VERSION "created by canmatrix"

NS_ :

BS_:

BU_: RadarFrontCenter DASy MPC3
VAL_TABLE_ Status_AvoidCollision 3 "reserve" 2 "RightAvoid" 1 "LeftAvoid" 0 "None" ;
VAL_TABLE_ LAS_OverspeedWarningOffset 31 "Invalid" 21 "Reserved" 0 "Reserved" ;
VAL_TABLE_ VtiSig_VFC_RRLaneDistance 61 "reserved" 0 "0-12" ;
VAL_TABLE_ ACC_AEBActive 1 "Active" 0 "not Active" ;
VAL_TABLE_ VFC_ELKActiveSide 3 "RESERVED" 2 "SIDE_RI" 1 "SIDE_LE" 0 "SIDE_UNDEF" ;
VAL_TABLE_ RDR_Stat_Avail 15 "All function not available" 14 "TIPL&Traj&ongoing not available" 13 "TIPL&Traj&oncom not available" 12 "TIPL&Traj not available" 11 "TIPL&oncoming&ongo not available" 10 "Tipl&ongoing not available" 9 "Tipl&oncoming not available" 8 "TiPl not available" 7 "Traj&oncom&ongoing not available" 6 "Traj&Ongoing not available" 5 "Traj&Oncoming not available" 4 "TrajPoint not available" 3 "OnCom&Ongo obj not available" 2 "Ongoing obj not available" 1 "OnComing obj not available" 0 "Available" ;
VAL_TABLE_ VFC_SensorState_SWVersion 3 "reserved" 2 "unknown" 1 "above 150" 0 "FV150" ;

BO_ 3221225472 VECTOR__INDEPENDENT_SIG_MSG: 0 Vector__XXX
 SG_ CrDrLeInnrACRC : 0|8@1+ (1,0) [0|255] "" Vector__XXX
 SG_ CrDrLeInnrAMsgCtr : 0|4@1+ (1,0) [0|15] "" Vector__XXX
 SG_ CrDrLeInnrAblockCtr : 0|4@1+ (1,0) [0|15] "" Vector__XXX
 SG_ CrDrLeInnrCurvature : 0|12@1+ (1,-2047) [-2047|2048] "per_meter" Vector__XXX
 SG_ CrDrLeInnrCurvChange : 0|12@1+ (1,-2047) [-2047|2048] "per_square_meter" Vector__XXX
 SG_ CrDrLeInnrdxEnd : 0|9@1+ (0.25,0) [0|127.75] "Unit_Meter" Vector__XXX
 SG_ CrDrLeInnrBCRC : 0|8@1+ (1,0) [0|255] "" Vector__XXX
 SG_ CrDrLeInnrBMsgCtr : 0|4@1+ (1,0) [0|15] "" Vector__XXX
 SG_ CrDrLeInnrBblockCtr : 0|4@1+ (1,0) [0|15] "" Vector__XXX
 SG_ CrDrLeInnrdy : 0|12@1+ (0.00390625,-8) [-8|7.99609375] "Unit_Meter" Vector__XXX
 SG_ CrDrLeInnrYawAngleDiff : 0|12@1+ (0.000488281,-1) [-1|0.99951171875] "Radia" Vector__XXX
 SG_ CrDrLeInnr_existence_prob : 0|6@1+ (0.015625,0) [0|0.984375] "" Vector__XXX
 SG_ CrDrLeOutrACRC : 0|8@1+ (1,0) [0|255] "" Vector__XXX
 SG_ CrDrLeOutrAMsgCtr : 0|4@1+ (1,0) [0|15] "" Vector__XXX
 SG_ CrDrLeOutrAblockCtr : 0|4@1+ (1,0) [0|15] "" Vector__XXX
 SG_ CrDrLeOutrCurvature : 0|12@1+ (1,-2047) [-2047|2048] "per_meter" Vector__XXX
 SG_ CrDrLeOutrCurvChange : 0|12@1+ (1,-2047) [-2047|2048] "per_square_meter" Vector__XXX
 SG_ CrDrLeOutrdxEnd : 0|9@1+ (0.25,0) [0|127.75] "Unit_Meter" Vector__XXX
 SG_ CrDrLeOutrBCRC : 0|8@1+ (1,0) [0|255] "" Vector__XXX
 SG_ CrDrLeOutrBMsgCtr : 0|4@1+ (1,0) [0|15] "" Vector__XXX
 SG_ CrDrLeOutrBblockCtr : 0|4@1+ (1,0) [0|15] "" Vector__XXX
 SG_ CrDrLeOutrdy : 0|12@1+ (0.00390625,-8) [-8|7.99609375] "Unit_Meter" Vector__XXX
 SG_ CrDrLeOutrYawAngleDiff : 0|12@1+ (0.000488281,-1) [-1|0.99951171875] "Radia" Vector__XXX
 SG_ CrDrLeOutr_existence_prob : 0|6@1+ (0.015625,0) [0|0.984375] "" Vector__XXX
 SG_ CrDrRiInnrACRC : 0|8@1+ (1,0) [0|255] "" Vector__XXX
 SG_ CrDrRiInnrAMsgCtr : 0|4@1+ (1,0) [0|15] "" Vector__XXX
 SG_ CrDrRiInnrAblockCtr : 0|4@1+ (1,0) [0|15] "" Vector__XXX
 SG_ CrDrRiInnrCurvature : 0|12@1+ (1,-2047) [-2047|2048] "per_meter" Vector__XXX
 SG_ CrDrRiInnrCurvChange : 0|12@1+ (1,-2047) [-2047|2048] "per_square_meter" Vector__XXX
 SG_ CrDrRiInnrdxEnd : 0|9@1+ (0.25,0) [0|127.75] "Unit_Meter" Vector__XXX
 SG_ CrDrRiInnrBCRC : 0|8@1+ (1,0) [0|255] "" Vector__XXX
 SG_ CrDrRiInnrBMsgCtr : 0|4@1+ (1,0) [0|15] "" Vector__XXX
 SG_ CrDrRiInnrBblockCtr : 0|4@1+ (1,0) [0|15] "" Vector__XXX
 SG_ CrDrRiInnrdy : 0|12@1+ (0.00390625,-8) [-8|7.99609375] "Unit_Meter" Vector__XXX
 SG_ CrDrRiInnrYawAngleDiff : 0|12@1+ (0.000488281,-1) [-1|0.99951171875] "Radia" Vector__XXX
 SG_ CrDrRiInnr_existence_prob : 0|6@1+ (0.015625,0) [0|0.984375] "" Vector__XXX
 SG_ CrDrRiOutrACRC : 0|8@1+ (1,0) [0|255] "" Vector__XXX
 SG_ CrDrRiOutrAMsgCtr : 0|4@1+ (1,0) [0|15] "" Vector__XXX
 SG_ CrDrRiOutrAblockCtr : 0|4@1+ (1,0) [0|15] "" Vector__XXX
 SG_ CrDrRiOutrCurvature : 0|12@1+ (1,-2047) [-2047|2048] "per_meter" Vector__XXX
 SG_ CrDrRiOutrCurvChange : 0|12@1+ (1,-2047) [-2047|2048] "per_square_meter" Vector__XXX
 SG_ CrDrRiOutrdxEnd : 0|9@1+ (0.25,0) [0|127.75] "Unit_Meter" Vector__XXX
 SG_ CrDrRiOutrBCRC : 0|8@1+ (1,0) [0|255] "" Vector__XXX
 SG_ CrDrRiOutrBMsgCtr : 0|4@1+ (1,0) [0|15] "" Vector__XXX
 SG_ CrDrRiOutrBblockCtr : 0|4@1+ (1,0) [0|15] "" Vector__XXX
 SG_ CrDrRiOutrdy : 0|12@1+ (0.00390625,-8) [-8|7.99609375] "Unit_Meter" Vector__XXX
 SG_ CrDrRiOutrYawAngleDiff : 0|12@1+ (0.000488281,-1) [-1|0.99951171875] "Radia" Vector__XXX
 SG_ CrDrRiOutr_existence_prob : 0|6@1+ (0.015625,0) [0|0.984375] "" Vector__XXX
 SG_ TargetTrajBCRC : 0|8@1+ (1,0) [0|255] "" Vector__XXX
 SG_ TargetTrajBMsgCtr : 0|4@1+ (1,0) [0|15] "" Vector__XXX
 SG_ TargetTrajBblockCtr : 0|4@1+ (1,0) [0|15] "" Vector__XXX
 SG_ TargetTrajExistnceProb : 0|6@1+ (0.015625,0) [0|0.984375] "" Vector__XXX
 SG_ TargetTrajYawAngleDiff : 0|12@1+ (0.000488281,-1) [-1|0.99951171875] "Radia" Vector__XXX
 SG_ TargetTrajDy : 0|12@1+ (0.00390625,-8) [-8|7.99609375] "Unit_Meter" Vector__XXX
 SG_ RDR_Oncoming_Obj_ChkSum : 0|8@1+ (1,0) [0|255] "" Vector__XXX
 SG_ RDR_OncomingObj_MsgCnt : 0|4@1+ (1,0) [0|15] "" Vector__XXX
 SG_ RDR_OncomingObj_BlockCnt : 0|4@1+ (1,0) [0|15] "" Vector__XXX
 SG_ RDR_Obj_02_dWidth : 0|5@1+ (0.1,0) [0|3.1] "" Vector__XXX
 SG_ RDR_Obj_03_dWidth : 0|5@1+ (0.1,0) [0|3.1] "" Vector__XXX
 SG_ RDR_Obj_04_dWidth : 0|5@1+ (0.1,0) [0|3.1] "" Vector__XXX
 SG_ RDR_Obj_05_dWidth : 0|5@1+ (0.1,0) [0|3.1] "" Vector__XXX
 SG_ VFC_MapInfo_CRC : 0|16@1+ (1,0) [0|65535] "" Vector__XXX
 SG_ VFC_MapInfo_RoadCurv : 0|12@1+ (2E-005,-0.04094) [-0.04094|0.04096] "1/m" Vector__XXX
 SG_ VFC_MapInfo_CountryCode : 0|10@1+ (1,0) [0|1023] "" Vector__XXX
 SG_ VFC_MapInfo_AliveCtr : 0|8@1+ (1,0) [0|255] "" Vector__XXX
 SG_ VFC_MapInfo_RoadClass_Offset0 : 0|3@1+ (1,0) [0|7] "" Vector__XXX
 SG_ VFC_MapInfo_RoadClass_Offset200 : 0|3@1+ (1,0) [0|7] "" Vector__XXX
 SG_ VFC_MapInfo_DiRoad_Offset0 : 0|2@1+ (1,0) [0|3] "" Vector__XXX
 SG_ VFC_MapInfo_LaneNum_Offset0 : 0|3@1+ (1,0) [0|7] "" Vector__XXX
 SG_ VFC_MapInfo_LaneNum_Offset200 : 0|3@1+ (1,0) [0|7] "" Vector__XXX
 SG_ VFC_MapInfo_DiRoad_Offset200 : 0|2@1+ (1,0) [0|3] "" Vector__XXX
 SG_ VFC_MapInfo_TollGate_Dx : 0|10@1+ (1,0) [0|1023] "m" Vector__XXX
 SG_ VFC_MapInfo_TollGate : 0|2@1+ (1,0) [0|3] "" Vector__XXX
 SG_ VFC_MapInfo_CurrentLane : 0|3@1+ (1,0) [0|7] "" Vector__XXX
 SG_ VFC_MapInfo_Tunnel_Dx : 0|10@1+ (1,0) [0|1023] "m" Vector__XXX
 SG_ VFC_MapInfo_Tunnel : 0|2@1+ (1,0) [0|3] "" Vector__XXX
 SG_ VFC_MapInfo_Bridge_Dx : 0|10@1+ (1,0) [0|1023] "m" Vector__XXX
 SG_ VFC_MapInfo_Bridge : 0|2@1+ (1,0) [0|3] "" Vector__XXX
 SG_ VFC_MapInfo_BuildUp_Dx : 0|10@1+ (1,0) [0|1023] "m" Vector__XXX
 SG_ VFC_MapInfo_BuildUp : 0|2@1+ (1,0) [0|3] "" Vector__XXX

BO_ 0 New_Message_104: 8 Vector__XXX
 SG_ New_Signal_2281 : 55|8@1+ (1,0) [0|0] "" Vector__XXX

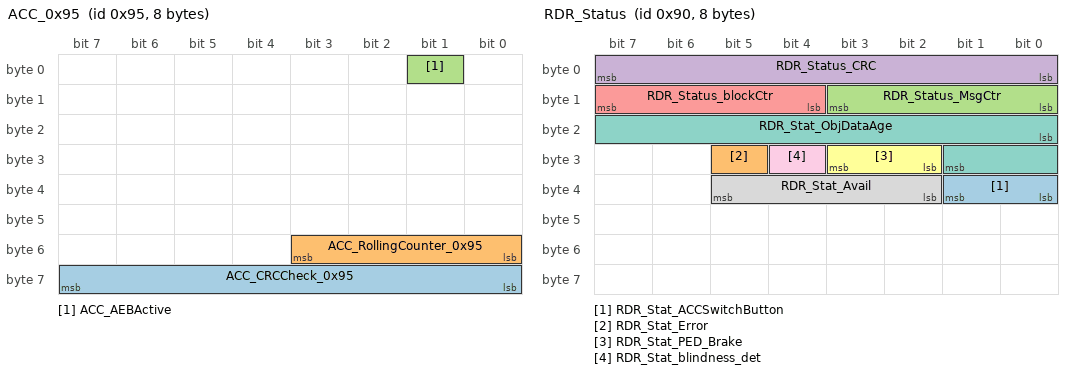
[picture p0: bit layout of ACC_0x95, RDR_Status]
BO_ 149 ACC_0x95: 8 RadarFrontCenter
 SG_ ACC_CRCCheck_0x95 : 63|8@0+ (1,0) [0|255] ""  MPC3
 SG_ ACC_RollingCounter_0x95 : 51|4@0+ (1,0) [0|15] ""  MPC3
 SG_ ACC_AEBActive : 1|1@0+ (1,0) [0|1] ""  MPC3

BO_ 144 RDR_Status: 8 RadarFrontCenter
 SG_ RDR_Stat_ACCSwitchButton : 32|2@1+ (1,0) [0|3] ""  MPC3
 SG_ RDR_Stat_Error : 29|1@1+ (1,0) [0|1] ""  MPC3
 SG_ RDR_Status_MsgCtr : 8|4@1+ (1,0) [0|15] ""  MPC3
 SG_ RDR_Status_CRC : 0|8@1+ (1,0) [0|255] ""  MPC3
 SG_ RDR_Status_blockCtr : 12|4@1+ (1,0) [0|15] ""  MPC3
 SG_ RDR_Stat_PED_Brake : 26|2@1+ (1,0) [0|3] ""  MPC3
 SG_ RDR_Stat_ObjDataAge : 16|10@1+ (0.0009765625,0) [0|0.9990234375] ""  MPC3
 SG_ RDR_Stat_Avail : 34|4@1+ (1,0) [0|15] ""  MPC3
 SG_ RDR_Stat_blindness_det : 28|1@1+ (1,0) [0|1] ""  MPC3

BO_ 80 VFC_SensorState: 12 MPC3
 SG_ VFC_SensorState_SWVersion : 70|2@1+ (1,0) [0|3] ""  RadarFrontCenter
 SG_ VFC_SensorState_CRC : 0|16@1+ (1,0) [0|65535] ""  RadarFrontCenter,DASy
 SG_ VFC_SensorState_AliveCtr : 16|8@1+ (1,0) [0|255] ""  RadarFrontCenter,DASy
 SG_ VFC_SensorState_BlindnessProb : 24|6@1+ (2,0) [0|100] "%"  RadarFrontCenter,DASy
 SG_ VFC_SensorState_VisionFault : 32|3@1+ (1,0) [0|7] ""  RadarFrontCenter,DASy
 SG_ VFC_SensorState_VisionDTCs : 35|3@1+ (1,0) [0|7] ""  RadarFrontCenter,DASy
 SG_ VFC_SensorState_Status : 40|3@1+ (1,0) [0|7] ""  RadarFrontCenter,DASy
 SG_ VFC_SensorState_ProtocolVersion : 48|16@1+ (1,0) [0|65535] ""  RadarFrontCenter,DASy
 SG_ VFC_SensorState_Report : 64|6@1+ (1,0) [0|63] ""  RadarFrontCenter,DASy

BO_ 128 VFC_LineHeader: 16 MPC3
 SG_ VFC_LineHdr_CRC : 0|16@1+ (1,0) [0|65535] ""  RadarFrontCenter,DASy
 SG_ VFC_LineHdr_AliveCtr : 16|8@1+ (1,0) [0|255] ""  RadarFrontCenter,DASy
 SG_ VFC_LineHdr_BlockCounter : 24|4@1+ (1,0) [0|15] ""  RadarFrontCenter,DASy
 SG_ VFC_LineHdr_FrameNo : 28|4@1+ (1,0) [0|15] ""  RadarFrontCenter,DASy
 SG_ VFC_LineHdr_Report : 32|8@1+ (1,0) [0|255] ""  RadarFrontCenter,DASy
 SG_ VFC_LineHdr_LineCount : 40|8@1+ (1,0) [0|255] ""  RadarFrontCenter,DASy
 SG_ VFC_LineHdr_PEPSIRuntime : 48|8@1+ (0.05,0) [0|10] "ms"  RadarFrontCenter,DASy
 SG_ VFC_LineHdr_TimeStamp : 56|26@1+ (1,0) [0|67108863] "ms"  RadarFrontCenter,DASy
 SG_ VFC_LineHdr_Blindness : 82|6@1+ (2,0) [0|100] "%"  RadarFrontCenter,DASy
 SG_ VFC_LineHdr_State : 88|3@1+ (1,0) [0|7] ""  RadarFrontCenter,DASy
 SG_ VFC_LineHdr_AUTOSARTStamp : 96|26@1+ (1,0) [0|67108863] "ms"  RadarFrontCenter,DASy

BO_ 129 VFC_Line01: 32 MPC3
 SG_ VFC_Line01_CRC : 0|16@1+ (1,0) [0|65535] ""  RadarFrontCenter,DASy
 SG_ VFC_Line01_Dy : 104|12@1+ (0.015625,-32) [-32|31.984375] "m"  RadarFrontCenter,DASy
 SG_ VFC_Line01_CurvChange : 116|12@1+ (3.8147E-006,-0.0078125) [-0.0078125|0.0078086965] "1/(m*m)"  RadarFrontCenter,DASy
 SG_ VFC_Line01_Curv : 128|13@1+ (3.8147E-006,-0.015625) [-0.015625|0.0156212077] "1/m"  RadarFrontCenter,DASy
 SG_ VFC_Line01_MeasureType : 141|3@1+ (1,0) [0|3] ""  RadarFrontCenter,DASy
 SG_ VFC_Line01_LineWidth : 144|8@1+ (0.01,0) [0|2.55] "m"  RadarFrontCenter,DASy
 SG_ VFC_Line01_CourseDeviation : 152|10@1+ (0.05,0) [0|50] ""  RadarFrontCenter,DASy
 SG_ VFC_Line01_Type : 162|5@1+ (1,0) [0|31] ""  RadarFrontCenter,DASy
 SG_ VFC_Line01_DyStdDevDxEnd : 167|9@1+ (0.0078125,0) [0|3.9921875] "m"  RadarFrontCenter,DASy
 SG_ VFC_Line01_AliveCtr : 16|8@1+ (1,0) [0|255] ""  RadarFrontCenter,DASy
 SG_ VFC_Line01_HypoConfidence : 176|8@1+ (1,0) [0|255] ""  RadarFrontCenter,DASy
 SG_ VFC_Line01_prevID : 184|8@1+ (1,0) [0|255] ""  RadarFrontCenter,DASy
 SG_ VFC_Line01_nextID : 192|8@1+ (1,0) [0|255] ""  RadarFrontCenter,DASy
 SG_ VFC_Line01_DyStdDevDxStart : 200|9@1+ (0.0078125,0) [0|3.9921875] "m"  RadarFrontCenter,DASy
 SG_ VFC_Line01_TypeProb : 209|6@1+ (2,0) [0|100] "%"  RadarFrontCenter,DASy
 SG_ VFC_Line01_DyStdDevDxMid : 215|9@1+ (0.0078125,0) [0|3.9921875] "m"  RadarFrontCenter,DASy
 SG_ VFC_Line01_BlockCounter : 24|4@1+ (1,0) [0|15] ""  RadarFrontCenter,DASy
 SG_ VFC_Line01_ProtOrderIndex : 32|6@1+ (1,0) [0|63] ""  RadarFrontCenter,DASy
 SG_ VFC_Line01_LineID : 40|8@1+ (1,0) [0|255] ""  RadarFrontCenter,DASy
 SG_ VFC_Line01_LaneRelation : 48|8@1+ (1,0) [0|255] ""  RadarFrontCenter,DASy
 SG_ VFC_Line01_ExistProb : 56|6@1+ (2,0) [0|100] "%"  RadarFrontCenter,DASy
 SG_ VFC_Line01_DxStart : 64|13@1+ (0.025,0) [0|204.775] "m"  RadarFrontCenter,DASy
 SG_ VFC_Line01_ColorClass : 77|3@1+ (1,0) [0|7] ""  RadarFrontCenter,DASy
 SG_ VFC_Line01_DxEnd : 80|10@1+ (0.25,0) [0|255.75] "m"  RadarFrontCenter,DASy
 SG_ VFC_Line01_HeadingAngle : 91|13@1+ (0.000488281,-1.6) [-1.6|1.6] "rad"  RadarFrontCenter,DASy

BO_ 130 VFC_Line02: 32 MPC3
 SG_ VFC_Line02_CRC : 0|16@1+ (1,0) [0|65535] ""  RadarFrontCenter,DASy
 SG_ VFC_Line02_Dy : 104|12@1+ (0.015625,-32) [-32|31.984375] "m"  RadarFrontCenter,DASy
 SG_ VFC_Line02_CurvChange : 116|12@1+ (3.8147E-006,-0.0078125) [-0.0078125|0.0078086965] "1/(m*m)"  RadarFrontCenter,DASy
 SG_ VFC_Line02_Curv : 128|13@1+ (3.8147E-006,-0.015625) [-0.015625|0.0156212077] "1/m"  RadarFrontCenter,DASy
 SG_ VFC_Line02_MeasureType : 141|3@1+ (1,0) [0|3] ""  RadarFrontCenter,DASy
 SG_ VFC_Line02_LineWidth : 144|8@1+ (0.01,0) [0|2.55] "m"  RadarFrontCenter,DASy
 SG_ VFC_Line02_CourseDeviation : 152|10@1+ (0.05,0) [0|50] ""  RadarFrontCenter,DASy
 SG_ VFC_Line02_Type : 162|5@1+ (1,0) [0|31] ""  RadarFrontCenter,DASy
 SG_ VFC_Line02_DyStdDevDxEnd : 167|9@1+ (0.0078125,0) [0|3.9921875] "m"  RadarFrontCenter,DASy
 SG_ VFC_Line02_AliveCtr : 16|8@1+ (1,0) [0|255] ""  RadarFrontCenter,DASy
 SG_ VFC_Line02_HypoConfidence : 176|8@1+ (1,0) [0|255] ""  RadarFrontCenter,DASy
 SG_ VFC_Line02_prevID : 184|8@1+ (1,0) [0|255] ""  RadarFrontCenter,DASy
 SG_ VFC_Line02_nextID : 192|8@1+ (1,0) [0|255] ""  RadarFrontCenter,DASy
 SG_ VFC_Line02_DyStdDevDxStart : 200|9@1+ (0.0078125,0) [0|3.9921875] "m"  RadarFrontCenter,DASy
 SG_ VFC_Line02_TypeProb : 209|6@1+ (2,0) [0|100] "%"  RadarFrontCenter,DASy
 SG_ VFC_Line02_DyStdDevDxMid : 215|9@1+ (0.0078125,0) [0|3.9921875] "m"  RadarFrontCenter,DASy
 SG_ VFC_Line02_BlockCounter : 24|4@1+ (1,0) [0|15] ""  RadarFrontCenter,DASy
 SG_ VFC_Line02_ProtOrderIndex : 32|6@1+ (1,0) [0|63] ""  RadarFrontCenter,DASy
 SG_ VFC_Line02_LineID : 40|8@1+ (1,0) [0|255] ""  RadarFrontCenter,DASy
 SG_ VFC_Line02_LaneRelation : 48|8@1+ (1,0) [0|255] ""  RadarFrontCenter,DASy
 SG_ VFC_Line02_ExistProb : 56|6@1+ (2,0) [0|100] "%"  RadarFrontCenter,DASy
 SG_ VFC_Line02_DxStart : 64|13@1+ (0.025,0) [0|204.775] "m"  RadarFrontCenter,DASy
 SG_ VFC_Line02_ColorClass : 77|3@1+ (1,0) [0|7] ""  RadarFrontCenter,DASy
 SG_ VFC_Line02_DxEnd : 80|10@1+ (0.25,0) [0|255.75] "m"  RadarFrontCenter,DASy
 SG_ VFC_Line02_HeadingAngle : 91|13@1+ (0.000488281,-1.6) [-1.6|1.6] "rad"  RadarFrontCenter,DASy

BO_ 131 VFC_Line03: 32 MPC3
 SG_ VFC_Line03_CRC : 0|16@1+ (1,0) [0|65535] ""  RadarFrontCenter,DASy
 SG_ VFC_Line03_Dy : 104|12@1+ (0.015625,-32) [-32|31.984375] "m"  RadarFrontCenter,DASy
 SG_ VFC_Line03_CurvChange : 116|12@1+ (3.8147E-006,-0.0078125) [-0.0078125|0.0078086965] "1/(m*m)"  RadarFrontCenter,DASy
 SG_ VFC_Line03_Curv : 128|13@1+ (3.8147E-006,-0.015625) [-0.015625|0.0156212077] "1/m"  RadarFrontCenter,DASy
 SG_ VFC_Line03_MeasureType : 141|3@1+ (1,0) [0|3] ""  RadarFrontCenter,DASy
 SG_ VFC_Line03_LineWidth : 144|8@1+ (0.01,0) [0|2.55] "m"  RadarFrontCenter,DASy
 SG_ VFC_Line03_CourseDeviation : 152|10@1+ (0.05,0) [0|50] ""  RadarFrontCenter,DASy
 SG_ VFC_Line03_Type : 162|5@1+ (1,0) [0|31] ""  RadarFrontCenter,DASy
 SG_ VFC_Line03_DyStdDevDxEnd : 167|9@1+ (0.0078125,0) [0|3.9921875] "m"  RadarFrontCenter,DASy
 SG_ VFC_Line03_AliveCtr : 16|8@1+ (1,0) [0|255] ""  RadarFrontCenter,DASy
 SG_ VFC_Line03_HypoConfidence : 176|8@1+ (1,0) [0|255] ""  RadarFrontCenter,DASy
 SG_ VFC_Line03_prevID : 184|8@1+ (1,0) [0|255] ""  RadarFrontCenter,DASy
 SG_ VFC_Line03_nextID : 192|8@1+ (1,0) [0|255] ""  RadarFrontCenter,DASy
 SG_ VFC_Line03_DyStdDevDxStart : 200|9@1+ (0.0078125,0) [0|3.9921875] "m"  RadarFrontCenter,DASy
 SG_ VFC_Line03_TypeProb : 209|6@1+ (2,0) [0|100] "%"  RadarFrontCenter,DASy
 SG_ VFC_Line03_DyStdDevDxMid : 215|9@1+ (0.0078125,0) [0|3.9921875] "m"  RadarFrontCenter,DASy
 SG_ VFC_Line03_BlockCounter : 24|4@1+ (1,0) [0|15] ""  RadarFrontCenter,DASy
 SG_ VFC_Line03_ProtOrderIndex : 32|6@1+ (1,0) [0|63] ""  RadarFrontCenter,DASy
 SG_ VFC_Line03_LineID : 40|8@1+ (1,0) [0|255] ""  RadarFrontCenter,DASy
 SG_ VFC_Line03_LaneRelation : 48|8@1+ (1,0) [0|255] ""  RadarFrontCenter,DASy
 SG_ VFC_Line03_ExistProb : 56|6@1+ (2,0) [0|100] "%"  RadarFrontCenter,DASy
 SG_ VFC_Line03_DxStart : 64|13@1+ (0.025,0) [0|204.775] "m"  RadarFrontCenter,DASy
 SG_ VFC_Line03_ColorClass : 77|3@1+ (1,0) [0|7] ""  RadarFrontCenter,DASy
 SG_ VFC_Line03_DxEnd : 80|10@1+ (0.25,0) [0|255.75] "m"  RadarFrontCenter,DASy
 SG_ VFC_Line03_HeadingAngle : 91|13@1+ (0.000488281,-1.6) [-1.6|1.6] "rad"  RadarFrontCenter,DASy

BO_ 132 VFC_Line04: 32 MPC3
 SG_ VFC_Line04_CRC : 0|16@1+ (1,0) [0|65535] ""  RadarFrontCenter,DASy
 SG_ VFC_Line04_Dy : 104|12@1+ (0.015625,-32) [-32|31.984375] "m"  RadarFrontCenter,DASy
 SG_ VFC_Line04_CurvChange : 116|12@1+ (3.8147E-006,-0.0078125) [-0.0078125|0.0078086965] "1/(m*m)"  RadarFrontCenter,DASy
 SG_ VFC_Line04_Curv : 128|13@1+ (3.8147E-006,-0.015625) [-0.015625|0.0156212077] "1/m"  RadarFrontCenter,DASy
 SG_ VFC_Line04_MeasureType : 141|3@1+ (1,0) [0|3] ""  RadarFrontCenter,DASy
 SG_ VFC_Line04_LineWidth : 144|8@1+ (0.01,0) [0|2.55] "m"  RadarFrontCenter,DASy
 SG_ VFC_Line04_CourseDeviation : 152|10@1+ (0.05,0) [0|50] ""  RadarFrontCenter,DASy
 SG_ VFC_Line04_Type : 162|5@1+ (1,0) [0|31] ""  RadarFrontCenter,DASy
 SG_ VFC_Line04_DyStdDevDxEnd : 167|9@1+ (0.0078125,0) [0|3.9921875] "m"  RadarFrontCenter,DASy
 SG_ VFC_Line04_AliveCtr : 16|8@1+ (1,0) [0|255] ""  RadarFrontCenter,DASy
 SG_ VFC_Line04_HypoConfidence : 176|8@1+ (1,0) [0|255] ""  RadarFrontCenter,DASy
 SG_ VFC_Line04_prevID : 184|8@1+ (1,0) [0|255] ""  RadarFrontCenter,DASy
 SG_ VFC_Line04_nextID : 192|8@1+ (1,0) [0|255] ""  RadarFrontCenter,DASy
 SG_ VFC_Line04_DyStdDevDxStart : 200|9@1+ (0.0078125,0) [0|3.9921875] "m"  RadarFrontCenter,DASy
 SG_ VFC_Line04_TypeProb : 209|6@1+ (2,0) [0|100] "%"  RadarFrontCenter,DASy
 SG_ VFC_Line04_DyStdDevDxMid : 215|9@1+ (0.0078125,0) [0|3.9921875] "m"  RadarFrontCenter,DASy
 SG_ VFC_Line04_BlockCounter : 24|4@1+ (1,0) [0|15] ""  RadarFrontCenter,DASy
 SG_ VFC_Line04_ProtOrderIndex : 32|6@1+ (1,0) [0|63] ""  RadarFrontCenter,DASy
 SG_ VFC_Line04_LineID : 40|8@1+ (1,0) [0|255] ""  RadarFrontCenter,DASy
 SG_ VFC_Line04_LaneRelation : 48|8@1+ (1,0) [0|255] ""  RadarFrontCenter,DASy
 SG_ VFC_Line04_ExistProb : 56|6@1+ (2,0) [0|100] "%"  RadarFrontCenter,DASy
 SG_ VFC_Line04_DxStart : 64|13@1+ (0.025,0) [0|204.775] "m"  RadarFrontCenter,DASy
 SG_ VFC_Line04_ColorClass : 77|3@1+ (1,0) [0|7] ""  RadarFrontCenter,DASy
 SG_ VFC_Line04_DxEnd : 80|10@1+ (0.25,0) [0|255.75] "m"  RadarFrontCenter,DASy
 SG_ VFC_Line04_HeadingAngle : 91|13@1+ (0.000488281,-1.6) [-1.6|1.6] "rad"  RadarFrontCenter,DASy

BO_ 133 VFC_Line05: 32 MPC3
 SG_ VFC_Line05_CRC : 0|16@1+ (1,0) [0|65535] ""  RadarFrontCenter,DASy
 SG_ VFC_Line05_Dy : 104|12@1+ (0.015625,-32) [-32|31.984375] "m"  RadarFrontCenter,DASy
 SG_ VFC_Line05_CurvChange : 116|12@1+ (3.8147E-006,-0.0078125) [-0.0078125|0.0078086965] "1/(m*m)"  RadarFrontCenter,DASy
 SG_ VFC_Line05_Curv : 128|13@1+ (3.8147E-006,-0.015625) [-0.015625|0.0156212077] "1/m"  RadarFrontCenter,DASy
 SG_ VFC_Line05_MeasureType : 141|3@1+ (1,0) [0|3] ""  RadarFrontCenter,DASy
 SG_ VFC_Line05_LineWidth : 144|8@1+ (0.01,0) [0|2.55] "m"  RadarFrontCenter,DASy
 SG_ VFC_Line05_CourseDeviation : 152|10@1+ (0.05,0) [0|50] ""  RadarFrontCenter,DASy
 SG_ VFC_Line05_Type : 162|5@1+ (1,0) [0|31] ""  RadarFrontCenter,DASy
 SG_ VFC_Line05_DyStdDevDxEnd : 167|9@1+ (0.0078125,0) [0|3.9921875] "m"  RadarFrontCenter,DASy
 SG_ VFC_Line05_AliveCtr : 16|8@1+ (1,0) [0|255] ""  RadarFrontCenter,DASy
 SG_ VFC_Line05_HypoConfidence : 176|8@1+ (1,0) [0|255] ""  RadarFrontCenter,DASy
 SG_ VFC_Line05_prevID : 184|8@1+ (1,0) [0|255] ""  RadarFrontCenter,DASy
 SG_ VFC_Line05_nextID : 192|8@1+ (1,0) [0|255] ""  RadarFrontCenter,DASy
 SG_ VFC_Line05_DyStdDevDxStart : 200|9@1+ (0.0078125,0) [0|3.9921875] "m"  RadarFrontCenter,DASy
 SG_ VFC_Line05_TypeProb : 209|6@1+ (2,0) [0|100] "%"  RadarFrontCenter,DASy
 SG_ VFC_Line05_DyStdDevDxMid : 215|9@1+ (0.0078125,0) [0|3.9921875] "m"  RadarFrontCenter,DASy
 SG_ VFC_Line05_BlockCounter : 24|4@1+ (1,0) [0|15] ""  RadarFrontCenter,DASy
 SG_ VFC_Line05_ProtOrderIndex : 32|6@1+ (1,0) [0|63] ""  RadarFrontCenter,DASy
 SG_ VFC_Line05_LineID : 40|8@1+ (1,0) [0|255] ""  RadarFrontCenter,DASy
 SG_ VFC_Line05_LaneRelation : 48|8@1+ (1,0) [0|255] ""  RadarFrontCenter,DASy
 SG_ VFC_Line05_ExistProb : 56|6@1+ (2,0) [0|100] "%"  RadarFrontCenter,DASy
 SG_ VFC_Line05_DxStart : 64|13@1+ (0.025,0) [0|204.775] "m"  RadarFrontCenter,DASy
 SG_ VFC_Line05_ColorClass : 77|3@1+ (1,0) [0|7] ""  RadarFrontCenter,DASy
 SG_ VFC_Line05_DxEnd : 80|10@1+ (0.25,0) [0|255.75] "m"  RadarFrontCenter,DASy
 SG_ VFC_Line05_HeadingAngle : 91|13@1+ (0.000488281,-1.6) [-1.6|1.6] "rad"  RadarFrontCenter,DASy

BO_ 134 VFC_Line06: 32 MPC3
 SG_ VFC_Line06_CRC : 0|16@1+ (1,0) [0|65535] ""  RadarFrontCenter,DASy
 SG_ VFC_Line06_Dy : 104|12@1+ (0.015625,-32) [-32|31.984375] "m"  RadarFrontCenter,DASy
 SG_ VFC_Line06_CurvChange : 116|12@1+ (3.8147E-006,-0.0078125) [-0.0078125|0.0078086965] "1/(m*m)"  RadarFrontCenter,DASy
 SG_ VFC_Line06_Curv : 128|13@1+ (3.8147E-006,-0.015625) [-0.015625|0.0156212077] "1/m"  RadarFrontCenter,DASy
 SG_ VFC_Line06_MeasureType : 141|3@1+ (1,0) [0|3] ""  RadarFrontCenter,DASy
 SG_ VFC_Line06_LineWidth : 144|8@1+ (0.01,0) [0|2.55] "m"  RadarFrontCenter,DASy
 SG_ VFC_Line06_CourseDeviation : 152|10@1+ (0.05,0) [0|50] ""  RadarFrontCenter,DASy
 SG_ VFC_Line06_Type : 162|5@1+ (1,0) [0|31] ""  RadarFrontCenter,DASy
 SG_ VFC_Line06_DyStdDevDxEnd : 167|9@1+ (0.0078125,0) [0|3.9921875] "m"  RadarFrontCenter,DASy
 SG_ VFC_Line06_AliveCtr : 16|8@1+ (1,0) [0|255] ""  RadarFrontCenter,DASy
 SG_ VFC_Line06_HypoConfidence : 176|8@1+ (1,0) [0|255] ""  RadarFrontCenter,DASy
 SG_ VFC_Line06_prevID : 184|8@1+ (1,0) [0|255] ""  RadarFrontCenter,DASy
 SG_ VFC_Line06_nextID : 192|8@1+ (1,0) [0|255] ""  RadarFrontCenter,DASy
 SG_ VFC_Line06_DyStdDevDxStart : 200|9@1+ (0.0078125,0) [0|3.9921875] "m"  RadarFrontCenter,DASy
 SG_ VFC_Line06_TypeProb : 209|6@1+ (2,0) [0|100] "%"  RadarFrontCenter,DASy
 SG_ VFC_Line06_DyStdDevDxMid : 215|9@1+ (0.0078125,0) [0|3.9921875] "m"  RadarFrontCenter,DASy
 SG_ VFC_Line06_BlockCounter : 24|4@1+ (1,0) [0|15] ""  RadarFrontCenter,DASy
 SG_ VFC_Line06_ProtOrderIndex : 32|6@1+ (1,0) [0|63] ""  RadarFrontCenter,DASy
 SG_ VFC_Line06_LineID : 40|8@1+ (1,0) [0|255] ""  RadarFrontCenter,DASy
 SG_ VFC_Line06_LaneRelation : 48|8@1+ (1,0) [0|255] ""  RadarFrontCenter,DASy
 SG_ VFC_Line06_ExistProb : 56|6@1+ (2,0) [0|100] "%"  RadarFrontCenter,DASy
 SG_ VFC_Line06_DxStart : 64|13@1+ (0.025,0) [0|204.775] "m"  RadarFrontCenter,DASy
 SG_ VFC_Line06_ColorClass : 77|3@1+ (1,0) [0|7] ""  RadarFrontCenter,DASy
 SG_ VFC_Line06_DxEnd : 80|10@1+ (0.25,0) [0|255.75] "m"  RadarFrontCenter,DASy
 SG_ VFC_Line06_HeadingAngle : 91|13@1+ (0.000488281,-1.6) [-1.6|1.6] "rad"  RadarFrontCenter,DASy

BO_ 135 VFC_Line07: 32 MPC3
 SG_ VFC_Line07_CRC : 0|16@1+ (1,0) [0|65535] ""  RadarFrontCenter,DASy
 SG_ VFC_Line07_Dy : 104|12@1+ (0.015625,-32) [-32|31.984375] "m"  RadarFrontCenter,DASy
 SG_ VFC_Line07_CurvChange : 116|12@1+ (3.8147E-006,-0.0078125) [-0.0078125|0.0078086965] "1/(m*m)"  RadarFrontCenter,DASy
 SG_ VFC_Line07_Curv : 128|13@1+ (3.8147E-006,-0.015625) [-0.015625|0.0156212077] "1/m"  RadarFrontCenter,DASy
 SG_ VFC_Line07_MeasureType : 141|3@1+ (1,0) [0|3] ""  RadarFrontCenter,DASy
 SG_ VFC_Line07_LineWidth : 144|8@1+ (0.01,0) [0|2.55] "m"  RadarFrontCenter,DASy
 SG_ VFC_Line07_CourseDeviation : 152|10@1+ (0.05,0) [0|50] ""  RadarFrontCenter,DASy
 SG_ VFC_Line07_Type : 162|5@1+ (1,0) [0|31] ""  RadarFrontCenter,DASy
 SG_ VFC_Line07_DyStdDevDxEnd : 167|9@1+ (0.0078125,0) [0|3.9921875] "m"  RadarFrontCenter,DASy
 SG_ VFC_Line07_AliveCtr : 16|8@1+ (1,0) [0|255] ""  RadarFrontCenter,DASy
 SG_ VFC_Line07_HypoConfidence : 176|8@1+ (1,0) [0|255] ""  RadarFrontCenter,DASy
 SG_ VFC_Line07_prevID : 184|8@1+ (1,0) [0|255] ""  RadarFrontCenter,DASy
 SG_ VFC_Line07_nextID : 192|8@1+ (1,0) [0|255] ""  RadarFrontCenter,DASy
 SG_ VFC_Line07_DyStdDevDxStart : 200|9@1+ (0.0078125,0) [0|3.9921875] "m"  RadarFrontCenter,DASy
 SG_ VFC_Line07_TypeProb : 209|6@1+ (2,0) [0|100] "%"  RadarFrontCenter,DASy
 SG_ VFC_Line07_DyStdDevDxMid : 215|9@1+ (0.0078125,0) [0|3.9921875] "m"  RadarFrontCenter,DASy
 SG_ VFC_Line07_BlockCounter : 24|4@1+ (1,0) [0|15] ""  RadarFrontCenter,DASy
 SG_ VFC_Line07_ProtOrderIndex : 32|6@1+ (1,0) [0|63] ""  RadarFrontCenter,DASy
 SG_ VFC_Line07_LineID : 40|8@1+ (1,0) [0|255] ""  RadarFrontCenter,DASy
 SG_ VFC_Line07_LaneRelation : 48|8@1+ (1,0) [0|255] ""  RadarFrontCenter,DASy
 SG_ VFC_Line07_ExistProb : 56|6@1+ (2,0) [0|100] "%"  RadarFrontCenter,DASy
 SG_ VFC_Line07_DxStart : 64|13@1+ (0.025,0) [0|204.775] "m"  RadarFrontCenter,DASy
 SG_ VFC_Line07_ColorClass : 77|3@1+ (1,0) [0|7] ""  RadarFrontCenter,DASy
 SG_ VFC_Line07_DxEnd : 80|10@1+ (0.25,0) [0|255.75] "m"  RadarFrontCenter,DASy
 SG_ VFC_Line07_HeadingAngle : 91|13@1+ (0.000488281,-1.6) [-1.6|1.6] "rad"  RadarFrontCenter,DASy

BO_ 136 VFC_Line08: 32 MPC3
 SG_ VFC_Line08_CRC : 0|16@1+ (1,0) [0|65535] ""  RadarFrontCenter,DASy
 SG_ VFC_Line08_Dy : 104|12@1+ (0.015625,-32) [-32|31.984375] "m"  RadarFrontCenter,DASy
 SG_ VFC_Line08_CurvChange : 116|12@1+ (3.8147E-006,-0.0078125) [-0.0078125|0.0078086965] "1/(m*m)"  RadarFrontCenter,DASy
 SG_ VFC_Line08_Curv : 128|13@1+ (3.8147E-006,-0.015625) [-0.015625|0.0156212077] "1/m"  RadarFrontCenter,DASy
 SG_ VFC_Line08_MeasureType : 141|3@1+ (1,0) [0|3] ""  RadarFrontCenter,DASy
 SG_ VFC_Line08_LineWidth : 144|8@1+ (0.01,0) [0|2.55] "m"  RadarFrontCenter,DASy
 SG_ VFC_Line08_CourseDeviation : 152|10@1+ (0.05,0) [0|50] ""  RadarFrontCenter,DASy
 SG_ VFC_Line08_Type : 162|5@1+ (1,0) [0|31] ""  RadarFrontCenter,DASy
 SG_ VFC_Line08_DyStdDevDxEnd : 167|9@1+ (0.0078125,0) [0|3.9921875] "m"  RadarFrontCenter,DASy
 SG_ VFC_Line08_AliveCtr : 16|8@1+ (1,0) [0|255] ""  RadarFrontCenter,DASy
 SG_ VFC_Line08_HypoConfidence : 176|8@1+ (1,0) [0|255] ""  RadarFrontCenter,DASy
 SG_ VFC_Line08_prevID : 184|8@1+ (1,0) [0|255] ""  RadarFrontCenter,DASy
 SG_ VFC_Line08_nextID : 192|8@1+ (1,0) [0|255] ""  RadarFrontCenter,DASy
 SG_ VFC_Line08_DyStdDevDxStart : 200|9@1+ (0.0078125,0) [0|3.9921875] "m"  RadarFrontCenter,DASy
 SG_ VFC_Line08_TypeProb : 209|6@1+ (2,0) [0|100] "%"  RadarFrontCenter,DASy
 SG_ VFC_Line08_DyStdDevDxMid : 215|9@1+ (0.0078125,0) [0|3.9921875] "m"  RadarFrontCenter,DASy
 SG_ VFC_Line08_BlockCounter : 24|4@1+ (1,0) [0|15] ""  RadarFrontCenter,DASy
 SG_ VFC_Line08_ProtOrderIndex : 32|6@1+ (1,0) [0|63] ""  RadarFrontCenter,DASy
 SG_ VFC_Line08_LineID : 40|8@1+ (1,0) [0|255] ""  RadarFrontCenter,DASy
 SG_ VFC_Line08_LaneRelation : 48|8@1+ (1,0) [0|255] ""  RadarFrontCenter,DASy
 SG_ VFC_Line08_ExistProb : 56|6@1+ (2,0) [0|100] "%"  RadarFrontCenter,DASy
 SG_ VFC_Line08_DxStart : 64|13@1+ (0.025,0) [0|204.775] "m"  RadarFrontCenter,DASy
 SG_ VFC_Line08_ColorClass : 77|3@1+ (1,0) [0|7] ""  RadarFrontCenter,DASy
 SG_ VFC_Line08_DxEnd : 80|10@1+ (0.25,0) [0|255.75] "m"  RadarFrontCenter,DASy
 SG_ VFC_Line08_HeadingAngle : 91|13@1+ (0.000488281,-1.6) [-1.6|1.6] "rad"  RadarFrontCenter,DASy

BO_ 160 VFC_ObjectHdr: 32 MPC3
 SG_ VFC_ObjHdr_Scenario : 109|3@1+ (1,0) [0|7] "" Vector__XXX
 SG_ VFC_ObjHdr_CRC : 0|16@1+ (1,0) [0|65535] ""  RadarFrontCenter,DASy
 SG_ VFC_ObjHdr_CalibRollStdDev : 112|9@1+ (0.0005,0) [0|0.25] "rad"  RadarFrontCenter,DASy
 SG_ VFC_ObjHdr_CalibYawAngle : 128|10@1+ (0.0005,-0.2) [-0.2|0.2] "rad"  RadarFrontCenter,DASy
 SG_ VFC_ObjHdr_CalibYawStdDev : 144|9@1+ (0.0005,0) [0|0.25] "rad"  RadarFrontCenter,DASy
 SG_ VFC_ObjHdr_MountPosX : 160|13@1+ (0.001,-4) [-4|4] "m"  RadarFrontCenter,DASy
 SG_ VFC_ObjHdr_AliveCtr : 16|8@1+ (1,0) [0|255] ""  RadarFrontCenter,DASy
 SG_ VFC_ObjHdr_CalibState : 173|3@1+ (1,0) [0|7] ""  RadarFrontCenter,DASy
 SG_ VFC_ObjHdr_MountPosY : 176|12@1+ (0.001,-2) [-2|2] "m"  RadarFrontCenter,DASy
 SG_ VFC_ObjHdr_MountPosZ : 192|11@1+ (0.001,0) [0|2] "m"  RadarFrontCenter,DASy
 SG_ VFC_ObjHdr_CycleTime : 208|10@1+ (0.001,0) [0|1] "s"  RadarFrontCenter,DASy
 SG_ VFC_ObjHdr_AUTOSARTStamp : 222|26@1+ (1,0) [0|67108863] "ms"  RadarFrontCenter,DASy
 SG_ VFC_ObjHdr_TimeStampStatus : 248|8@1+ (1,0) [0|255] ""  RadarFrontCenter,DASy
 SG_ VFC_ObjHdr_BlockCtr : 24|4@1+ (1,0) [0|15] ""  RadarFrontCenter,DASy
 SG_ VFC_ObjHdr_FrameNo : 28|4@1+ (1,0) [0|15] ""  RadarFrontCenter,DASy
 SG_ VFC_ObjHdr_TimeStamp : 32|26@1+ (1,0) [0|67108863] "ms"  RadarFrontCenter,DASy
 SG_ VFC_ObjHdr_Blindness : 58|6@1+ (2,0) [0|100] "%"  RadarFrontCenter,DASy
 SG_ VFC_ObjHdr_CalibPitchAngle : 64|10@1+ (0.0005,-0.2) [-0.2|0.2] "rad"  RadarFrontCenter,DASy
 SG_ VFC_ObjHdr_FreeViewProb : 74|6@1+ (2,0) [0|100] "%"  RadarFrontCenter,DASy
 SG_ VFC_ObjHdr_CalibPitchStdDev : 80|9@1+ (0.0005,0) [0|0.25] "rad"  RadarFrontCenter,DASy
 SG_ VFC_ObjHdr_ObjCount : 89|7@1+ (1,0) [0|127] ""  RadarFrontCenter,DASy
 SG_ VFC_ObjHdr_CalibRollAngle : 96|10@1+ (0.0005,-0.2) [-0.2|0.2] "rad"  RadarFrontCenter,DASy

BO_ 176 VFC_Object00A: 64 MPC3
 SG_ VFC_Obj00A_CRC : 0|16@1+ (1,0) [0|65535] ""  RadarFrontCenter,DASy
 SG_ VFC_Obj00A_DyStdDev : 104|10@1+ (0.02,0) [0|20] "m"  RadarFrontCenter,DASy
 SG_ VFC_Obj00A_DxStdDev : 118|10@1+ (0.05,0) [0|50] "m"  RadarFrontCenter,DASy
 SG_ VFC_Obj00A_VxStdDev : 128|10@1+ (0.1,0) [0|100] "m/s"  RadarFrontCenter,DASy
 SG_ VFC_Obj00A_ExistProb : 138|6@1+ (2,0) [0|100] "%"  RadarFrontCenter,DASy
 SG_ VFC_Obj00A_VyStdDev : 144|9@1+ (0.1,0) [0|50] "m/s"  RadarFrontCenter,DASy
 SG_ VFC_Obj00A_TypeProb : 154|6@1+ (2,0) [0|100] "%"  RadarFrontCenter,DASy
 SG_ VFC_Obj00A_AxStdDev : 160|8@1+ (0.1,0) [0|25] "m/s^2"  RadarFrontCenter,DASy
 SG_ VFC_Obj00A_AyStdDev : 168|8@1+ (0.1,0) [0|25] "m/s^2"  RadarFrontCenter,DASy
 SG_ VFC_Obj00A_AliveCtr : 16|8@1+ (1,0) [0|255] ""  RadarFrontCenter,DASy
 SG_ VFC_Obj00A_PhiLeft : 176|13@1+ (0.00025,-1) [-1|1] ""  RadarFrontCenter,DASy
 SG_ VFC_Obj00A_ClassifiedView : 189|3@1+ (1,0) [0|7] ""  RadarFrontCenter,DASy
 SG_ VFC_Obj00A_Length : 192|9@1+ (0.05,0) [0|25.5] "m"  RadarFrontCenter,DASy
 SG_ VFC_Obj00A_WidthStdDev : 201|7@1+ (0.01,0) [0|1] "m"  RadarFrontCenter,DASy
 SG_ VFC_Obj00A_Height : 208|9@1+ (0.01,0) [0|5.11] "m"  RadarFrontCenter,DASy
 SG_ VFC_Obj00A_HeightStdDev : 217|7@1+ (0.01,0) [0|1] "m"  RadarFrontCenter,DASy
 SG_ VFC_Obj00A_PhiLeftStdDev : 224|8@1+ (0.0002,0) [0|0.05] ""  RadarFrontCenter,DASy
 SG_ VFC_Obj00A_HeadingStdDev : 232|6@1+ (0.01,0) [0|0.5] "rad"  RadarFrontCenter,DASy
 SG_ VFC_Obj00A_Measured : 238|2@1+ (1,0) [0|3] ""  RadarFrontCenter,DASy
 SG_ VFC_Obj00A_Heading : 240|9@1+ (0.01,-1.57) [-1.57|1.57] "rad"  RadarFrontCenter,DASy
 SG_ VFC_Obj00A_LengthStdDev : 249|7@1+ (0.05,0) [0|5] "m"  RadarFrontCenter,DASy
 SG_ VFC_Obj00A_BlockCtr : 24|4@1+ (1,0) [0|15] ""  RadarFrontCenter,DASy
 SG_ VFC_Obj00A_PhiMid : 256|13@1+ (0.00025,-1) [-1|1] ""  RadarFrontCenter,DASy
 SG_ VFC_Obj00A_Width : 269|11@1+ (0.01,0) [0|12] "m"  RadarFrontCenter,DASy
 SG_ VFC_Obj00A_PhiMidStdDev : 280|8@1+ (0.0002,0) [0|0.05] ""  RadarFrontCenter,DASy
 SG_ VFC_Obj00A_PhiRight : 288|13@1+ (0.00025,-1) [-1|1] ""  RadarFrontCenter,DASy
 SG_ VFC_Obj00A_VisibleView : 301|3@1+ (1,0) [0|4] ""  RadarFrontCenter,DASy
 SG_ VFC_Obj00A_PhiRightStdDev : 304|8@1+ (0.0002,0) [0|0.05] ""  RadarFrontCenter,DASy
 SG_ VFC_Obj00A_PhiLeftVel : 312|13@1+ (0.001,-4) [-4|4] "1/s"  RadarFrontCenter,DASy
 SG_ VFC_Obj00A_PhiRightVel : 328|13@1+ (0.001,-4) [-4|4] "1/s"  RadarFrontCenter,DASy
 SG_ VFC_Obj00A_ProtOrderIndex : 32|6@1+ (1,0) [0|63] ""  RadarFrontCenter,DASy
 SG_ VFC_Obj00A_PhiRightVelStdDev : 344|8@1+ (0.001,0) [0|0.25] "1/s"  RadarFrontCenter,DASy
 SG_ VFC_Obj00A_PhiLeftVelStdDev : 352|8@1+ (0.001,0) [0|0.25] "1/s"  RadarFrontCenter,DASy
 SG_ VFC_Obj00A_PhiTop : 360|12@1+ (0.00025,-0.4) [-0.4|0.4] ""  RadarFrontCenter,DASy
 SG_ VFC_Obj00A_PhiBottom : 372|12@1+ (0.00025,-0.4) [-0.4|0.4] ""  RadarFrontCenter,DASy
 SG_ VFC_Obj00A_PhiTopStdDev : 384|8@1+ (0.0002,0) [0|0.05] ""  RadarFrontCenter,DASy
 SG_ VFC_Obj00A_HeadOrientation : 392|4@1+ (1,0) [0|15] ""  RadarFrontCenter,DASy
 SG_ VFC_Obj00A_Type : 396|4@1+ (1,0) [0|15] ""  RadarFrontCenter,DASy
 SG_ VFC_Obj00A_Ax : 39|9@1+ (0.1,-16) [-16|16] "m/s^2"  RadarFrontCenter,DASy
 SG_ VFC_Obj00A_PhiBottomStdDev : 400|8@1+ (0.0002,0) [0|0.05] ""  RadarFrontCenter,DASy
 SG_ VFC_Obj00A_NormVx : 408|16@1+ (0.001,-40) [-40|25] "1/s"  RadarFrontCenter,DASy
 SG_ VFC_Obj00A_NormAx : 424|13@1+ (0.002,-10) [-10|6] "1/s^2"  RadarFrontCenter,DASy
 SG_ VFC_Obj00A_NormAxStdDev : 440|10@1+ (0.0025,0) [0|2.5] "1/s^2"  RadarFrontCenter,DASy
 SG_ VFC_Obj00A_ProbMovingLat : 450|6@1+ (2,0) [0|100] "%"  RadarFrontCenter,DASy
 SG_ VFC_Obj00A_ID : 456|8@1+ (1,0) [0|254] ""  RadarFrontCenter,DASy
 SG_ VFC_Obj00A_NormVxStdDev : 464|10@1+ (0.001,0) [0|1] "1/s"  RadarFrontCenter,DASy
 SG_ VFC_Obj00A_ProbMovingLong : 474|6@1+ (2,0) [0|100] "%"  RadarFrontCenter,DASy
 SG_ VFC_Obj00A_Vx : 48|12@1+ (0.1,-154) [-154|50] "m/s"  RadarFrontCenter,DASy
 SG_ VFC_Obj00A_Dx : 60|12@1+ (0.05,0) [0|204.7] "m"  RadarFrontCenter,DASy
 SG_ VFC_Obj00A_Dy : 72|14@1+ (0.01,-80) [-80|80] "m"  RadarFrontCenter,DASy
 SG_ VFC_Obj00A_Vy : 86|10@1+ (0.1,-50) [-50|50] "m/s"  RadarFrontCenter,DASy
 SG_ VFC_Obj00A_Ay : 96|8@1+ (0.1,-12) [-12|12] "m/s^2"  RadarFrontCenter,DASy

BO_ 177 VFC_Object00B: 16 MPC3
 SG_ VFC_Obj00B_CRC : 0|16@1+ (1,0) [0|65535] ""  RadarFrontCenter,DASy
 SG_ VFC_Obj00B_TTIPC : 104|11@1+ (0.008,-8) [-8|8] ""  RadarFrontCenter,DASy
 SG_ VFC_Obj00B_TTIPC_StdDev : 120|7@1+ (0.0625,0) [0|7.875] ""  RadarFrontCenter,DASy
 SG_ VFC_Obj00B_AliveCtr : 16|8@1+ (1,0) [0|255] ""  RadarFrontCenter,DASy
 SG_ VFC_Obj00B_BlockCtr : 24|4@1+ (1,0) [0|15] ""  RadarFrontCenter,DASy
 SG_ VFC_Obj00B_ScaleChange : 32|14@1+ (0.0001,0.5) [0.5|2.1] ""  RadarFrontCenter,DASy
 SG_ VFC_Obj00B_ScaleChngStdDev : 48|10@1+ (0.0001,0) [0|0.1] ""  RadarFrontCenter,DASy
 SG_ VFC_Obj00B_LineEdgeRightEgo : 58|1@1+ (1,0) [0|1] ""  RadarFrontCenter,DASy
 SG_ VFC_Obj00B_LineEdgeLeftEgo : 59|1@1+ (1,0) [0|1] ""  RadarFrontCenter,DASy
 SG_ VFC_Obj00B_CompletelyInImg : 60|1@1+ (1,0) [0|1] ""  RadarFrontCenter,DASy
 SG_ VFC_Obj00B_DirIndicator : 61|3@1+ (1,0) [0|7] ""  RadarFrontCenter,DASy
 SG_ VFC_Obj00B_LineEdgeAngle : 64|13@1+ (0.00025,-1) [-1|1] "rad"  RadarFrontCenter,DASy
 SG_ VFC_Obj00B_BrakeLight : 77|3@1+ (1,0) [0|7] ""  RadarFrontCenter,DASy
 SG_ VFC_Obj00B_MeasSource : 80|5@1+ (1,0) [0|31] ""  RadarFrontCenter,DASy
 SG_ VFC_Obj00B_AngLongitude : 88|10@1+ (0.005,-2.5) [-2.5|2.5] "rad/s"  RadarFrontCenter,DASy
 SG_ VFC_Obj00B_Reliab : 98|6@1+ (1,0) [0|63] ""  RadarFrontCenter,DASy

BO_ 178 VFC_Object01A: 64 MPC3
 SG_ VFC_Obj01A_CRC : 0|16@1+ (1,0) [0|65535] ""  RadarFrontCenter,DASy
 SG_ VFC_Obj01A_DyStdDev : 104|10@1+ (0.02,0) [0|20] "m"  RadarFrontCenter,DASy
 SG_ VFC_Obj01A_DxStdDev : 118|10@1+ (0.05,0) [0|50] "m"  RadarFrontCenter,DASy
 SG_ VFC_Obj01A_VxStdDev : 128|10@1+ (0.1,0) [0|100] "m/s"  RadarFrontCenter,DASy
 SG_ VFC_Obj01A_ExistProb : 138|6@1+ (2,0) [0|100] "%"  RadarFrontCenter,DASy
 SG_ VFC_Obj01A_VyStdDev : 144|9@1+ (0.1,0) [0|50] "m/s"  RadarFrontCenter,DASy
 SG_ VFC_Obj01A_TypeProb : 154|6@1+ (2,0) [0|100] "%"  RadarFrontCenter,DASy
 SG_ VFC_Obj01A_AxStdDev : 160|8@1+ (0.1,0) [0|25] "m/s^2"  RadarFrontCenter,DASy
 SG_ VFC_Obj01A_AyStdDev : 168|8@1+ (0.1,0) [0|25] "m/s^2"  RadarFrontCenter,DASy
 SG_ VFC_Obj01A_AliveCtr : 16|8@1+ (1,0) [0|255] ""  RadarFrontCenter,DASy
 SG_ VFC_Obj01A_PhiLeft : 176|13@1+ (0.00025,-1) [-1|1] ""  RadarFrontCenter,DASy
 SG_ VFC_Obj01A_ClassifiedView : 189|3@1+ (1,0) [0|7] ""  RadarFrontCenter,DASy
 SG_ VFC_Obj01A_Length : 192|9@1+ (0.05,0) [0|25.5] "m"  RadarFrontCenter,DASy
 SG_ VFC_Obj01A_WidthStdDev : 201|7@1+ (0.01,0) [0|1] "m"  RadarFrontCenter,DASy
 SG_ VFC_Obj01A_Height : 208|9@1+ (0.01,0) [0|5.11] "m"  RadarFrontCenter,DASy
 SG_ VFC_Obj01A_HeightStdDev : 217|7@1+ (0.01,0) [0|1] "m"  RadarFrontCenter,DASy
 SG_ VFC_Obj01A_PhiLeftStdDev : 224|8@1+ (0.0002,0) [0|0.05] ""  RadarFrontCenter,DASy
 SG_ VFC_Obj01A_HeadingStdDev : 232|6@1+ (0.01,0) [0|0.5] "rad"  RadarFrontCenter,DASy
 SG_ VFC_Obj01A_Measured : 238|2@1+ (1,0) [0|3] ""  RadarFrontCenter,DASy
 SG_ VFC_Obj01A_Heading : 240|9@1+ (0.01,-1.57) [-1.57|1.57] "rad"  RadarFrontCenter,DASy
 SG_ VFC_Obj01A_LengthStdDev : 249|7@1+ (0.05,0) [0|5] "m"  RadarFrontCenter,DASy
 SG_ VFC_Obj01A_BlockCtr : 24|4@1+ (1,0) [0|15] ""  RadarFrontCenter,DASy
 SG_ VFC_Obj01A_PhiMid : 256|13@1+ (0.00025,-1) [-1|1] ""  RadarFrontCenter,DASy
 SG_ VFC_Obj01A_Width : 269|11@1+ (0.01,0) [0|12] "m"  RadarFrontCenter,DASy
 SG_ VFC_Obj01A_PhiMidStdDev : 280|8@1+ (0.0002,0) [0|0.05] ""  RadarFrontCenter,DASy
 SG_ VFC_Obj01A_PhiRight : 288|13@1+ (0.00025,-1) [-1|1] ""  RadarFrontCenter,DASy
 SG_ VFC_Obj01A_VisibleView : 301|3@1+ (1,0) [0|4] ""  RadarFrontCenter,DASy
 SG_ VFC_Obj01A_PhiRightStdDev : 304|8@1+ (0.0002,0) [0|0.05] ""  RadarFrontCenter,DASy
 SG_ VFC_Obj01A_PhiLeftVel : 312|13@1+ (0.001,-4) [-4|4] "1/s"  RadarFrontCenter,DASy
 SG_ VFC_Obj01A_PhiRightVel : 328|13@1+ (0.001,-4) [-4|4] "1/s"  RadarFrontCenter,DASy
 SG_ VFC_Obj01A_ProtOrderIndex : 32|6@1+ (1,0) [0|63] ""  RadarFrontCenter,DASy
 SG_ VFC_Obj01A_PhiRightVelStdDev : 344|8@1+ (0.001,0) [0|0.25] "1/s"  RadarFrontCenter,DASy
 SG_ VFC_Obj01A_PhiLeftVelStdDev : 352|8@1+ (0.001,0) [0|0.25] "1/s"  RadarFrontCenter,DASy
 SG_ VFC_Obj01A_PhiTop : 360|12@1+ (0.00025,-0.4) [-0.4|0.4] ""  RadarFrontCenter,DASy
 SG_ VFC_Obj01A_PhiBottom : 372|12@1+ (0.00025,-0.4) [-0.4|0.4] ""  RadarFrontCenter,DASy
 SG_ VFC_Obj01A_PhiTopStdDev : 384|8@1+ (0.0002,0) [0|0.05] ""  RadarFrontCenter,DASy
 SG_ VFC_Obj01A_HeadOrientation : 392|4@1+ (1,0) [0|10] ""  RadarFrontCenter,DASy
 SG_ VFC_Obj01A_Type : 396|4@1+ (1,0) [0|15] ""  RadarFrontCenter,DASy
 SG_ VFC_Obj01A_Ax : 39|9@1+ (0.1,-16) [-16|16] "m/s^2"  RadarFrontCenter,DASy
 SG_ VFC_Obj01A_PhiBottomStdDev : 400|8@1+ (0.0002,0) [0|0.05] ""  RadarFrontCenter,DASy
 SG_ VFC_Obj01A_NormVx : 408|16@1+ (0.001,-40) [-40|25] "1/s"  RadarFrontCenter,DASy
 SG_ VFC_Obj01A_NormAx : 424|13@1+ (0.002,-10) [-10|6] "1/s^2"  RadarFrontCenter,DASy
 SG_ VFC_Obj01A_NormAxStdDev : 440|10@1+ (0.0025,0) [0|2.5] "1/s^2"  RadarFrontCenter,DASy
 SG_ VFC_Obj01A_ProbMovingLat : 450|6@1+ (2,0) [0|100] "%"  RadarFrontCenter,DASy
 SG_ VFC_Obj01A_ID : 456|8@1+ (1,0) [0|254] ""  RadarFrontCenter,DASy
 SG_ VFC_Obj01A_NormVxStdDev : 464|10@1+ (0.001,0) [0|1] "1/s"  RadarFrontCenter,DASy
 SG_ VFC_Obj01A_ProbMovingLong : 474|6@1+ (2,0) [0|100] "%"  RadarFrontCenter,DASy
 SG_ VFC_Obj01A_Vx : 48|12@1+ (0.1,-154) [-154|50] "m/s"  RadarFrontCenter,DASy
 SG_ VFC_Obj01A_Dx : 60|12@1+ (0.05,0) [0|204.7] "m"  RadarFrontCenter,DASy
 SG_ VFC_Obj01A_Dy : 72|14@1+ (0.01,-80) [-80|80] "m"  RadarFrontCenter,DASy
 SG_ VFC_Obj01A_Vy : 86|10@1+ (0.1,-50) [-50|50] "m/s"  RadarFrontCenter,DASy
 SG_ VFC_Obj01A_Ay : 96|8@1+ (0.1,-12) [-12|12] "m/s^2"  RadarFrontCenter,DASy

BO_ 179 VFC_Object01B: 16 MPC3
 SG_ VFC_Obj01B_CRC : 0|16@1+ (1,0) [0|65535] ""  RadarFrontCenter,DASy
 SG_ VFC_Obj01B_TTIPC : 104|11@1+ (0.008,-8) [-8|8] ""  RadarFrontCenter,DASy
 SG_ VFC_Obj01B_TTIPC_StdDev : 120|7@1+ (0.0625,0) [0|7.875] ""  RadarFrontCenter,DASy
 SG_ VFC_Obj01B_AliveCtr : 16|8@1+ (1,0) [0|255] ""  RadarFrontCenter,DASy
 SG_ VFC_Obj01B_BlockCtr : 24|4@1+ (1,0) [0|15] ""  RadarFrontCenter,DASy
 SG_ VFC_Obj01B_ScaleChange : 32|14@1+ (0.0001,0.5) [0.5|2.1] ""  RadarFrontCenter,DASy
 SG_ VFC_Obj01B_ScaleChngStdDev : 48|10@1+ (0.0001,0) [0|0.1] ""  RadarFrontCenter,DASy
 SG_ VFC_Obj01B_LineEdgeRightEgo : 58|1@1+ (1,0) [0|1] ""  RadarFrontCenter,DASy
 SG_ VFC_Obj01B_LineEdgeLeftEgo : 59|1@1+ (1,0) [0|1] ""  RadarFrontCenter,DASy
 SG_ VFC_Obj01B_CompletelyInImg : 60|1@1+ (1,0) [0|1] ""  RadarFrontCenter,DASy
 SG_ VFC_Obj01B_DirIndicator : 61|3@1+ (1,0) [0|7] ""  RadarFrontCenter,DASy
 SG_ VFC_Obj01B_LineEdgeAngle : 64|13@1+ (0.00025,-1) [-1|1] "rad"  RadarFrontCenter,DASy
 SG_ VFC_Obj01B_BrakeLight : 77|3@1+ (1,0) [0|7] ""  RadarFrontCenter,DASy
 SG_ VFC_Obj01B_MeasSource : 80|5@1+ (1,0) [0|31] ""  RadarFrontCenter,DASy
 SG_ VFC_Obj01B_AngLongitude : 88|10@1+ (0.005,-2.5) [-2.5|2.5] "rad/s"  RadarFrontCenter,DASy
 SG_ VFC_Obj01B_Reliab : 98|6@1+ (1,0) [0|63] ""  RadarFrontCenter,DASy

BO_ 180 VFC_Object02A: 64 MPC3
 SG_ VFC_Obj02A_CRC : 0|16@1+ (1,0) [0|65535] ""  RadarFrontCenter,DASy
 SG_ VFC_Obj02A_DyStdDev : 104|10@1+ (0.02,0) [0|20] "m"  RadarFrontCenter,DASy
 SG_ VFC_Obj02A_DxStdDev : 118|10@1+ (0.05,0) [0|50] "m"  RadarFrontCenter,DASy
 SG_ VFC_Obj02A_VxStdDev : 128|10@1+ (0.1,0) [0|100] "m/s"  RadarFrontCenter,DASy
 SG_ VFC_Obj02A_ExistProb : 138|6@1+ (2,0) [0|100] "%"  RadarFrontCenter,DASy
 SG_ VFC_Obj02A_VyStdDev : 144|9@1+ (0.1,0) [0|50] "m/s"  RadarFrontCenter,DASy
 SG_ VFC_Obj02A_TypeProb : 154|6@1+ (2,0) [0|100] "%"  RadarFrontCenter,DASy
 SG_ VFC_Obj02A_AxStdDev : 160|8@1+ (0.1,0) [0|25] "m/s^2"  RadarFrontCenter,DASy
 SG_ VFC_Obj02A_AyStdDev : 168|8@1+ (0.1,0) [0|25] "m/s^2"  RadarFrontCenter,DASy
 SG_ VFC_Obj02A_AliveCtr : 16|8@1+ (1,0) [0|255] ""  RadarFrontCenter,DASy
 SG_ VFC_Obj02A_PhiLeft : 176|13@1+ (0.00025,-1) [-1|1] ""  RadarFrontCenter,DASy
 SG_ VFC_Obj02A_ClassifiedView : 189|3@1+ (1,0) [0|7] ""  RadarFrontCenter,DASy
 SG_ VFC_Obj02A_Length : 192|9@1+ (0.05,0) [0|25.5] "m"  RadarFrontCenter,DASy
 SG_ VFC_Obj02A_WidthStdDev : 201|7@1+ (0.01,0) [0|1] "m"  RadarFrontCenter,DASy
 SG_ VFC_Obj02A_Height : 208|9@1+ (0.01,0) [0|5.11] "m"  RadarFrontCenter,DASy
 SG_ VFC_Obj02A_HeightStdDev : 217|7@1+ (0.01,0) [0|1] "m"  RadarFrontCenter,DASy
 SG_ VFC_Obj02A_PhiLeftStdDev : 224|8@1+ (0.0002,0) [0|0.05] ""  RadarFrontCenter,DASy
 SG_ VFC_Obj02A_HeadingStdDev : 232|6@1+ (0.01,0) [0|0.5] "rad"  RadarFrontCenter,DASy
 SG_ VFC_Obj02A_Measured : 238|2@1+ (1,0) [0|3] ""  RadarFrontCenter,DASy
 SG_ VFC_Obj02A_Heading : 240|9@1+ (0.01,-1.57) [-1.57|1.57] "rad"  RadarFrontCenter,DASy
 SG_ VFC_Obj02A_LengthStdDev : 249|7@1+ (0.05,0) [0|5] "m"  RadarFrontCenter,DASy
 SG_ VFC_Obj02A_BlockCtr : 24|4@1+ (1,0) [0|15] ""  RadarFrontCenter,DASy
 SG_ VFC_Obj02A_PhiMid : 256|13@1+ (0.00025,-1) [-1|1] ""  RadarFrontCenter,DASy
 SG_ VFC_Obj02A_Width : 269|11@1+ (0.01,0) [0|12] "m"  RadarFrontCenter,DASy
 SG_ VFC_Obj02A_PhiMidStdDev : 280|8@1+ (0.0002,0) [0|0.05] ""  RadarFrontCenter,DASy
 SG_ VFC_Obj02A_PhiRight : 288|13@1+ (0.00025,-1) [-1|1] ""  RadarFrontCenter,DASy
 SG_ VFC_Obj02A_VisibleView : 301|3@1+ (1,0) [0|4] ""  RadarFrontCenter,DASy
 SG_ VFC_Obj02A_PhiRightStdDev : 304|8@1+ (0.0002,0) [0|0.05] ""  RadarFrontCenter,DASy
 SG_ VFC_Obj02A_PhiLeftVel : 312|13@1+ (0.001,-4) [-4|4] "1/s"  RadarFrontCenter,DASy
 SG_ VFC_Obj02A_PhiRightVel : 328|13@1+ (0.001,-4) [-4|4] "1/s"  RadarFrontCenter,DASy
 SG_ VFC_Obj02A_ProtOrderIndex : 32|6@1+ (1,0) [0|63] ""  RadarFrontCenter,DASy
 SG_ VFC_Obj02A_PhiRightVelStdDev : 344|8@1+ (0.001,0) [0|0.25] "1/s"  RadarFrontCenter,DASy
 SG_ VFC_Obj02A_PhiLeftVelStdDev : 352|8@1+ (0.001,0) [0|0.25] "1/s"  RadarFrontCenter,DASy
 SG_ VFC_Obj02A_PhiTop : 360|12@1+ (0.00025,-0.4) [-0.4|0.4] ""  RadarFrontCenter,DASy
 SG_ VFC_Obj02A_PhiBottom : 372|12@1+ (0.00025,-0.4) [-0.4|0.4] ""  RadarFrontCenter,DASy
 SG_ VFC_Obj02A_PhiTopStdDev : 384|8@1+ (0.0002,0) [0|0.05] ""  RadarFrontCenter,DASy
 SG_ VFC_Obj02A_HeadOrientation : 392|4@1+ (1,0) [0|10] ""  RadarFrontCenter,DASy
 SG_ VFC_Obj02A_Type : 396|4@1+ (1,0) [0|15] ""  RadarFrontCenter,DASy
 SG_ VFC_Obj02A_Ax : 39|9@1+ (0.1,-16) [-16|16] "m/s^2"  RadarFrontCenter,DASy
 SG_ VFC_Obj02A_PhiBottomStdDev : 400|8@1+ (0.0002,0) [0|0.05] ""  RadarFrontCenter,DASy
 SG_ VFC_Obj02A_NormVx : 408|16@1+ (0.001,-40) [-40|25] "1/s"  RadarFrontCenter,DASy
 SG_ VFC_Obj02A_NormAx : 424|13@1+ (0.002,-10) [-10|6] "1/s^2"  RadarFrontCenter,DASy
 SG_ VFC_Obj02A_NormAxStdDev : 440|10@1+ (0.0025,0) [0|2.5] "1/s^2"  RadarFrontCenter,DASy
 SG_ VFC_Obj02A_ProbMovingLat : 450|6@1+ (2,0) [0|100] "%"  RadarFrontCenter,DASy
 SG_ VFC_Obj02A_ID : 456|8@1+ (1,0) [0|254] ""  RadarFrontCenter,DASy
 SG_ VFC_Obj02A_NormVxStdDev : 464|10@1+ (0.001,0) [0|1] "1/s"  RadarFrontCenter,DASy
 SG_ VFC_Obj02A_ProbMovingLong : 474|6@1+ (2,0) [0|100] "%"  RadarFrontCenter,DASy
 SG_ VFC_Obj02A_Vx : 48|12@1+ (0.1,-154) [-154|50] "m/s"  RadarFrontCenter,DASy
 SG_ VFC_Obj02A_Dx : 60|12@1+ (0.05,0) [0|204.7] "m"  RadarFrontCenter,DASy
 SG_ VFC_Obj02A_Dy : 72|14@1+ (0.01,-80) [-80|80] "m"  RadarFrontCenter,DASy
 SG_ VFC_Obj02A_Vy : 86|10@1+ (0.1,-50) [-50|50] "m/s"  RadarFrontCenter,DASy
 SG_ VFC_Obj02A_Ay : 96|8@1+ (0.1,-12) [-12|12] "m/s^2"  RadarFrontCenter,DASy

BO_ 181 VFC_Object02B: 16 MPC3
 SG_ VFC_Obj02B_CRC : 0|16@1+ (1,0) [0|65535] ""  RadarFrontCenter,DASy
 SG_ VFC_Obj02B_TTIPC : 104|11@1+ (0.008,-8) [-8|8] ""  RadarFrontCenter,DASy
 SG_ VFC_Obj02B_TTIPC_StdDev : 120|7@1+ (0.0625,0) [0|7.875] ""  RadarFrontCenter,DASy
 SG_ VFC_Obj02B_AliveCtr : 16|8@1+ (1,0) [0|255] ""  RadarFrontCenter,DASy
 SG_ VFC_Obj02B_BlockCtr : 24|4@1+ (1,0) [0|15] ""  RadarFrontCenter,DASy
 SG_ VFC_Obj02B_ScaleChange : 32|14@1+ (0.0001,0.5) [0.5|2.1] ""  RadarFrontCenter,DASy
 SG_ VFC_Obj02B_ScaleChngStdDev : 48|10@1+ (0.0001,0) [0|0.1] ""  RadarFrontCenter,DASy
 SG_ VFC_Obj02B_LineEdgeRightEgo : 58|1@1+ (1,0) [0|1] ""  RadarFrontCenter,DASy
 SG_ VFC_Obj02B_LineEdgeLeftEgo : 59|1@1+ (1,0) [0|1] ""  RadarFrontCenter,DASy
 SG_ VFC_Obj02B_CompletelyInImg : 60|1@1+ (1,0) [0|1] ""  RadarFrontCenter,DASy
 SG_ VFC_Obj02B_DirIndicator : 61|3@1+ (1,0) [0|7] ""  RadarFrontCenter,DASy
 SG_ VFC_Obj02B_LineEdgeAngle : 64|13@1+ (0.00025,-1) [-1|1] "rad"  RadarFrontCenter,DASy
 SG_ VFC_Obj02B_BrakeLight : 77|3@1+ (1,0) [0|7] ""  RadarFrontCenter,DASy
 SG_ VFC_Obj02B_MeasSource : 80|5@1+ (1,0) [0|31] ""  RadarFrontCenter,DASy
 SG_ VFC_Obj02B_AngLongitude : 88|10@1+ (0.005,-2.5) [-2.5|2.5] "rad/s"  RadarFrontCenter,DASy
 SG_ VFC_Obj02B_Reliab : 98|6@1+ (1,0) [0|63] ""  RadarFrontCenter,DASy

BO_ 182 VFC_Object03A: 64 MPC3
 SG_ VFC_Obj03A_CRC : 0|16@1+ (1,0) [0|65535] ""  RadarFrontCenter,DASy
 SG_ VFC_Obj03A_DyStdDev : 104|10@1+ (0.02,0) [0|20] "m"  RadarFrontCenter,DASy
 SG_ VFC_Obj03A_DxStdDev : 118|10@1+ (0.05,0) [0|50] "m"  RadarFrontCenter,DASy
 SG_ VFC_Obj03A_VxStdDev : 128|10@1+ (0.1,0) [0|100] "m/s"  RadarFrontCenter,DASy
 SG_ VFC_Obj03A_ExistProb : 138|6@1+ (2,0) [0|100] "%"  RadarFrontCenter,DASy
 SG_ VFC_Obj03A_VyStdDev : 144|9@1+ (0.1,0) [0|50] "m/s"  RadarFrontCenter,DASy
 SG_ VFC_Obj03A_TypeProb : 154|6@1+ (2,0) [0|100] "%"  RadarFrontCenter,DASy
 SG_ VFC_Obj03A_AxStdDev : 160|8@1+ (0.1,0) [0|25] "m/s^2"  RadarFrontCenter,DASy
 SG_ VFC_Obj03A_AyStdDev : 168|8@1+ (0.1,0) [0|25] "m/s^2"  RadarFrontCenter,DASy
 SG_ VFC_Obj03A_AliveCtr : 16|8@1+ (1,0) [0|255] ""  RadarFrontCenter,DASy
 SG_ VFC_Obj03A_PhiLeft : 176|13@1+ (0.00025,-1) [-1|1] ""  RadarFrontCenter,DASy
 SG_ VFC_Obj03A_ClassifiedView : 189|3@1+ (1,0) [0|7] ""  RadarFrontCenter,DASy
 SG_ VFC_Obj03A_Length : 192|9@1+ (0.05,0) [0|25.5] "m"  RadarFrontCenter,DASy
 SG_ VFC_Obj03A_WidthStdDev : 201|7@1+ (0.01,0) [0|1] "m"  RadarFrontCenter,DASy
 SG_ VFC_Obj03A_Height : 208|9@1+ (0.01,0) [0|5.11] "m"  RadarFrontCenter,DASy
 SG_ VFC_Obj03A_HeightStdDev : 217|7@1+ (0.01,0) [0|1] "m"  RadarFrontCenter,DASy
 SG_ VFC_Obj03A_PhiLeftStdDev : 224|8@1+ (0.0002,0) [0|0.05] ""  RadarFrontCenter,DASy
 SG_ VFC_Obj03A_HeadingStdDev : 232|6@1+ (0.01,0) [0|0.5] "rad"  RadarFrontCenter,DASy
 SG_ VFC_Obj03A_Measured : 238|2@1+ (1,0) [0|3] ""  RadarFrontCenter,DASy
 SG_ VFC_Obj03A_Heading : 240|9@1+ (0.01,-1.57) [-1.57|1.57] "rad"  RadarFrontCenter,DASy
 SG_ VFC_Obj03A_LengthStdDev : 249|7@1+ (0.05,0) [0|5] "m"  RadarFrontCenter,DASy
 SG_ VFC_Obj03A_BlockCtr : 24|4@1+ (1,0) [0|15] ""  RadarFrontCenter,DASy
 SG_ VFC_Obj03A_PhiMid : 256|13@1+ (0.00025,-1) [-1|1] ""  RadarFrontCenter,DASy
 SG_ VFC_Obj03A_Width : 269|11@1+ (0.01,0) [0|12] "m"  RadarFrontCenter,DASy
 SG_ VFC_Obj03A_PhiMidStdDev : 280|8@1+ (0.0002,0) [0|0.05] ""  RadarFrontCenter,DASy
 SG_ VFC_Obj03A_PhiRight : 288|13@1+ (0.00025,-1) [-1|1] ""  RadarFrontCenter,DASy
 SG_ VFC_Obj03A_VisibleView : 301|3@1+ (1,0) [0|4] ""  RadarFrontCenter,DASy
 SG_ VFC_Obj03A_PhiRightStdDev : 304|8@1+ (0.0002,0) [0|0.05] ""  RadarFrontCenter,DASy
 SG_ VFC_Obj03A_PhiLeftVel : 312|13@1+ (0.001,-4) [-4|4] "1/s"  RadarFrontCenter,DASy
 SG_ VFC_Obj03A_PhiRightVel : 328|13@1+ (0.001,-4) [-4|4] "1/s"  RadarFrontCenter,DASy
 SG_ VFC_Obj03A_ProtOrderIndex : 32|6@1+ (1,0) [0|63] ""  RadarFrontCenter,DASy
 SG_ VFC_Obj03A_PhiRightVelStdDev : 344|8@1+ (0.001,0) [0|0.25] "1/s"  RadarFrontCenter,DASy
 SG_ VFC_Obj03A_PhiLeftVelStdDev : 352|8@1+ (0.001,0) [0|0.25] "1/s"  RadarFrontCenter,DASy
 SG_ VFC_Obj03A_PhiTop : 360|12@1+ (0.00025,-0.4) [-0.4|0.4] ""  RadarFrontCenter,DASy
 SG_ VFC_Obj03A_PhiBottom : 372|12@1+ (0.00025,-0.4) [-0.4|0.4] ""  RadarFrontCenter,DASy
 SG_ VFC_Obj03A_PhiTopStdDev : 384|8@1+ (0.0002,0) [0|0.05] ""  RadarFrontCenter,DASy
 SG_ VFC_Obj03A_HeadOrientation : 392|4@1+ (1,0) [0|10] ""  RadarFrontCenter,DASy
 SG_ VFC_Obj03A_Type : 396|4@1+ (1,0) [0|15] ""  RadarFrontCenter,DASy
 SG_ VFC_Obj03A_Ax : 39|9@1+ (0.1,-16) [-16|16] "m/s^2"  RadarFrontCenter,DASy
 SG_ VFC_Obj03A_PhiBottomStdDev : 400|8@1+ (0.0002,0) [0|0.05] ""  RadarFrontCenter,DASy
 SG_ VFC_Obj03A_NormVx : 408|16@1+ (0.001,-40) [-40|25] "1/s"  RadarFrontCenter,DASy
 SG_ VFC_Obj03A_NormAx : 424|13@1+ (0.002,-10) [-10|6] "1/s^2"  RadarFrontCenter,DASy
 SG_ VFC_Obj03A_NormAxStdDev : 440|10@1+ (0.0025,0) [0|2.5] "1/s^2"  RadarFrontCenter,DASy
 SG_ VFC_Obj03A_ProbMovingLat : 450|6@1+ (2,0) [0|100] "%"  RadarFrontCenter,DASy
 SG_ VFC_Obj03A_ID : 456|8@1+ (1,0) [0|254] ""  RadarFrontCenter,DASy
 SG_ VFC_Obj03A_NormVxStdDev : 464|10@1+ (0.001,0) [0|1] "1/s"  RadarFrontCenter,DASy
 SG_ VFC_Obj03A_ProbMovingLong : 474|6@1+ (2,0) [0|100] "%"  RadarFrontCenter,DASy
 SG_ VFC_Obj03A_Vx : 48|12@1+ (0.1,-154) [-154|50] "m/s"  RadarFrontCenter,DASy
 SG_ VFC_Obj03A_Dx : 60|12@1+ (0.05,0) [0|204.7] "m"  RadarFrontCenter,DASy
 SG_ VFC_Obj03A_Dy : 72|14@1+ (0.01,-80) [-80|80] "m"  RadarFrontCenter,DASy
 SG_ VFC_Obj03A_Vy : 86|10@1+ (0.1,-50) [-50|50] "m/s"  RadarFrontCenter,DASy
 SG_ VFC_Obj03A_Ay : 96|8@1+ (0.1,-12) [-12|12] "m/s^2"  RadarFrontCenter,DASy

BO_ 183 VFC_Object03B: 16 MPC3
 SG_ VFC_Obj03B_CRC : 0|16@1+ (1,0) [0|65535] ""  RadarFrontCenter,DASy
 SG_ VFC_Obj03B_TTIPC : 104|11@1+ (0.008,-8) [-8|8] ""  RadarFrontCenter,DASy
 SG_ VFC_Obj03B_TTIPC_StdDev : 120|7@1+ (0.0625,0) [0|7.875] ""  RadarFrontCenter,DASy
 SG_ VFC_Obj03B_AliveCtr : 16|8@1+ (1,0) [0|255] ""  RadarFrontCenter,DASy
 SG_ VFC_Obj03B_BlockCtr : 24|4@1+ (1,0) [0|15] ""  RadarFrontCenter,DASy
 SG_ VFC_Obj03B_ScaleChange : 32|14@1+ (0.0001,0.5) [0.5|2.1] ""  RadarFrontCenter,DASy
 SG_ VFC_Obj03B_ScaleChngStdDev : 48|10@1+ (0.0001,0) [0|0.1] ""  RadarFrontCenter,DASy
 SG_ VFC_Obj03B_LineEdgeRightEgo : 58|1@1+ (1,0) [0|1] ""  RadarFrontCenter,DASy
 SG_ VFC_Obj03B_LineEdgeLeftEgo : 59|1@1+ (1,0) [0|1] ""  RadarFrontCenter,DASy
 SG_ VFC_Obj03B_CompletelyInImg : 60|1@1+ (1,0) [0|1] ""  RadarFrontCenter,DASy
 SG_ VFC_Obj03B_DirIndicator : 61|3@1+ (1,0) [0|7] ""  RadarFrontCenter,DASy
 SG_ VFC_Obj03B_LineEdgeAngle : 64|13@1+ (0.00025,-1) [-1|1] "rad"  RadarFrontCenter,DASy
 SG_ VFC_Obj03B_BrakeLight : 77|3@1+ (1,0) [0|7] ""  RadarFrontCenter,DASy
 SG_ VFC_Obj03B_MeasSource : 80|5@1+ (1,0) [0|31] ""  RadarFrontCenter,DASy
 SG_ VFC_Obj03B_AngLongitude : 88|10@1+ (0.005,-2.5) [-2.5|2.5] "rad/s"  RadarFrontCenter,DASy
 SG_ VFC_Obj03B_Reliab : 98|6@1+ (1,0) [0|63] ""  RadarFrontCenter,DASy

BO_ 184 VFC_Object04A: 64 MPC3
 SG_ VFC_Obj04A_CRC : 0|16@1+ (1,0) [0|65535] ""  RadarFrontCenter,DASy
 SG_ VFC_Obj04A_DyStdDev : 104|10@1+ (0.02,0) [0|20] "m"  RadarFrontCenter,DASy
 SG_ VFC_Obj04A_DxStdDev : 118|10@1+ (0.05,0) [0|50] "m"  RadarFrontCenter,DASy
 SG_ VFC_Obj04A_VxStdDev : 128|10@1+ (0.1,0) [0|100] "m/s"  RadarFrontCenter,DASy
 SG_ VFC_Obj04A_ExistProb : 138|6@1+ (2,0) [0|100] "%"  RadarFrontCenter,DASy
 SG_ VFC_Obj04A_VyStdDev : 144|9@1+ (0.1,0) [0|50] "m/s"  RadarFrontCenter,DASy
 SG_ VFC_Obj04A_TypeProb : 154|6@1+ (2,0) [0|100] "%"  RadarFrontCenter,DASy
 SG_ VFC_Obj04A_AxStdDev : 160|8@1+ (0.1,0) [0|25] "m/s^2"  RadarFrontCenter,DASy
 SG_ VFC_Obj04A_AyStdDev : 168|8@1+ (0.1,0) [0|25] "m/s^2"  RadarFrontCenter,DASy
 SG_ VFC_Obj04A_AliveCtr : 16|8@1+ (1,0) [0|255] ""  RadarFrontCenter,DASy
 SG_ VFC_Obj04A_PhiLeft : 176|13@1+ (0.00025,-1) [-1|1] ""  RadarFrontCenter,DASy
 SG_ VFC_Obj04A_ClassifiedView : 189|3@1+ (1,0) [0|7] ""  RadarFrontCenter,DASy
 SG_ VFC_Obj04A_Length : 192|9@1+ (0.05,0) [0|25.5] "m"  RadarFrontCenter,DASy
 SG_ VFC_Obj04A_WidthStdDev : 201|7@1+ (0.01,0) [0|1] "m"  RadarFrontCenter,DASy
 SG_ VFC_Obj04A_Height : 208|9@1+ (0.01,0) [0|5.11] "m"  RadarFrontCenter,DASy
 SG_ VFC_Obj04A_HeightStdDev : 217|7@1+ (0.01,0) [0|1] "m"  RadarFrontCenter,DASy
 SG_ VFC_Obj04A_PhiLeftStdDev : 224|8@1+ (0.0002,0) [0|0.05] ""  RadarFrontCenter,DASy
 SG_ VFC_Obj04A_HeadingStdDev : 232|6@1+ (0.01,0) [0|0.5] "rad"  RadarFrontCenter,DASy
 SG_ VFC_Obj04A_Measured : 238|2@1+ (1,0) [0|3] ""  RadarFrontCenter,DASy
 SG_ VFC_Obj04A_Heading : 240|9@1+ (0.01,-1.57) [-1.57|1.57] "rad"  RadarFrontCenter,DASy
 SG_ VFC_Obj04A_LengthStdDev : 249|7@1+ (0.05,0) [0|5] "m"  RadarFrontCenter,DASy
 SG_ VFC_Obj04A_BlockCtr : 24|4@1+ (1,0) [0|15] ""  RadarFrontCenter,DASy
 SG_ VFC_Obj04A_PhiMid : 256|13@1+ (0.00025,-1) [-1|1] ""  RadarFrontCenter,DASy
 SG_ VFC_Obj04A_Width : 269|11@1+ (0.01,0) [0|12] "m"  RadarFrontCenter,DASy
 SG_ VFC_Obj04A_PhiMidStdDev : 280|8@1+ (0.0002,0) [0|0.05] ""  RadarFrontCenter,DASy
 SG_ VFC_Obj04A_PhiRight : 288|13@1+ (0.00025,-1) [-1|1] ""  RadarFrontCenter,DASy
 SG_ VFC_Obj04A_VisibleView : 301|3@1+ (1,0) [0|4] ""  RadarFrontCenter,DASy
 SG_ VFC_Obj04A_PhiRightStdDev : 304|8@1+ (0.0002,0) [0|0.05] ""  RadarFrontCenter,DASy
 SG_ VFC_Obj04A_PhiLeftVel : 312|13@1+ (0.001,-4) [-4|4] "1/s"  RadarFrontCenter,DASy
 SG_ VFC_Obj04A_PhiRightVel : 328|13@1+ (0.001,-4) [-4|4] "1/s"  RadarFrontCenter,DASy
 SG_ VFC_Obj04A_ProtOrderIndex : 32|6@1+ (1,0) [0|63] ""  RadarFrontCenter,DASy
 SG_ VFC_Obj04A_PhiRightVelStdDev : 344|8@1+ (0.001,0) [0|0.25] "1/s"  RadarFrontCenter,DASy
 SG_ VFC_Obj04A_PhiLeftVelStdDev : 352|8@1+ (0.001,0) [0|0.25] "1/s"  RadarFrontCenter,DASy
 SG_ VFC_Obj04A_PhiTop : 360|12@1+ (0.00025,-0.4) [-0.4|0.4] ""  RadarFrontCenter,DASy
 SG_ VFC_Obj04A_PhiBottom : 372|12@1+ (0.00025,-0.4) [-0.4|0.4] ""  RadarFrontCenter,DASy
 SG_ VFC_Obj04A_PhiTopStdDev : 384|8@1+ (0.0002,0) [0|0.05] ""  RadarFrontCenter,DASy
 SG_ VFC_Obj04A_HeadOrientation : 392|4@1+ (1,0) [0|10] ""  RadarFrontCenter,DASy
 SG_ VFC_Obj04A_Type : 396|4@1+ (1,0) [0|15] ""  RadarFrontCenter,DASy
 SG_ VFC_Obj04A_Ax : 39|9@1+ (0.1,-16) [-16|16] "m/s^2"  RadarFrontCenter,DASy
 SG_ VFC_Obj04A_PhiBottomStdDev : 400|8@1+ (0.0002,0) [0|0.05] ""  RadarFrontCenter,DASy
 SG_ VFC_Obj04A_NormVx : 408|16@1+ (0.001,-40) [-40|25] "1/s"  RadarFrontCenter,DASy
 SG_ VFC_Obj04A_NormAx : 424|13@1+ (0.002,-10) [-10|6] "1/s^2"  RadarFrontCenter,DASy
 SG_ VFC_Obj04A_NormAxStdDev : 440|10@1+ (0.0025,0) [0|2.5] "1/s^2"  RadarFrontCenter,DASy
 SG_ VFC_Obj04A_ProbMovingLat : 450|6@1+ (2,0) [0|100] "%"  RadarFrontCenter,DASy
 SG_ VFC_Obj04A_ID : 456|8@1+ (1,0) [0|254] ""  RadarFrontCenter,DASy
 SG_ VFC_Obj04A_NormVxStdDev : 464|10@1+ (0.001,0) [0|1] "1/s"  RadarFrontCenter,DASy
 SG_ VFC_Obj04A_ProbMovingLong : 474|6@1+ (2,0) [0|100] "%"  RadarFrontCenter,DASy
 SG_ VFC_Obj04A_Vx : 48|12@1+ (0.1,-154) [-154|50] "m/s"  RadarFrontCenter,DASy
 SG_ VFC_Obj04A_Dx : 60|12@1+ (0.05,0) [0|204.7] "m"  RadarFrontCenter,DASy
 SG_ VFC_Obj04A_Dy : 72|14@1+ (0.01,-80) [-80|80] "m"  RadarFrontCenter,DASy
 SG_ VFC_Obj04A_Vy : 86|10@1+ (0.1,-50) [-50|50] "m/s"  RadarFrontCenter,DASy
 SG_ VFC_Obj04A_Ay : 96|8@1+ (0.1,-12) [-12|12] "m/s^2"  RadarFrontCenter,DASy

BO_ 185 VFC_Object04B: 16 MPC3
 SG_ VFC_Obj04B_CRC : 0|16@1+ (1,0) [0|65535] ""  RadarFrontCenter,DASy
 SG_ VFC_Obj04B_TTIPC : 104|11@1+ (0.008,-8) [-8|8] ""  RadarFrontCenter,DASy
 SG_ VFC_Obj04B_TTIPC_StdDev : 120|7@1+ (0.0625,0) [0|7.875] ""  RadarFrontCenter,DASy
 SG_ VFC_Obj04B_AliveCtr : 16|8@1+ (1,0) [0|255] ""  RadarFrontCenter,DASy
 SG_ VFC_Obj04B_BlockCtr : 24|4@1+ (1,0) [0|15] ""  RadarFrontCenter,DASy
 SG_ VFC_Obj04B_ScaleChange : 32|14@1+ (0.0001,0.5) [0.5|2.1] ""  RadarFrontCenter,DASy
 SG_ VFC_Obj04B_ScaleChngStdDev : 48|10@1+ (0.0001,0) [0|0.1] ""  RadarFrontCenter,DASy
 SG_ VFC_Obj04B_LineEdgeRightEgo : 58|1@1+ (1,0) [0|1] ""  RadarFrontCenter,DASy
 SG_ VFC_Obj04B_LineEdgeLeftEgo : 59|1@1+ (1,0) [0|1] ""  RadarFrontCenter,DASy
 SG_ VFC_Obj04B_CompletelyInImg : 60|1@1+ (1,0) [0|1] ""  RadarFrontCenter,DASy
 SG_ VFC_Obj04B_DirIndicator : 61|3@1+ (1,0) [0|7] ""  RadarFrontCenter,DASy
 SG_ VFC_Obj04B_LineEdgeAngle : 64|13@1+ (0.00025,-1) [-1|1] "rad"  RadarFrontCenter,DASy
 SG_ VFC_Obj04B_BrakeLight : 77|3@1+ (1,0) [0|7] ""  RadarFrontCenter,DASy
 SG_ VFC_Obj04B_MeasSource : 80|5@1+ (1,0) [0|31] ""  RadarFrontCenter,DASy
 SG_ VFC_Obj04B_AngLongitude : 88|10@1+ (0.005,-2.5) [-2.5|2.5] "rad/s"  RadarFrontCenter,DASy
 SG_ VFC_Obj04B_Reliab : 98|6@1+ (1,0) [0|63] ""  RadarFrontCenter,DASy

BO_ 186 VFC_Object05A: 64 MPC3
 SG_ VFC_Obj05A_CRC : 0|16@1+ (1,0) [0|65535] ""  RadarFrontCenter,DASy
 SG_ VFC_Obj05A_DyStdDev : 104|10@1+ (0.02,0) [0|20] "m"  RadarFrontCenter,DASy
 SG_ VFC_Obj05A_DxStdDev : 118|10@1+ (0.05,0) [0|50] "m"  RadarFrontCenter,DASy
 SG_ VFC_Obj05A_VxStdDev : 128|10@1+ (0.1,0) [0|100] "m/s"  RadarFrontCenter,DASy
 SG_ VFC_Obj05A_ExistProb : 138|6@1+ (2,0) [0|100] "%"  RadarFrontCenter,DASy
 SG_ VFC_Obj05A_VyStdDev : 144|9@1+ (0.1,0) [0|50] "m/s"  RadarFrontCenter,DASy
 SG_ VFC_Obj05A_TypeProb : 154|6@1+ (2,0) [0|100] "%"  RadarFrontCenter,DASy
 SG_ VFC_Obj05A_AxStdDev : 160|8@1+ (0.1,0) [0|25] "m/s^2"  RadarFrontCenter,DASy
 SG_ VFC_Obj05A_AyStdDev : 168|8@1+ (0.1,0) [0|25] "m/s^2"  RadarFrontCenter,DASy
 SG_ VFC_Obj05A_AliveCtr : 16|8@1+ (1,0) [0|255] ""  RadarFrontCenter,DASy
 SG_ VFC_Obj05A_PhiLeft : 176|13@1+ (0.00025,-1) [-1|1] ""  RadarFrontCenter,DASy
 SG_ VFC_Obj05A_ClassifiedView : 189|3@1+ (1,0) [0|7] ""  RadarFrontCenter,DASy
 SG_ VFC_Obj05A_Length : 192|9@1+ (0.05,0) [0|25.5] "m"  RadarFrontCenter,DASy
 SG_ VFC_Obj05A_WidthStdDev : 201|7@1+ (0.01,0) [0|1] "m"  RadarFrontCenter,DASy
 SG_ VFC_Obj05A_Height : 208|9@1+ (0.01,0) [0|5.11] "m"  RadarFrontCenter,DASy
 SG_ VFC_Obj05A_HeightStdDev : 217|7@1+ (0.01,0) [0|1] "m"  RadarFrontCenter,DASy
 SG_ VFC_Obj05A_PhiLeftStdDev : 224|8@1+ (0.0002,0) [0|0.05] ""  RadarFrontCenter,DASy
 SG_ VFC_Obj05A_HeadingStdDev : 232|6@1+ (0.01,0) [0|0.5] "rad"  RadarFrontCenter,DASy
 SG_ VFC_Obj05A_Measured : 238|2@1+ (1,0) [0|3] ""  RadarFrontCenter,DASy
 SG_ VFC_Obj05A_Heading : 240|9@1+ (0.01,-1.57) [-1.57|1.57] "rad"  RadarFrontCenter,DASy
 SG_ VFC_Obj05A_LengthStdDev : 249|7@1+ (0.05,0) [0|5] "m"  RadarFrontCenter,DASy
 SG_ VFC_Obj05A_BlockCtr : 24|4@1+ (1,0) [0|15] ""  RadarFrontCenter,DASy
 SG_ VFC_Obj05A_PhiMid : 256|13@1+ (0.00025,-1) [-1|1] ""  RadarFrontCenter,DASy
 SG_ VFC_Obj05A_Width : 269|11@1+ (0.01,0) [0|12] "m"  RadarFrontCenter,DASy
 SG_ VFC_Obj05A_PhiMidStdDev : 280|8@1+ (0.0002,0) [0|0.05] ""  RadarFrontCenter,DASy
 SG_ VFC_Obj05A_PhiRight : 288|13@1+ (0.00025,-1) [-1|1] ""  RadarFrontCenter,DASy
 SG_ VFC_Obj05A_VisibleView : 301|3@1+ (1,0) [0|4] ""  RadarFrontCenter,DASy
 SG_ VFC_Obj05A_PhiRightStdDev : 304|8@1+ (0.0002,0) [0|0.05] ""  RadarFrontCenter,DASy
 SG_ VFC_Obj05A_PhiLeftVel : 312|13@1+ (0.001,-4) [-4|4] "1/s"  RadarFrontCenter,DASy
 SG_ VFC_Obj05A_PhiRightVel : 328|13@1+ (0.001,-4) [-4|4] "1/s"  RadarFrontCenter,DASy
 SG_ VFC_Obj05A_ProtOrderIndex : 32|6@1+ (1,0) [0|63] ""  RadarFrontCenter,DASy
 SG_ VFC_Obj05A_PhiRightVelStdDev : 344|8@1+ (0.001,0) [0|0.25] "1/s"  RadarFrontCenter,DASy
 SG_ VFC_Obj05A_PhiLeftVelStdDev : 352|8@1+ (0.001,0) [0|0.25] "1/s"  RadarFrontCenter,DASy
 SG_ VFC_Obj05A_PhiTop : 360|12@1+ (0.00025,-0.4) [-0.4|0.4] ""  RadarFrontCenter,DASy
 SG_ VFC_Obj05A_PhiBottom : 372|12@1+ (0.00025,-0.4) [-0.4|0.4] ""  RadarFrontCenter,DASy
 SG_ VFC_Obj05A_PhiTopStdDev : 384|8@1+ (0.0002,0) [0|0.05] ""  RadarFrontCenter,DASy
 SG_ VFC_Obj05A_HeadOrientation : 392|4@1+ (1,0) [0|10] ""  RadarFrontCenter,DASy
 SG_ VFC_Obj05A_Type : 396|4@1+ (1,0) [0|15] ""  RadarFrontCenter,DASy
 SG_ VFC_Obj05A_Ax : 39|9@1+ (0.1,-16) [-16|16] "m/s^2"  RadarFrontCenter,DASy
 SG_ VFC_Obj05A_PhiBottomStdDev : 400|8@1+ (0.0002,0) [0|0.05] ""  RadarFrontCenter,DASy
 SG_ VFC_Obj05A_NormVx : 408|16@1+ (0.001,-40) [-40|25] "1/s"  RadarFrontCenter,DASy
 SG_ VFC_Obj05A_NormAx : 424|13@1+ (0.002,-10) [-10|6] "1/s^2"  RadarFrontCenter,DASy
 SG_ VFC_Obj05A_NormAxStdDev : 440|10@1+ (0.0025,0) [0|2.5] "1/s^2"  RadarFrontCenter,DASy
 SG_ VFC_Obj05A_ProbMovingLat : 450|6@1+ (2,0) [0|100] "%"  RadarFrontCenter,DASy
 SG_ VFC_Obj05A_ID : 456|8@1+ (1,0) [0|254] ""  RadarFrontCenter,DASy
 SG_ VFC_Obj05A_NormVxStdDev : 464|10@1+ (0.001,0) [0|1] "1/s"  RadarFrontCenter,DASy
 SG_ VFC_Obj05A_ProbMovingLong : 474|6@1+ (2,0) [0|100] "%"  RadarFrontCenter,DASy
 SG_ VFC_Obj05A_Vx : 48|12@1+ (0.1,-154) [-154|50] "m/s"  RadarFrontCenter,DASy
 SG_ VFC_Obj05A_Dx : 60|12@1+ (0.05,0) [0|204.7] "m"  RadarFrontCenter,DASy
 SG_ VFC_Obj05A_Dy : 72|14@1+ (0.01,-80) [-80|80] "m"  RadarFrontCenter,DASy
 SG_ VFC_Obj05A_Vy : 86|10@1+ (0.1,-50) [-50|50] "m/s"  RadarFrontCenter,DASy
 SG_ VFC_Obj05A_Ay : 96|8@1+ (0.1,-12) [-12|12] "m/s^2"  RadarFrontCenter,DASy

BO_ 187 VFC_Object05B: 16 MPC3
 SG_ VFC_Obj05B_CRC : 0|16@1+ (1,0) [0|65535] ""  RadarFrontCenter,DASy
 SG_ VFC_Obj05B_TTIPC : 104|11@1+ (0.008,-8) [-8|8] ""  RadarFrontCenter,DASy
 SG_ VFC_Obj05B_TTIPC_StdDev : 120|7@1+ (0.0625,0) [0|7.875] ""  RadarFrontCenter,DASy
 SG_ VFC_Obj05B_AliveCtr : 16|8@1+ (1,0) [0|255] ""  RadarFrontCenter,DASy
 SG_ VFC_Obj05B_BlockCtr : 24|4@1+ (1,0) [0|15] ""  RadarFrontCenter,DASy
 SG_ VFC_Obj05B_ScaleChange : 32|14@1+ (0.0001,0.5) [0.5|2.1] ""  RadarFrontCenter,DASy
 SG_ VFC_Obj05B_ScaleChngStdDev : 48|10@1+ (0.0001,0) [0|0.1] ""  RadarFrontCenter,DASy
 SG_ VFC_Obj05B_LineEdgeRightEgo : 58|1@1+ (1,0) [0|1] ""  RadarFrontCenter,DASy
 SG_ VFC_Obj05B_LineEdgeLeftEgo : 59|1@1+ (1,0) [0|1] ""  RadarFrontCenter,DASy
 SG_ VFC_Obj05B_CompletelyInImg : 60|1@1+ (1,0) [0|1] ""  RadarFrontCenter,DASy
 SG_ VFC_Obj05B_DirIndicator : 61|3@1+ (1,0) [0|7] ""  RadarFrontCenter,DASy
 SG_ VFC_Obj05B_LineEdgeAngle : 64|13@1+ (0.00025,-1) [-1|1] "rad"  RadarFrontCenter,DASy
 SG_ VFC_Obj05B_BrakeLight : 77|3@1+ (1,0) [0|7] ""  RadarFrontCenter,DASy
 SG_ VFC_Obj05B_MeasSource : 80|5@1+ (1,0) [0|31] ""  RadarFrontCenter,DASy
 SG_ VFC_Obj05B_AngLongitude : 88|10@1+ (0.005,-2.5) [-2.5|2.5] "rad/s"  RadarFrontCenter,DASy
 SG_ VFC_Obj05B_Reliab : 98|6@1+ (1,0) [0|63] ""  RadarFrontCenter,DASy

CM_ BO_ 3221225472 "This is a message for not used signals, created by Vector CANdb++ DBC OLE DB Provider.";
CM_ SG_ 3221225472 CrDrLeInnrACRC "CRC";
CM_ SG_ 3221225472 CrDrLeInnrAMsgCtr "Alive Counter";
CM_ SG_ 3221225472 CrDrLeInnrAblockCtr "Block counter for synchronisation";
CM_ SG_ 3221225472 CrDrLeInnrCurvature "Inner curvature of the predicted corridor on left side";
CM_ SG_ 3221225472 CrDrLeInnrCurvChange "Inner curvature change of the predicted corridor on left side";
CM_ SG_ 3221225472 CrDrLeInnrdxEnd "Inner curvature lateral position of the predicted corridor on left side";
CM_ SG_ 3221225472 CrDrLeInnrBCRC "CRC";
CM_ SG_ 3221225472 CrDrLeInnrBMsgCtr "Alive Counter";
CM_ SG_ 3221225472 CrDrLeInnrBblockCtr "Block counter for synchronisation";
CM_ SG_ 3221225472 CrDrLeInnrdy "Inner curvature longitudinal position on left side";
CM_ SG_ 3221225472 CrDrLeInnrYawAngleDiff "Yaw angle difference of inner corridor with reference to vehicle position on left side";
CM_ SG_ 3221225472 CrDrLeInnr_existence_prob "Existance probability of the predicted inner corridor on left side";
CM_ SG_ 3221225472 CrDrLeOutrACRC "CRC";
CM_ SG_ 3221225472 CrDrLeOutrAMsgCtr "Alive Counter";
CM_ SG_ 3221225472 CrDrLeOutrAblockCtr "Block counter for synchronisation";
CM_ SG_ 3221225472 CrDrLeOutrCurvature "Outer curvature of the predicted corridor on left side";
CM_ SG_ 3221225472 CrDrLeOutrCurvChange "Outer curvature change of the predicted corridor on left side";
CM_ SG_ 3221225472 CrDrLeOutrdxEnd "Outer curvature lateral position of the predicted corridor on left side";
CM_ SG_ 3221225472 CrDrLeOutrBCRC "CRC";
CM_ SG_ 3221225472 CrDrLeOutrBMsgCtr "Alive Counter";
CM_ SG_ 3221225472 CrDrLeOutrBblockCtr "Block counter for synchronisation";
CM_ SG_ 3221225472 CrDrLeOutrdy "Outer curvature longitudinal position";
CM_ SG_ 3221225472 CrDrLeOutrYawAngleDiff "Yaw angle difference of Outer corridor with reference to vehicle position on left side";
CM_ SG_ 3221225472 CrDrLeOutr_existence_prob "Existance probability of the predicted inner corridor on left side";
CM_ SG_ 3221225472 CrDrRiInnrACRC "CRC";
CM_ SG_ 3221225472 CrDrRiInnrAMsgCtr "Alive Counter";
CM_ SG_ 3221225472 CrDrRiInnrAblockCtr "Block counter for synchronisation";
CM_ SG_ 3221225472 CrDrRiInnrCurvature "Inner curvature of the predicted corridor on right side";
CM_ SG_ 3221225472 CrDrRiInnrdxEnd "Inner curvature lateral position of the predicted corridor on right side";
CM_ SG_ 3221225472 CrDrRiInnrBCRC "CRC";
CM_ SG_ 3221225472 CrDrRiInnrBMsgCtr "Alive Counter";
CM_ SG_ 3221225472 CrDrRiInnrBblockCtr "Block counter for synchronisation";
CM_ SG_ 3221225472 CrDrRiInnrdy "Inner curvature longitudinal position on right side";
CM_ SG_ 3221225472 CrDrRiInnrYawAngleDiff "Yaw angle difference of inner corridor with reference to vehicle position on right";
CM_ SG_ 3221225472 CrDrRiInnr_existence_prob "Existance probability of the predicted inner corridor on right side";
CM_ SG_ 3221225472 CrDrRiOutrACRC "CRC";
CM_ SG_ 3221225472 CrDrRiOutrAMsgCtr "Alive Counter";
CM_ SG_ 3221225472 CrDrRiOutrAblockCtr "Block counter for synchronisation";
CM_ SG_ 3221225472 CrDrRiOutrCurvature "Outer curvature of the predicted corridor on right side";
CM_ SG_ 3221225472 CrDrRiOutrCurvChange "Outer curvature change of the predicted corridor on right side";
CM_ SG_ 3221225472 CrDrRiOutrdxEnd "Outer curvature lateral position of the predicted corridor on left side";
CM_ SG_ 3221225472 CrDrRiOutrBCRC "CRC";
CM_ SG_ 3221225472 CrDrRiOutrBMsgCtr "Alive Counter";
CM_ SG_ 3221225472 CrDrRiOutrBblockCtr "Block counter for synchronisation";
CM_ SG_ 3221225472 CrDrRiOutrdy "Outer curvature longitudinal position on right side";
CM_ SG_ 3221225472 CrDrRiOutrYawAngleDiff "Yaw angle difference of Outer corridor with reference to vehicle position on right side";
CM_ SG_ 3221225472 CrDrRiOutr_existence_prob "Existance probability of the predicted inner corridor on right side";
CM_ SG_ 3221225472 TargetTrajBCRC "Check Sum";
CM_ SG_ 3221225472 TargetTrajBMsgCtr "Alive counter";
CM_ SG_ 3221225472 TargetTrajBblockCtr "Block counter for synchronisation";
CM_ SG_ 3221225472 TargetTrajExistnceProb "Existance Probability of the determined target trajectory";
CM_ SG_ 3221225472 TargetTrajYawAngleDiff "Yaw Angle difference of the Target Trajectory";
CM_ SG_ 3221225472 VFC_MapInfo_CRC "CRC - Autosar E2E Profile 5";
CM_ SG_ 3221225472 VFC_MapInfo_RoadCurv "the road curvature in the driving direction,
maximum curvature value(minimum radius) within the range of video detection( 150m?)";
CM_ SG_ 3221225472 VFC_MapInfo_CountryCode "country code, ISO3166-1, CN=156";
CM_ SG_ 3221225472 VFC_MapInfo_AliveCtr "Alive counter - Autosar E2E Profile 5";
CM_ SG_ 3221225472 VFC_MapInfo_RoadClass_Offset0 "road class info,at offset 0, that is at the vehicle current position";
CM_ SG_ 3221225472 VFC_MapInfo_RoadClass_Offset200 "road class info,at offset 200 meter";
CM_ SG_ 3221225472 VFC_MapInfo_DiRoad_Offset0 "Road divided info at offset 0 meter";
CM_ SG_ 3221225472 VFC_MapInfo_LaneNum_Offset0 "Lane number info at offset 0 meter";
CM_ SG_ 3221225472 VFC_MapInfo_LaneNum_Offset200 "Lane number info at offset 200 meter";
CM_ SG_ 3221225472 VFC_MapInfo_DiRoad_Offset200 "Road divided info at offset 200 meter";
CM_ SG_ 3221225472 VFC_MapInfo_TollGate_Dx "distance to the tollgate in the driving direction";
CM_ SG_ 3221225472 VFC_MapInfo_TollGate "vehicle relation to the tollgate";
CM_ SG_ 3221225472 VFC_MapInfo_CurrentLane "Current Lane where vehicle is located";
CM_ SG_ 3221225472 VFC_MapInfo_Tunnel_Dx "distance to the tunnel in the driving direction";
CM_ SG_ 3221225472 VFC_MapInfo_Tunnel "vehicle relation to the tunnel";
CM_ SG_ 3221225472 VFC_MapInfo_Bridge_Dx "distance to the bridge in the driving direction";
CM_ SG_ 3221225472 VFC_MapInfo_Bridge "vehicle relation to the bridge";
CM_ SG_ 3221225472 VFC_MapInfo_BuildUp_Dx "distance to the buildup in the driving direction";
CM_ SG_ 3221225472 VFC_MapInfo_BuildUp "vehicle relation to the buildup";
CM_ SG_ 144 RDR_Stat_Error "Radar unit has detected an error with DTC-entry";
CM_ SG_ 144 RDR_Status_MsgCtr "Message counter (rolling counter)";
CM_ SG_ 144 RDR_Status_CRC "CRC8 Checksum";
CM_ SG_ 144 RDR_Status_blockCtr "Control signal to synchronize segmented blocks of object data";
CM_ SG_ 144 RDR_Stat_PED_Brake "System status for the PED emergency braking function";
CM_ SG_ 144 RDR_Stat_ObjDataAge "Time differece between middle of measurement and broadcast on the vehicle bus";
CM_ SG_ 144 RDR_Stat_Avail "Radar unit has detected a temporary non-availability without a DTC entry";
CM_ SG_ 144 RDR_Stat_blindness_det "Blindness detection: Blindness was detected after freesight has been detected earlier";
CM_ SG_ 80 VFC_SensorState_SWVersion "The compensation for norm_vx and norm_vy in FV150 but not exist in FV160, need SIT do it in above FV150 MPC3 SW";
CM_ SG_ 80 VFC_SensorState_CRC "CRC - Autosar E2E Profile 5";
CM_ SG_ 80 VFC_SensorState_AliveCtr "Alive counter - Autosar E2E Profile 5";
CM_ SG_ 80 VFC_SensorState_BlindnessProb "The probability of the overall camera lens being blinded";
CM_ SG_ 80 VFC_SensorState_VisionFault "The current status of the forward looking camera system";
CM_ SG_ 80 VFC_SensorState_VisionDTCs "The current status of the diagnostic";
CM_ SG_ 80 VFC_SensorState_Status "Informs the system of the current state of the camera";
CM_ SG_ 80 VFC_SensorState_ProtocolVersion "Protocol version BCD coded: Major.Minor, e. g. 0x0102 = V1.2 (Checked-In Version)";
CM_ SG_ 80 VFC_SensorState_Report "The status report of the vision system";
CM_ SG_ 128 VFC_LineHdr_CRC "CRC - Autosar E2E Profile 5";
CM_ SG_ 128 VFC_LineHdr_AliveCtr "Alive counter - Autosar E2E Profile 5";
CM_ SG_ 128 VFC_LineHdr_BlockCounter "Protocol-Signal:Blockcounter";
CM_ SG_ 128 VFC_LineHdr_FrameNo "The frame number that the data belongs to";
CM_ SG_ 128 VFC_LineHdr_Report "Bitmask for Errors if PEPSI was not executed";
CM_ SG_ 128 VFC_LineHdr_LineCount "Number of Lines to be send (max 15)";
CM_ SG_ 128 VFC_LineHdr_PEPSIRuntime "Last runtime of the PEPSI Algorithm. As PEPSI does runtime management, this can be used as an indicator for the quality of the results.";
CM_ SG_ 128 VFC_LineHdr_TimeStamp "TimeStamp of Clothoids when lines are measured, for 1R1V sensor set";
CM_ SG_ 128 VFC_LineHdr_Blindness "Blindness Indicator for Lines";
CM_ SG_ 128 VFC_LineHdr_State "Informs the system of the current state of the camera";
CM_ SG_ 128 VFC_LineHdr_AUTOSARTStamp "Time stamp when Clothoids measurement, in autosar time sync mode";
CM_ SG_ 129 VFC_Line01_CRC "CRC - Autosar E2E Profile 5";
CM_ SG_ 129 VFC_Line01_Dy "Dy at position of DxStart  (not always x=0, because of high values for 2nd segment)";
CM_ SG_ 129 VFC_Line01_CurvChange "Currvature change or alteration of the Line, also called kappaDt";
CM_ SG_ 129 VFC_Line01_Curv "Curvature of the Line, also called kappa";
CM_ SG_ 129 VFC_Line01_MeasureType "Indicates if Line was measured, interpolated or inferred (virtual line)";
CM_ SG_ 129 VFC_Line01_LineWidth "Width of the line";
CM_ SG_ 129 VFC_Line01_CourseDeviation "Confidence measure quantifying a weighted deviation between course/path and the predicted lane";
CM_ SG_ 129 VFC_Line01_Type "Type of the Line";
CM_ SG_ 129 VFC_Line01_DyStdDevDxEnd "Standard deviation of the lateral offset, at point of DxEnd";
CM_ SG_ 129 VFC_Line01_AliveCtr "Alive counter - Autosar E2E Profile 5";
CM_ SG_ 129 VFC_Line01_HypoConfidence "multiple hypothesis info. from Video (ambiguity ID)";
CM_ SG_ 129 VFC_Line01_prevID "when in multi-segment, prevID is used to show that the current line ID is from which previous ID";
CM_ SG_ 129 VFC_Line01_nextID "when in multi-segment, nextID is used to show that which line ID is next to the current line ID";
CM_ SG_ 129 VFC_Line01_DyStdDevDxStart "Standard deviation of the lateral offset, at point of DxStart";
CM_ SG_ 129 VFC_Line01_TypeProb "Confidence measure for Type classification";
CM_ SG_ 129 VFC_Line01_DyStdDevDxMid "Standard deviation of the lateral offset, at point of DxMid, DyStdDevDxMid (dxMid = (dxEnd-dxStart)/2 )";
CM_ SG_ 129 VFC_Line01_BlockCounter "Protocol-Signal:Blockcounter";
CM_ SG_ 129 VFC_Line01_ProtOrderIndex "Protocol-Signal: Index to ensure same order in Tx and Rx of the clothoids";
CM_ SG_ 129 VFC_Line01_LineID "Object ID is used to order the Objects in line";
CM_ SG_ 129 VFC_Line01_LaneRelation "Indicating its position relative to the ego lane";
CM_ SG_ 129 VFC_Line01_ExistProb "Confidence for this line";
CM_ SG_ 129 VFC_Line01_DxStart "Longitudinal start point of the line, also called dxStart";
CM_ SG_ 129 VFC_Line01_ColorClass "The color of the line";
CM_ SG_ 129 VFC_Line01_DxEnd "Longitudinal range of the line, also called dxEnd";
CM_ SG_ 129 VFC_Line01_HeadingAngle "Heading angle, difference in yaw angle between vehicle heading and Line";
CM_ SG_ 130 VFC_Line02_CRC "CRC - Autosar E2E Profile 5";
CM_ SG_ 130 VFC_Line02_Dy "Dy at position of DxStart  (not always x=0, because of high values for 2nd segment)";
CM_ SG_ 130 VFC_Line02_CurvChange "Currvature change or alteration of the Line, also called kappaDt";
CM_ SG_ 130 VFC_Line02_Curv "Curvature of the Line, also called kappa";
CM_ SG_ 130 VFC_Line02_MeasureType "Indicates if Line was measured, interpolated or inferred (virtual line)";
CM_ SG_ 130 VFC_Line02_LineWidth "Width of the line";
CM_ SG_ 130 VFC_Line02_CourseDeviation "Confidence measure quantifying a weighted deviation between course/path and the predicted lane";
CM_ SG_ 130 VFC_Line02_Type "Type of the Line";
CM_ SG_ 130 VFC_Line02_DyStdDevDxEnd "Standard deviation of the lateral offset, at point of DxEnd";
CM_ SG_ 130 VFC_Line02_AliveCtr "Alive counter - Autosar E2E Profile 5";
CM_ SG_ 130 VFC_Line02_HypoConfidence "multiple hypothesis info. from Video (ambiguity ID)";
CM_ SG_ 130 VFC_Line02_prevID "when in multi-segment, prevID is used to show that the current line ID is from which previous ID";
CM_ SG_ 130 VFC_Line02_nextID "when in multi-segment, nextID is used to show that which line ID is next to the current line ID";
CM_ SG_ 130 VFC_Line02_DyStdDevDxStart "Standard deviation of the lateral offset, at point of DxStart";
CM_ SG_ 130 VFC_Line02_TypeProb "Confidence measure for Type classification";
CM_ SG_ 130 VFC_Line02_DyStdDevDxMid "Standard deviation of the lateral offset, at point of DxMid, DyStdDevDxMid (dxMid = (dxEnd-dxStart)/2 )";
CM_ SG_ 130 VFC_Line02_BlockCounter "Protocol-Signal:Blockcounter";
CM_ SG_ 130 VFC_Line02_ProtOrderIndex "Protocol-Signal: Index to ensure same order in Tx and Rx of the clothoids";
CM_ SG_ 130 VFC_Line02_LineID "Object ID is used to order the Objects in line";
CM_ SG_ 130 VFC_Line02_LaneRelation "Indicating its position relative to the ego lane";
CM_ SG_ 130 VFC_Line02_ExistProb "Confidence for this line";
CM_ SG_ 130 VFC_Line02_DxStart "Longitudinal start point of the line, also called dxStart";
CM_ SG_ 130 VFC_Line02_ColorClass "The color of the line";
CM_ SG_ 130 VFC_Line02_DxEnd "Longitudinal range of the line, also called dxEnd";
CM_ SG_ 130 VFC_Line02_HeadingAngle "Heading angle, difference in yaw angle between vehicle heading and Line";
CM_ SG_ 131 VFC_Line03_CRC "CRC - Autosar E2E Profile 5";
CM_ SG_ 131 VFC_Line03_Dy "Dy at position of DxStart  (not always x=0, because of high values for 2nd segment)";
CM_ SG_ 131 VFC_Line03_CurvChange "Currvature change or alteration of the Line, also called kappaDt";
CM_ SG_ 131 VFC_Line03_Curv "Curvature of the Line, also called kappa";
CM_ SG_ 131 VFC_Line03_MeasureType "Indicates if Line was measured, interpolated or inferred (virtual line)";
CM_ SG_ 131 VFC_Line03_LineWidth "Width of the line";
CM_ SG_ 131 VFC_Line03_CourseDeviation "Confidence measure quantifying a weighted deviation between course/path and the predicted lane";
CM_ SG_ 131 VFC_Line03_Type "Type of the Line";
CM_ SG_ 131 VFC_Line03_DyStdDevDxEnd "Standard deviation of the lateral offset, at point of DxEnd";
CM_ SG_ 131 VFC_Line03_AliveCtr "Alive counter - Autosar E2E Profile 5";
CM_ SG_ 131 VFC_Line03_HypoConfidence "multiple hypothesis info. from Video (ambiguity ID)";
CM_ SG_ 131 VFC_Line03_prevID "when in multi-segment, prevID is used to show that the current line ID is from which previous ID";
CM_ SG_ 131 VFC_Line03_nextID "when in multi-segment, nextID is used to show that which line ID is next to the current line ID";
CM_ SG_ 131 VFC_Line03_DyStdDevDxStart "Standard deviation of the lateral offset, at point of DxStart";
CM_ SG_ 131 VFC_Line03_TypeProb "Confidence measure for Type classification";
CM_ SG_ 131 VFC_Line03_DyStdDevDxMid "Standard deviation of the lateral offset, at point of DxMid, DyStdDevDxMid (dxMid = (dxEnd-dxStart)/2 )";
CM_ SG_ 131 VFC_Line03_BlockCounter "Protocol-Signal:Blockcounter";
CM_ SG_ 131 VFC_Line03_ProtOrderIndex "Protocol-Signal: Index to ensure same order in Tx and Rx of the clothoids";
CM_ SG_ 131 VFC_Line03_LineID "Object ID is used to order the Objects in line";
CM_ SG_ 131 VFC_Line03_LaneRelation "Indicating its position relative to the ego lane";
CM_ SG_ 131 VFC_Line03_ExistProb "Confidence for this line";
CM_ SG_ 131 VFC_Line03_DxStart "Longitudinal start point of the line, also called dxStart";
CM_ SG_ 131 VFC_Line03_ColorClass "The color of the line";
CM_ SG_ 131 VFC_Line03_DxEnd "Longitudinal range of the line, also called dxEnd";
CM_ SG_ 131 VFC_Line03_HeadingAngle "Heading angle, difference in yaw angle between vehicle heading and Line";
CM_ SG_ 132 VFC_Line04_CRC "CRC - Autosar E2E Profile 5";
CM_ SG_ 132 VFC_Line04_Dy "Dy at position of DxStart  (not always x=0, because of high values for 2nd segment)";
CM_ SG_ 132 VFC_Line04_CurvChange "Currvature change or alteration of the Line, also called kappaDt";
CM_ SG_ 132 VFC_Line04_Curv "Curvature of the Line, also called kappa";
CM_ SG_ 132 VFC_Line04_MeasureType "Indicates if Line was measured, interpolated or inferred (virtual line)";
CM_ SG_ 132 VFC_Line04_LineWidth "Width of the line";
CM_ SG_ 132 VFC_Line04_CourseDeviation "Confidence measure quantifying a weighted deviation between course/path and the predicted lane";
CM_ SG_ 132 VFC_Line04_Type "Type of the Line";
CM_ SG_ 132 VFC_Line04_DyStdDevDxEnd "Standard deviation of the lateral offset, at point of DxEnd";
CM_ SG_ 132 VFC_Line04_AliveCtr "Alive counter - Autosar E2E Profile 5";
CM_ SG_ 132 VFC_Line04_HypoConfidence "multiple hypothesis info. from Video (ambiguity ID)";
CM_ SG_ 132 VFC_Line04_prevID "when in multi-segment, prevID is used to show that the current line ID is from which previous ID";
CM_ SG_ 132 VFC_Line04_nextID "when in multi-segment, nextID is used to show that which line ID is next to the current line ID";
CM_ SG_ 132 VFC_Line04_DyStdDevDxStart "Standard deviation of the lateral offset, at point of DxStart";
CM_ SG_ 132 VFC_Line04_TypeProb "Confidence measure for Type classification";
CM_ SG_ 132 VFC_Line04_DyStdDevDxMid "Standard deviation of the lateral offset, at point of DxMid, DyStdDevDxMid (dxMid = (dxEnd-dxStart)/2 )";
CM_ SG_ 132 VFC_Line04_BlockCounter "Protocol-Signal:Blockcounter";
CM_ SG_ 132 VFC_Line04_ProtOrderIndex "Protocol-Signal: Index to ensure same order in Tx and Rx of the clothoids";
CM_ SG_ 132 VFC_Line04_LineID "Object ID is used to order the Objects in line";
CM_ SG_ 132 VFC_Line04_LaneRelation "Indicating its position relative to the ego lane";
CM_ SG_ 132 VFC_Line04_ExistProb "Confidence for this line";
CM_ SG_ 132 VFC_Line04_DxStart "Longitudinal start point of the line, also called dxStart";
CM_ SG_ 132 VFC_Line04_ColorClass "The color of the line";
CM_ SG_ 132 VFC_Line04_DxEnd "Longitudinal range of the line, also called dxEnd";
CM_ SG_ 132 VFC_Line04_HeadingAngle "Heading angle, difference in yaw angle between vehicle heading and Line";
CM_ SG_ 133 VFC_Line05_CRC "CRC - Autosar E2E Profile 5";
CM_ SG_ 133 VFC_Line05_Dy "Dy at position of DxStart  (not always x=0, because of high values for 2nd segment)";
CM_ SG_ 133 VFC_Line05_CurvChange "Currvature change or alteration of the Line, also called kappaDt";
CM_ SG_ 133 VFC_Line05_Curv "Curvature of the Line, also called kappa";
CM_ SG_ 133 VFC_Line05_MeasureType "Indicates if Line was measured, interpolated or inferred (virtual line)";
CM_ SG_ 133 VFC_Line05_LineWidth "Width of the line";
CM_ SG_ 133 VFC_Line05_CourseDeviation "Confidence measure quantifying a weighted deviation between course/path and the predicted lane";
CM_ SG_ 133 VFC_Line05_Type "Type of the Line";
CM_ SG_ 133 VFC_Line05_DyStdDevDxEnd "Standard deviation of the lateral offset, at point of DxEnd";
CM_ SG_ 133 VFC_Line05_AliveCtr "Alive counter - Autosar E2E Profile 5";
CM_ SG_ 133 VFC_Line05_HypoConfidence "multiple hypothesis info. from Video (ambiguity ID)";
CM_ SG_ 133 VFC_Line05_prevID "when in multi-segment, prevID is used to show that the current line ID is from which previous ID";
CM_ SG_ 133 VFC_Line05_nextID "when in multi-segment, nextID is used to show that which line ID is next to the current line ID";
CM_ SG_ 133 VFC_Line05_DyStdDevDxStart "Standard deviation of the lateral offset, at point of DxStart";
CM_ SG_ 133 VFC_Line05_TypeProb "Confidence measure for Type classification";
CM_ SG_ 133 VFC_Line05_DyStdDevDxMid "Standard deviation of the lateral offset, at point of DxMid, DyStdDevDxMid (dxMid = (dxEnd-dxStart)/2 )";
CM_ SG_ 133 VFC_Line05_BlockCounter "Protocol-Signal:Blockcounter";
CM_ SG_ 133 VFC_Line05_ProtOrderIndex "Protocol-Signal: Index to ensure same order in Tx and Rx of the clothoids";
CM_ SG_ 133 VFC_Line05_LineID "Object ID is used to order the Objects in line";
CM_ SG_ 133 VFC_Line05_LaneRelation "Indicating its position relative to the ego lane";
CM_ SG_ 133 VFC_Line05_ExistProb "Confidence for this line";
CM_ SG_ 133 VFC_Line05_DxStart "Longitudinal start point of the line, also called dxStart";
CM_ SG_ 133 VFC_Line05_ColorClass "The color of the line";
CM_ SG_ 133 VFC_Line05_DxEnd "Longitudinal range of the line, also called dxEnd";
CM_ SG_ 133 VFC_Line05_HeadingAngle "Heading angle, difference in yaw angle between vehicle heading and Line";
CM_ SG_ 134 VFC_Line06_CRC "CRC - Autosar E2E Profile 5";
CM_ SG_ 134 VFC_Line06_Dy "Dy at position of DxStart  (not always x=0, because of high values for 2nd segment)";
CM_ SG_ 134 VFC_Line06_CurvChange "Currvature change or alteration of the Line, also called kappaDt";
CM_ SG_ 134 VFC_Line06_Curv "Curvature of the Line, also called kappa";
CM_ SG_ 134 VFC_Line06_MeasureType "Indicates if Line was measured, interpolated or inferred (virtual line)";
CM_ SG_ 134 VFC_Line06_LineWidth "Width of the line";
CM_ SG_ 134 VFC_Line06_CourseDeviation "Confidence measure quantifying a weighted deviation between course/path and the predicted lane";
CM_ SG_ 134 VFC_Line06_Type "Type of the Line";
CM_ SG_ 134 VFC_Line06_DyStdDevDxEnd "Standard deviation of the lateral offset, at point of DxEnd";
CM_ SG_ 134 VFC_Line06_AliveCtr "Alive counter - Autosar E2E Profile 5";
CM_ SG_ 134 VFC_Line06_HypoConfidence "multiple hypothesis info. from Video (ambiguity ID)";
CM_ SG_ 134 VFC_Line06_prevID "when in multi-segment, prevID is used to show that the current line ID is from which previous ID";
CM_ SG_ 134 VFC_Line06_nextID "when in multi-segment, nextID is used to show that which line ID is next to the current line ID";
CM_ SG_ 134 VFC_Line06_DyStdDevDxStart "Standard deviation of the lateral offset, at point of DxStart";
CM_ SG_ 134 VFC_Line06_TypeProb "Confidence measure for Type classification";
CM_ SG_ 134 VFC_Line06_DyStdDevDxMid "Standard deviation of the lateral offset, at point of DxMid, DyStdDevDxMid (dxMid = (dxEnd-dxStart)/2 )";
CM_ SG_ 134 VFC_Line06_BlockCounter "Protocol-Signal:Blockcounter";
CM_ SG_ 134 VFC_Line06_ProtOrderIndex "Protocol-Signal: Index to ensure same order in Tx and Rx of the clothoids";
CM_ SG_ 134 VFC_Line06_LineID "Object ID is used to order the Objects in line";
CM_ SG_ 134 VFC_Line06_LaneRelation "Indicating its position relative to the ego lane";
CM_ SG_ 134 VFC_Line06_ExistProb "Confidence for this line";
CM_ SG_ 134 VFC_Line06_DxStart "Longitudinal start point of the line, also called dxStart";
CM_ SG_ 134 VFC_Line06_ColorClass "The color of the line";
CM_ SG_ 134 VFC_Line06_DxEnd "Longitudinal range of the line, also called dxEnd";
CM_ SG_ 134 VFC_Line06_HeadingAngle "Heading angle, difference in yaw angle between vehicle heading and Line";
CM_ SG_ 135 VFC_Line07_CRC "CRC - Autosar E2E Profile 5";
CM_ SG_ 135 VFC_Line07_Dy "Dy at position of DxStart  (not always x=0, because of high values for 2nd segment)";
CM_ SG_ 135 VFC_Line07_CurvChange "Currvature change or alteration of the Line, also called kappaDt";
CM_ SG_ 135 VFC_Line07_Curv "Curvature of the Line, also called kappa";
CM_ SG_ 135 VFC_Line07_MeasureType "Indicates if Line was measured, interpolated or inferred (virtual line)";
CM_ SG_ 135 VFC_Line07_LineWidth "Width of the line";
CM_ SG_ 135 VFC_Line07_CourseDeviation "Confidence measure quantifying a weighted deviation between course/path and the predicted lane";
CM_ SG_ 135 VFC_Line07_Type "Type of the Line";
CM_ SG_ 135 VFC_Line07_DyStdDevDxEnd "Standard deviation of the lateral offset, at point of DxEnd";
CM_ SG_ 135 VFC_Line07_AliveCtr "Alive counter - Autosar E2E Profile 5";
CM_ SG_ 135 VFC_Line07_HypoConfidence "multiple hypothesis info. from Video (ambiguity ID)";
CM_ SG_ 135 VFC_Line07_prevID "when in multi-segment, prevID is used to show that the current line ID is from which previous ID";
CM_ SG_ 135 VFC_Line07_nextID "when in multi-segment, nextID is used to show that which line ID is next to the current line ID";
CM_ SG_ 135 VFC_Line07_DyStdDevDxStart "Standard deviation of the lateral offset, at point of DxStart";
CM_ SG_ 135 VFC_Line07_TypeProb "Confidence measure for Type classification";
CM_ SG_ 135 VFC_Line07_DyStdDevDxMid "Standard deviation of the lateral offset, at point of DxMid, DyStdDevDxMid (dxMid = (dxEnd-dxStart)/2 )";
CM_ SG_ 135 VFC_Line07_BlockCounter "Protocol-Signal:Blockcounter";
CM_ SG_ 135 VFC_Line07_ProtOrderIndex "Protocol-Signal: Index to ensure same order in Tx and Rx of the clothoids";
CM_ SG_ 135 VFC_Line07_LineID "Object ID is used to order the Objects in line";
CM_ SG_ 135 VFC_Line07_LaneRelation "Indicating its position relative to the ego lane";
CM_ SG_ 135 VFC_Line07_ExistProb "Confidence for this line";
CM_ SG_ 135 VFC_Line07_DxStart "Longitudinal start point of the line, also called dxStart";
CM_ SG_ 135 VFC_Line07_ColorClass "The color of the line";
CM_ SG_ 135 VFC_Line07_DxEnd "Longitudinal range of the line, also called dxEnd";
CM_ SG_ 135 VFC_Line07_HeadingAngle "Heading angle, difference in yaw angle between vehicle heading and Line";
CM_ SG_ 136 VFC_Line08_CRC "CRC - Autosar E2E Profile 5";
CM_ SG_ 136 VFC_Line08_Dy "Dy at position of DxStart  (not always x=0, because of high values for 2nd segment)";
CM_ SG_ 136 VFC_Line08_CurvChange "Currvature change or alteration of the Line, also called kappaDt";
CM_ SG_ 136 VFC_Line08_Curv "Curvature of the Line, also called kappa";
CM_ SG_ 136 VFC_Line08_MeasureType "Indicates if Line was measured, interpolated or inferred (virtual line)";
CM_ SG_ 136 VFC_Line08_LineWidth "Width of the line";
CM_ SG_ 136 VFC_Line08_CourseDeviation "Confidence measure quantifying a weighted deviation between course/path and the predicted lane";
CM_ SG_ 136 VFC_Line08_Type "Type of the Line";
CM_ SG_ 136 VFC_Line08_DyStdDevDxEnd "Standard deviation of the lateral offset, at point of DxEnd";
CM_ SG_ 136 VFC_Line08_AliveCtr "Alive counter - Autosar E2E Profile 5";
CM_ SG_ 136 VFC_Line08_HypoConfidence "multiple hypothesis info. from Video (ambiguity ID)";
CM_ SG_ 136 VFC_Line08_prevID "when in multi-segment, prevID is used to show that the current line ID is from which previous ID";
CM_ SG_ 136 VFC_Line08_nextID "when in multi-segment, nextID is used to show that which line ID is next to the current line ID";
CM_ SG_ 136 VFC_Line08_DyStdDevDxStart "Standard deviation of the lateral offset, at point of DxStart";
CM_ SG_ 136 VFC_Line08_TypeProb "Confidence measure for Type classification";
CM_ SG_ 136 VFC_Line08_DyStdDevDxMid "Standard deviation of the lateral offset, at point of DxMid, DyStdDevDxMid (dxMid = (dxEnd-dxStart)/2 )";
CM_ SG_ 136 VFC_Line08_BlockCounter "Protocol-Signal:Blockcounter";
CM_ SG_ 136 VFC_Line08_ProtOrderIndex "Protocol-Signal: Index to ensure same order in Tx and Rx of the clothoids";
CM_ SG_ 136 VFC_Line08_LineID "Object ID is used to order the Objects in line";
CM_ SG_ 136 VFC_Line08_LaneRelation "Indicating its position relative to the ego lane";
CM_ SG_ 136 VFC_Line08_ExistProb "Confidence for this line";
CM_ SG_ 136 VFC_Line08_DxStart "Longitudinal start point of the line, also called dxStart";
CM_ SG_ 136 VFC_Line08_ColorClass "The color of the line";
CM_ SG_ 136 VFC_Line08_DxEnd "Longitudinal range of the line, also called dxEnd";
CM_ SG_ 136 VFC_Line08_HeadingAngle "Heading angle, difference in yaw angle between vehicle heading and Line";
CM_ SG_ 160 VFC_ObjHdr_Scenario "indicate it's daytme or night";
CM_ SG_ 160 VFC_ObjHdr_CRC "CRC - Autosar E2E Profile 5";
CM_ SG_ 160 VFC_ObjHdr_CalibRollStdDev "The standard deviation of the calibrated roll angle of the camera";
CM_ SG_ 160 VFC_ObjHdr_CalibYawAngle "The calibrated yaw angle of the camera";
CM_ SG_ 160 VFC_ObjHdr_CalibYawStdDev "The standard deviation of the calibrated yaw angle of the camera";
CM_ SG_ 160 VFC_ObjHdr_MountPosX "The current estimation of the mounting position of the camera in the longitudinal direction";
CM_ SG_ 160 VFC_ObjHdr_AliveCtr "Alive counter - Autosar E2E Profile 5";
CM_ SG_ 160 VFC_ObjHdr_CalibState "The calibration state of the forward looking camera system";
CM_ SG_ 160 VFC_ObjHdr_MountPosY "The current estimation of mounting position of the camera in the lateral direction";
CM_ SG_ 160 VFC_ObjHdr_MountPosZ "The current estimation of mounting position of the camera in the vertical direction";
CM_ SG_ 160 VFC_ObjHdr_CycleTime "Camera Cycle Time";
CM_ SG_ 160 VFC_ObjHdr_AUTOSARTStamp "The timestamp of when object is measured, in AUTOSAR Time Sync mode";
CM_ SG_ 160 VFC_ObjHdr_TimeStampStatus "Autosar StbM_TimeBaseStatusType bitfield with extension:
Bit 0: TIMEOUT
Bit 1: Reserved1
Bit 2: SYNC_TO_GATEWAY
Bit 3: GLOBAL_TIME_BASE
Bit 4: TIMELEAP_FUTURE
Bit 5: TIMELEAP_PAST
Bit 6: Reserved6
Bit 7: Extension: GENERAL_ERROR";
CM_ SG_ 160 VFC_ObjHdr_BlockCtr "Protocol-Signal: Block-Counter";
CM_ SG_ 160 VFC_ObjHdr_FrameNo "The frame number that the data belongs to";
CM_ SG_ 160 VFC_ObjHdr_TimeStamp "The timestamp of when object is measured, or
Time gap between object data measure and send (only in 1R1V)";
CM_ SG_ 160 VFC_ObjHdr_Blindness "Informs the system whether the current object detection is blind or not blind";
CM_ SG_ 160 VFC_ObjHdr_CalibPitchAngle "The calibrated pitch angle of the camera";
CM_ SG_ 160 VFC_ObjHdr_FreeViewProb "The probability of the camera lens being blocked";
CM_ SG_ 160 VFC_ObjHdr_CalibPitchStdDev "The standard deviation of the calibrated pitch angle of the camera";
CM_ SG_ 160 VFC_ObjHdr_ObjCount "Number of objects that have been detected by the system";
CM_ SG_ 160 VFC_ObjHdr_CalibRollAngle "The calibrated roll angle of the camera";
CM_ SG_ 176 VFC_Obj00A_CRC "CRC - Autosar E2E Profile 5";
CM_ SG_ 176 VFC_Obj00A_DyStdDev "Standard deviation of Object position in lateral direction";
CM_ SG_ 176 VFC_Obj00A_DxStdDev "Standard deviation of Object position in longitudinal direction";
CM_ SG_ 176 VFC_Obj00A_VxStdDev "Standard deviation of Object velocity in longitudinal direction";
CM_ SG_ 176 VFC_Obj00A_ExistProb "Object existence probability";
CM_ SG_ 176 VFC_Obj00A_VyStdDev "Standard deviation of Object velocity in lateral direction";
CM_ SG_ 176 VFC_Obj00A_TypeProb "Probability of the classified object type";
CM_ SG_ 176 VFC_Obj00A_AxStdDev "Standard deviation of Object acceleration in longitudinal direction";
CM_ SG_ 176 VFC_Obj00A_AyStdDev "Standard deviation of Object acceleration in lateral direction";
CM_ SG_ 176 VFC_Obj00A_AliveCtr "Alive counter - Autosar E2E Profile 5";
CM_ SG_ 176 VFC_Obj00A_PhiLeft "ACCS Viewing Angle of left object edge(dimensionless)";
CM_ SG_ 176 VFC_Obj00A_ClassifiedView "The classified view of object to be used in connection with Heading angle";
CM_ SG_ 176 VFC_Obj00A_Length "Length of the object";
CM_ SG_ 176 VFC_Obj00A_WidthStdDev "Standard deviation of object width";
CM_ SG_ 176 VFC_Obj00A_Height "Height of the object";
CM_ SG_ 176 VFC_Obj00A_HeightStdDev "Standard deviation of object height";
CM_ SG_ 176 VFC_Obj00A_PhiLeftStdDev "Standard deviation of the ACCS angle of left object(dimensionless)";
CM_ SG_ 176 VFC_Obj00A_HeadingStdDev "Standard deviation of object Heading angle";
CM_ SG_ 176 VFC_Obj00A_Measured "Indicator if the object detected is measured or predicted.";
CM_ SG_ 176 VFC_Obj00A_Heading "Heading angle of the object";
CM_ SG_ 176 VFC_Obj00A_LengthStdDev "Standard deviation of object length";
CM_ SG_ 176 VFC_Obj00A_BlockCtr "Protocol-Signal: Block-Counter";
CM_ SG_ 176 VFC_Obj00A_PhiMid "Viewing angle of the ACCS middle of the object(dimensionless)";
CM_ SG_ 176 VFC_Obj00A_Width "Width of the object";
CM_ SG_ 176 VFC_Obj00A_PhiMidStdDev "Standard deviation of the ACCS middle angle of object(dimensionless)";
CM_ SG_ 176 VFC_Obj00A_PhiRight "ACCS Viewing Angle of right object edge(dimensionless)";
CM_ SG_ 176 VFC_Obj00A_VisibleView "The visible view of the detectd object";
CM_ SG_ 176 VFC_Obj00A_PhiRightStdDev "Standard deviation of the ACCS angle of right object(dimensionless)";
CM_ SG_ 176 VFC_Obj00A_PhiLeftVel "Velocity of the ACCS viewing angle of the left edge";
CM_ SG_ 176 VFC_Obj00A_PhiRightVel "Velocity of the ACCS viewing angle of the right edge";
CM_ SG_ 176 VFC_Obj00A_ProtOrderIndex "Protocol-Signal: Index to ensure same order in Tx and Rx of the objects";
CM_ SG_ 176 VFC_Obj00A_PhiRightVelStdDev "Standard deviation of ACCS viewing angle velocity of right object edge from ego vehicle related to camera";
CM_ SG_ 176 VFC_Obj00A_PhiLeftVelStdDev "Standard deviation of ACCS viewing angle velocity of left object edge from ego vehicle related to camera";
CM_ SG_ 176 VFC_Obj00A_PhiTop "ACCS Viewing angle of the top of the object(dimensionless)";
CM_ SG_ 176 VFC_Obj00A_PhiBottom "ACCS Viewing angle of the bottom of the object(dimensionless)";
CM_ SG_ 176 VFC_Obj00A_PhiTopStdDev "Standard deviation  of the ACCS top angle of object(dimensionless)";
CM_ SG_ 176 VFC_Obj00A_HeadOrientation "The orientation of the head of cyclists or pedestrians that are detected.";
CM_ SG_ 176 VFC_Obj00A_Type "Classification of the object";
CM_ SG_ 176 VFC_Obj00A_Ax "Object Acceleration in longitudinal direction";
CM_ SG_ 176 VFC_Obj00A_PhiBottomStdDev "Standard deviation of the ACCS bottom angle of object(dimensionless)";
CM_ SG_ 176 VFC_Obj00A_NormVx "Normalised object velocity in longitudinal direction.";
CM_ SG_ 176 VFC_Obj00A_NormAx "Normalised object acceleration in longitudinal direction.";
CM_ SG_ 176 VFC_Obj00A_NormAxStdDev "Standard deviation of Normalized Object Acceleration in longitudinal direction";
CM_ SG_ 176 VFC_Obj00A_ProbMovingLat "Probability of object moving laterally";
CM_ SG_ 176 VFC_Obj00A_ID "Unique Object ID";
CM_ SG_ 176 VFC_Obj00A_NormVxStdDev "Standard deviation of Normalized Object Velocity in longitudinal direction";
CM_ SG_ 176 VFC_Obj00A_ProbMovingLong "Probability of object moving longitudinally";
CM_ SG_ 176 VFC_Obj00A_Vx "Object Velocity in longitudinal direction";
CM_ SG_ 176 VFC_Obj00A_Dx "Object Position in longitudinal direction";
CM_ SG_ 176 VFC_Obj00A_Dy "Object Position in lateral direction";
CM_ SG_ 176 VFC_Obj00A_Vy "Object Velocity in lateral direction";
CM_ SG_ 176 VFC_Obj00A_Ay "Object Acceleration in lateral direction";
CM_ SG_ 177 VFC_Obj00B_CRC "CRC - Autosar E2E Profile 5";
CM_ SG_ 177 VFC_Obj00B_TTIPC "Inverse TTI";
CM_ SG_ 177 VFC_Obj00B_TTIPC_StdDev "Inverse TTI standard deviation";
CM_ SG_ 177 VFC_Obj00B_AliveCtr "Alive counter - Autosar E2E Profile 5";
CM_ SG_ 177 VFC_Obj00B_BlockCtr "Protocol-Signal: Block Counter";
CM_ SG_ 177 VFC_Obj00B_ScaleChange "A scale change of of the detected object";
CM_ SG_ 177 VFC_Obj00B_ScaleChngStdDev "Standard deviation of object scale change";
CM_ SG_ 177 VFC_Obj00B_LineEdgeRightEgo "ObjLineEdgeAngle refers to the line which limits the host vehicle lane on the right side";
CM_ SG_ 177 VFC_Obj00B_LineEdgeLeftEgo "ObjLineEdgeAngle refers to the line which limits the host vehicle lane on the left side";
CM_ SG_ 177 VFC_Obj00B_CompletelyInImg "indicator if the object is completely measrued in the image";
CM_ SG_ 177 VFC_Obj00B_DirIndicator "The detected direction indicator lights";
CM_ SG_ 177 VFC_Obj00B_LineEdgeAngle "Angle between the video object's edge and the lane marking";
CM_ SG_ 177 VFC_Obj00B_BrakeLight "The number of detected lights. More confident if more lights are detected.";
CM_ SG_ 177 VFC_Obj00B_MeasSource "Bitmask for the measurement programs from which this object originates";
CM_ SG_ 177 VFC_Obj00B_AngLongitude "angular velocity with regarding to longitudinal direction";
CM_ SG_ 177 VFC_Obj00B_Reliab "Bitmask that indicates the algorithmic paths that have detected this object
NOT_RELIABLE=0 (Bit5==0)";
CM_ SG_ 178 VFC_Obj01A_CRC "CRC - Autosar E2E Profile 5";
CM_ SG_ 178 VFC_Obj01A_DyStdDev "Standard deviation of Object position in lateral direction";
CM_ SG_ 178 VFC_Obj01A_DxStdDev "Standard deviation of Object position in longitudinal direction";
CM_ SG_ 178 VFC_Obj01A_VxStdDev "Standard deviation of Object velocity in longitudinal direction";
CM_ SG_ 178 VFC_Obj01A_ExistProb "Object existence probability";
CM_ SG_ 178 VFC_Obj01A_VyStdDev "Standard deviation of Object velocity in lateral direction";
CM_ SG_ 178 VFC_Obj01A_TypeProb "Probability of the classified object type";
CM_ SG_ 178 VFC_Obj01A_AxStdDev "Standard deviation of Object acceleration in longitudinal direction";
CM_ SG_ 178 VFC_Obj01A_AyStdDev "Standard deviation of Object acceleration in lateral direction";
CM_ SG_ 178 VFC_Obj01A_AliveCtr "Alive counter - Autosar E2E Profile 5";
CM_ SG_ 178 VFC_Obj01A_PhiLeft "ACCS Viewing Angle of left object edge(dimensionless)";
CM_ SG_ 178 VFC_Obj01A_ClassifiedView "The classified view of object to be used in connection with Heading angle";
CM_ SG_ 178 VFC_Obj01A_Length "Length of the object";
CM_ SG_ 178 VFC_Obj01A_WidthStdDev "Standard deviation of object width";
CM_ SG_ 178 VFC_Obj01A_Height "Height of the object";
CM_ SG_ 178 VFC_Obj01A_HeightStdDev "Standard deviation of object height";
CM_ SG_ 178 VFC_Obj01A_PhiLeftStdDev "Standard deviation of the ACCS angle of left object(dimensionless)";
CM_ SG_ 178 VFC_Obj01A_HeadingStdDev "Standard deviation of object Heading angle";
CM_ SG_ 178 VFC_Obj01A_Measured "Indicator if the object detected is measured or predicted.";
CM_ SG_ 178 VFC_Obj01A_Heading "Heading angle of the object";
CM_ SG_ 178 VFC_Obj01A_LengthStdDev "Standard deviation of object length";
CM_ SG_ 178 VFC_Obj01A_BlockCtr "Protocol-Signal: Block-Counter";
CM_ SG_ 178 VFC_Obj01A_PhiMid "Viewing angle of the ACCS middle of the object(dimensionless)";
CM_ SG_ 178 VFC_Obj01A_Width "Width of the object";
CM_ SG_ 178 VFC_Obj01A_PhiMidStdDev "Standard deviation of the ACCS middle angle of object(dimensionless)";
CM_ SG_ 178 VFC_Obj01A_PhiRight "ACCS Viewing Angle of right object edge(dimensionless)";
CM_ SG_ 178 VFC_Obj01A_VisibleView "The visible view of the detectd object";
CM_ SG_ 178 VFC_Obj01A_PhiRightStdDev "Standard deviation of the ACCS angle of right object(dimensionless)";
CM_ SG_ 178 VFC_Obj01A_PhiLeftVel "Velocity of the ACCS viewing angle of the left edge";
CM_ SG_ 178 VFC_Obj01A_PhiRightVel "Velocity of the ACCS viewing angle of the right edge";
CM_ SG_ 178 VFC_Obj01A_ProtOrderIndex "Protocol-Signal: Index to ensure same order in Tx and Rx of the objects";
CM_ SG_ 178 VFC_Obj01A_PhiRightVelStdDev "Standard deviation of ACCS viewing angle velocity of right object edge from ego vehicle related to camera";
CM_ SG_ 178 VFC_Obj01A_PhiLeftVelStdDev "Standard deviation of ACCS viewing angle velocity of left object edge from ego vehicle related to camera";
CM_ SG_ 178 VFC_Obj01A_PhiTop "ACCS Viewing angle of the top of the object(dimensionless)";
CM_ SG_ 178 VFC_Obj01A_PhiBottom "ACCS Viewing angle of the bottom of the object(dimensionless)";
CM_ SG_ 178 VFC_Obj01A_PhiTopStdDev "Standard deviation  of the ACCS top angle of object(dimensionless)";
CM_ SG_ 178 VFC_Obj01A_HeadOrientation "The orientation of the head of cyclists or pedestrians that are detected.";
CM_ SG_ 178 VFC_Obj01A_Type "Classification of the object";
CM_ SG_ 178 VFC_Obj01A_Ax "Object Acceleration in longitudinal direction";
CM_ SG_ 178 VFC_Obj01A_PhiBottomStdDev "Standard deviation of the ACCS bottom angle of object(dimensionless)";
CM_ SG_ 178 VFC_Obj01A_NormVx "Normalised object velocity in longitudinal direction.";
CM_ SG_ 178 VFC_Obj01A_NormAx "Normalised object acceleration in longitudinal direction.";
CM_ SG_ 178 VFC_Obj01A_NormAxStdDev "Standard deviation of Normalized Object Acceleration in longitudinal direction";
CM_ SG_ 178 VFC_Obj01A_ProbMovingLat "Probability of object moving laterally";
CM_ SG_ 178 VFC_Obj01A_ID "Unique Object ID";
CM_ SG_ 178 VFC_Obj01A_NormVxStdDev "Standard deviation of Normalized Object Velocity in longitudinal direction";
CM_ SG_ 178 VFC_Obj01A_ProbMovingLong "Probability of object moving longitudinally";
CM_ SG_ 178 VFC_Obj01A_Vx "Object Velocity in longitudinal direction";
CM_ SG_ 178 VFC_Obj01A_Dx "Object Position in longitudinal direction";
CM_ SG_ 178 VFC_Obj01A_Dy "Object Position in lateral direction";
CM_ SG_ 178 VFC_Obj01A_Vy "Object Velocity in lateral direction";
CM_ SG_ 178 VFC_Obj01A_Ay "Object Acceleration in lateral direction";
CM_ SG_ 179 VFC_Obj01B_CRC "CRC - Autosar E2E Profile 5";
CM_ SG_ 179 VFC_Obj01B_TTIPC "Inverse TTI";
CM_ SG_ 179 VFC_Obj01B_TTIPC_StdDev "Inverse TTI standard deviation";
CM_ SG_ 179 VFC_Obj01B_AliveCtr "Alive counter - Autosar E2E Profile 5";
CM_ SG_ 179 VFC_Obj01B_BlockCtr "Protocol-Signal: Block Counter";
CM_ SG_ 179 VFC_Obj01B_ScaleChange "A scale change of of the detected object";
CM_ SG_ 179 VFC_Obj01B_ScaleChngStdDev "Standard deviation of object scale change";
CM_ SG_ 179 VFC_Obj01B_LineEdgeRightEgo "ObjLineEdgeAngle refers to the line which limits the host vehicle lane on the right side";
CM_ SG_ 179 VFC_Obj01B_LineEdgeLeftEgo "ObjLineEdgeAngle refers to the line which limits the host vehicle lane on the left side";
CM_ SG_ 179 VFC_Obj01B_CompletelyInImg "indicator if the object is completely measrued in the image";
CM_ SG_ 179 VFC_Obj01B_DirIndicator "The detected direction indicator lights";
CM_ SG_ 179 VFC_Obj01B_LineEdgeAngle "Angle between the video object's edge and the lane marking";
CM_ SG_ 179 VFC_Obj01B_BrakeLight "The number of detected lights. More confident if more lights are detected.";
CM_ SG_ 179 VFC_Obj01B_MeasSource "Bitmask for the measurement programs from which this object originates";
CM_ SG_ 179 VFC_Obj01B_AngLongitude "angular velocity with regarding to longitudinal direction";
CM_ SG_ 179 VFC_Obj01B_Reliab "Bitmask that indicates the algorithmic paths that have detected this object
NOT_RELIABLE=0 (Bit5==0)";
CM_ SG_ 180 VFC_Obj02A_CRC "CRC - Autosar E2E Profile 5";
CM_ SG_ 180 VFC_Obj02A_DyStdDev "Standard deviation of Object position in lateral direction";
CM_ SG_ 180 VFC_Obj02A_DxStdDev "Standard deviation of Object position in longitudinal direction";
CM_ SG_ 180 VFC_Obj02A_VxStdDev "Standard deviation of Object velocity in longitudinal direction";
CM_ SG_ 180 VFC_Obj02A_ExistProb "Object existence probability";
CM_ SG_ 180 VFC_Obj02A_VyStdDev "Standard deviation of Object velocity in lateral direction";
CM_ SG_ 180 VFC_Obj02A_TypeProb "Probability of the classified object type";
CM_ SG_ 180 VFC_Obj02A_AxStdDev "Standard deviation of Object acceleration in longitudinal direction";
CM_ SG_ 180 VFC_Obj02A_AyStdDev "Standard deviation of Object acceleration in lateral direction";
CM_ SG_ 180 VFC_Obj02A_AliveCtr "Alive counter - Autosar E2E Profile 5";
CM_ SG_ 180 VFC_Obj02A_PhiLeft "ACCS Viewing Angle of left object edge(dimensionless)";
CM_ SG_ 180 VFC_Obj02A_ClassifiedView "The classified view of object to be used in connection with Heading angle";
CM_ SG_ 180 VFC_Obj02A_Length "Length of the object";
CM_ SG_ 180 VFC_Obj02A_WidthStdDev "Standard deviation of object width";
CM_ SG_ 180 VFC_Obj02A_Height "Height of the object";
CM_ SG_ 180 VFC_Obj02A_HeightStdDev "Standard deviation of object height";
CM_ SG_ 180 VFC_Obj02A_PhiLeftStdDev "Standard deviation of the ACCS angle of left object(dimensionless)";
CM_ SG_ 180 VFC_Obj02A_HeadingStdDev "Standard deviation of object Heading angle";
CM_ SG_ 180 VFC_Obj02A_Measured "Indicator if the object detected is measured or predicted.";
CM_ SG_ 180 VFC_Obj02A_Heading "Heading angle of the object";
CM_ SG_ 180 VFC_Obj02A_LengthStdDev "Standard deviation of object length";
CM_ SG_ 180 VFC_Obj02A_BlockCtr "Protocol-Signal: Block-Counter";
CM_ SG_ 180 VFC_Obj02A_PhiMid "Viewing angle of the ACCS middle of the object(dimensionless)";
CM_ SG_ 180 VFC_Obj02A_Width "Width of the object";
CM_ SG_ 180 VFC_Obj02A_PhiMidStdDev "Standard deviation of the ACCS middle angle of object(dimensionless)";
CM_ SG_ 180 VFC_Obj02A_PhiRight "ACCS Viewing Angle of right object edge(dimensionless)";
CM_ SG_ 180 VFC_Obj02A_VisibleView "The visible view of the detectd object";
CM_ SG_ 180 VFC_Obj02A_PhiRightStdDev "Standard deviation of the ACCS angle of right object(dimensionless)";
CM_ SG_ 180 VFC_Obj02A_PhiLeftVel "Velocity of the ACCS viewing angle of the left edge";
CM_ SG_ 180 VFC_Obj02A_PhiRightVel "Velocity of the ACCS viewing angle of the right edge";
CM_ SG_ 180 VFC_Obj02A_ProtOrderIndex "Protocol-Signal: Index to ensure same order in Tx and Rx of the objects";
CM_ SG_ 180 VFC_Obj02A_PhiRightVelStdDev "Standard deviation of ACCS viewing angle velocity of right object edge from ego vehicle related to camera";
CM_ SG_ 180 VFC_Obj02A_PhiLeftVelStdDev "Standard deviation of ACCS viewing angle velocity of left object edge from ego vehicle related to camera";
CM_ SG_ 180 VFC_Obj02A_PhiTop "ACCS Viewing angle of the top of the object(dimensionless)";
CM_ SG_ 180 VFC_Obj02A_PhiBottom "ACCS Viewing angle of the bottom of the object(dimensionless)";
CM_ SG_ 180 VFC_Obj02A_PhiTopStdDev "Standard deviation  of the ACCS top angle of object(dimensionless)";
CM_ SG_ 180 VFC_Obj02A_HeadOrientation "The orientation of the head of cyclists or pedestrians that are detected.";
CM_ SG_ 180 VFC_Obj02A_Type "Classification of the object";
CM_ SG_ 180 VFC_Obj02A_Ax "Object Acceleration in longitudinal direction";
CM_ SG_ 180 VFC_Obj02A_PhiBottomStdDev "Standard deviation of the ACCS bottom angle of object(dimensionless)";
CM_ SG_ 180 VFC_Obj02A_NormVx "Normalised object velocity in longitudinal direction.";
CM_ SG_ 180 VFC_Obj02A_NormAx "Normalised object acceleration in longitudinal direction.";
CM_ SG_ 180 VFC_Obj02A_NormAxStdDev "Standard deviation of Normalized Object Acceleration in longitudinal direction";
CM_ SG_ 180 VFC_Obj02A_ProbMovingLat "Probability of object moving laterally";
CM_ SG_ 180 VFC_Obj02A_ID "Unique Object ID";
CM_ SG_ 180 VFC_Obj02A_NormVxStdDev "Standard deviation of Normalized Object Velocity in longitudinal direction";
CM_ SG_ 180 VFC_Obj02A_ProbMovingLong "Probability of object moving longitudinally";
CM_ SG_ 180 VFC_Obj02A_Vx "Object Velocity in longitudinal direction";
CM_ SG_ 180 VFC_Obj02A_Dx "Object Position in longitudinal direction";
CM_ SG_ 180 VFC_Obj02A_Dy "Object Position in lateral direction";
CM_ SG_ 180 VFC_Obj02A_Vy "Object Velocity in lateral direction";
CM_ SG_ 180 VFC_Obj02A_Ay "Object Acceleration in lateral direction";
CM_ SG_ 181 VFC_Obj02B_CRC "CRC - Autosar E2E Profile 5";
CM_ SG_ 181 VFC_Obj02B_TTIPC "Inverse TTI";
CM_ SG_ 181 VFC_Obj02B_TTIPC_StdDev "Inverse TTI standard deviation";
CM_ SG_ 181 VFC_Obj02B_AliveCtr "Alive counter - Autosar E2E Profile 5";
CM_ SG_ 181 VFC_Obj02B_BlockCtr "Protocol-Signal: Block Counter";
CM_ SG_ 181 VFC_Obj02B_ScaleChange "A scale change of of the detected object";
CM_ SG_ 181 VFC_Obj02B_ScaleChngStdDev "Standard deviation of object scale change";
CM_ SG_ 181 VFC_Obj02B_LineEdgeRightEgo "ObjLineEdgeAngle refers to the line which limits the host vehicle lane on the right side";
CM_ SG_ 181 VFC_Obj02B_LineEdgeLeftEgo "ObjLineEdgeAngle refers to the line which limits the host vehicle lane on the left side";
CM_ SG_ 181 VFC_Obj02B_CompletelyInImg "indicator if the object is completely measrued in the image";
CM_ SG_ 181 VFC_Obj02B_DirIndicator "The detected direction indicator lights";
CM_ SG_ 181 VFC_Obj02B_LineEdgeAngle "Angle between the video object's edge and the lane marking";
CM_ SG_ 181 VFC_Obj02B_BrakeLight "The number of detected lights. More confident if more lights are detected.";
CM_ SG_ 181 VFC_Obj02B_MeasSource "Bitmask for the measurement programs from which this object originates";
CM_ SG_ 181 VFC_Obj02B_AngLongitude "angular velocity with regarding to longitudinal direction";
CM_ SG_ 181 VFC_Obj02B_Reliab "Bitmask that indicates the algorithmic paths that have detected this object
NOT_RELIABLE=0 (Bit5==0)";
CM_ SG_ 182 VFC_Obj03A_CRC "CRC - Autosar E2E Profile 5";
CM_ SG_ 182 VFC_Obj03A_DyStdDev "Standard deviation of Object position in lateral direction";
CM_ SG_ 182 VFC_Obj03A_DxStdDev "Standard deviation of Object position in longitudinal direction";
CM_ SG_ 182 VFC_Obj03A_VxStdDev "Standard deviation of Object velocity in longitudinal direction";
CM_ SG_ 182 VFC_Obj03A_ExistProb "Object existence probability";
CM_ SG_ 182 VFC_Obj03A_VyStdDev "Standard deviation of Object velocity in lateral direction";
CM_ SG_ 182 VFC_Obj03A_TypeProb "Probability of the classified object type";
CM_ SG_ 182 VFC_Obj03A_AxStdDev "Standard deviation of Object acceleration in longitudinal direction";
CM_ SG_ 182 VFC_Obj03A_AyStdDev "Standard deviation of Object acceleration in lateral direction";
CM_ SG_ 182 VFC_Obj03A_AliveCtr "Alive counter - Autosar E2E Profile 5";
CM_ SG_ 182 VFC_Obj03A_PhiLeft "ACCS Viewing Angle of left object edge(dimensionless)";
CM_ SG_ 182 VFC_Obj03A_ClassifiedView "The classified view of object to be used in connection with Heading angle";
CM_ SG_ 182 VFC_Obj03A_Length "Length of the object";
CM_ SG_ 182 VFC_Obj03A_WidthStdDev "Standard deviation of object width";
CM_ SG_ 182 VFC_Obj03A_Height "Height of the object";
CM_ SG_ 182 VFC_Obj03A_HeightStdDev "Standard deviation of object height";
CM_ SG_ 182 VFC_Obj03A_PhiLeftStdDev "Standard deviation of the ACCS angle of left object(dimensionless)";
CM_ SG_ 182 VFC_Obj03A_HeadingStdDev "Standard deviation of object Heading angle";
CM_ SG_ 182 VFC_Obj03A_Measured "Indicator if the object detected is measured or predicted.";
CM_ SG_ 182 VFC_Obj03A_Heading "Heading angle of the object";
CM_ SG_ 182 VFC_Obj03A_LengthStdDev "Standard deviation of object length";
CM_ SG_ 182 VFC_Obj03A_BlockCtr "Protocol-Signal: Block-Counter";
CM_ SG_ 182 VFC_Obj03A_PhiMid "Viewing angle of the ACCS middle of the object(dimensionless)";
CM_ SG_ 182 VFC_Obj03A_Width "Width of the object";
CM_ SG_ 182 VFC_Obj03A_PhiMidStdDev "Standard deviation of the ACCS middle angle of object(dimensionless)";
CM_ SG_ 182 VFC_Obj03A_PhiRight "ACCS Viewing Angle of right object edge(dimensionless)";
CM_ SG_ 182 VFC_Obj03A_VisibleView "The visible view of the detectd object";
CM_ SG_ 182 VFC_Obj03A_PhiRightStdDev "Standard deviation of the ACCS angle of right object(dimensionless)";
CM_ SG_ 182 VFC_Obj03A_PhiLeftVel "Velocity of the ACCS viewing angle of the left edge";
CM_ SG_ 182 VFC_Obj03A_PhiRightVel "Velocity of the ACCS viewing angle of the right edge";
CM_ SG_ 182 VFC_Obj03A_ProtOrderIndex "Protocol-Signal: Index to ensure same order in Tx and Rx of the objects";
CM_ SG_ 182 VFC_Obj03A_PhiRightVelStdDev "Standard deviation of ACCS viewing angle velocity of right object edge from ego vehicle related to camera";
CM_ SG_ 182 VFC_Obj03A_PhiLeftVelStdDev "Standard deviation of ACCS viewing angle velocity of left object edge from ego vehicle related to camera";
CM_ SG_ 182 VFC_Obj03A_PhiTop "ACCS Viewing angle of the top of the object(dimensionless)";
CM_ SG_ 182 VFC_Obj03A_PhiBottom "ACCS Viewing angle of the bottom of the object(dimensionless)";
CM_ SG_ 182 VFC_Obj03A_PhiTopStdDev "Standard deviation  of the ACCS top angle of object(dimensionless)";
CM_ SG_ 182 VFC_Obj03A_HeadOrientation "The orientation of the head of cyclists or pedestrians that are detected.";
CM_ SG_ 182 VFC_Obj03A_Type "Classification of the object";
CM_ SG_ 182 VFC_Obj03A_Ax "Object Acceleration in longitudinal direction";
CM_ SG_ 182 VFC_Obj03A_PhiBottomStdDev "Standard deviation of the ACCS bottom angle of object(dimensionless)";
CM_ SG_ 182 VFC_Obj03A_NormVx "Normalised object velocity in longitudinal direction.";
CM_ SG_ 182 VFC_Obj03A_NormAx "Normalised object acceleration in longitudinal direction.";
CM_ SG_ 182 VFC_Obj03A_NormAxStdDev "Standard deviation of Normalized Object Acceleration in longitudinal direction";
CM_ SG_ 182 VFC_Obj03A_ProbMovingLat "Probability of object moving laterally";
CM_ SG_ 182 VFC_Obj03A_ID "Unique Object ID";
CM_ SG_ 182 VFC_Obj03A_NormVxStdDev "Standard deviation of Normalized Object Velocity in longitudinal direction";
CM_ SG_ 182 VFC_Obj03A_ProbMovingLong "Probability of object moving longitudinally";
CM_ SG_ 182 VFC_Obj03A_Vx "Object Velocity in longitudinal direction";
CM_ SG_ 182 VFC_Obj03A_Dx "Object Position in longitudinal direction";
CM_ SG_ 182 VFC_Obj03A_Dy "Object Position in lateral direction";
CM_ SG_ 182 VFC_Obj03A_Vy "Object Velocity in lateral direction";
CM_ SG_ 182 VFC_Obj03A_Ay "Object Acceleration in lateral direction";
CM_ SG_ 183 VFC_Obj03B_CRC "CRC - Autosar E2E Profile 5";
CM_ SG_ 183 VFC_Obj03B_TTIPC "Inverse TTI";
CM_ SG_ 183 VFC_Obj03B_TTIPC_StdDev "Inverse TTI standard deviation";
CM_ SG_ 183 VFC_Obj03B_AliveCtr "Alive counter - Autosar E2E Profile 5";
CM_ SG_ 183 VFC_Obj03B_BlockCtr "Protocol-Signal: Block Counter";
CM_ SG_ 183 VFC_Obj03B_ScaleChange "A scale change of of the detected object";
CM_ SG_ 183 VFC_Obj03B_ScaleChngStdDev "Standard deviation of object scale change";
CM_ SG_ 183 VFC_Obj03B_LineEdgeRightEgo "ObjLineEdgeAngle refers to the line which limits the host vehicle lane on the right side";
CM_ SG_ 183 VFC_Obj03B_LineEdgeLeftEgo "ObjLineEdgeAngle refers to the line which limits the host vehicle lane on the left side";
CM_ SG_ 183 VFC_Obj03B_CompletelyInImg "indicator if the object is completely measrued in the image";
CM_ SG_ 183 VFC_Obj03B_DirIndicator "The detected direction indicator lights";
CM_ SG_ 183 VFC_Obj03B_LineEdgeAngle "Angle between the video object's edge and the lane marking";
CM_ SG_ 183 VFC_Obj03B_BrakeLight "The number of detected lights. More confident if more lights are detected.";
CM_ SG_ 183 VFC_Obj03B_MeasSource "Bitmask for the measurement programs from which this object originates";
CM_ SG_ 183 VFC_Obj03B_AngLongitude "angular velocity with regarding to longitudinal direction";
CM_ SG_ 183 VFC_Obj03B_Reliab "Bitmask that indicates the algorithmic paths that have detected this object
NOT_RELIABLE=0 (Bit5==0)";
CM_ SG_ 184 VFC_Obj04A_CRC "CRC - Autosar E2E Profile 5";
CM_ SG_ 184 VFC_Obj04A_DyStdDev "Standard deviation of Object position in lateral direction";
CM_ SG_ 184 VFC_Obj04A_DxStdDev "Standard deviation of Object position in longitudinal direction";
CM_ SG_ 184 VFC_Obj04A_VxStdDev "Standard deviation of Object velocity in longitudinal direction";
CM_ SG_ 184 VFC_Obj04A_ExistProb "Object existence probability";
CM_ SG_ 184 VFC_Obj04A_VyStdDev "Standard deviation of Object velocity in lateral direction";
CM_ SG_ 184 VFC_Obj04A_TypeProb "Probability of the classified object type";
CM_ SG_ 184 VFC_Obj04A_AxStdDev "Standard deviation of Object acceleration in longitudinal direction";
CM_ SG_ 184 VFC_Obj04A_AyStdDev "Standard deviation of Object acceleration in lateral direction";
CM_ SG_ 184 VFC_Obj04A_AliveCtr "Alive counter - Autosar E2E Profile 5";
CM_ SG_ 184 VFC_Obj04A_PhiLeft "ACCS Viewing Angle of left object edge(dimensionless)";
CM_ SG_ 184 VFC_Obj04A_ClassifiedView "The classified view of object to be used in connection with Heading angle";
CM_ SG_ 184 VFC_Obj04A_Length "Length of the object";
CM_ SG_ 184 VFC_Obj04A_WidthStdDev "Standard deviation of object width";
CM_ SG_ 184 VFC_Obj04A_Height "Height of the object";
CM_ SG_ 184 VFC_Obj04A_HeightStdDev "Standard deviation of object height";
CM_ SG_ 184 VFC_Obj04A_PhiLeftStdDev "Standard deviation of the ACCS angle of left object(dimensionless)";
CM_ SG_ 184 VFC_Obj04A_HeadingStdDev "Standard deviation of object Heading angle";
CM_ SG_ 184 VFC_Obj04A_Measured "Indicator if the object detected is measured or predicted.";
CM_ SG_ 184 VFC_Obj04A_Heading "Heading angle of the object";
CM_ SG_ 184 VFC_Obj04A_LengthStdDev "Standard deviation of object length";
CM_ SG_ 184 VFC_Obj04A_BlockCtr "Protocol-Signal: Block-Counter";
CM_ SG_ 184 VFC_Obj04A_PhiMid "Viewing angle of the ACCS middle of the object(dimensionless)";
CM_ SG_ 184 VFC_Obj04A_Width "Width of the object";
CM_ SG_ 184 VFC_Obj04A_PhiMidStdDev "Standard deviation of the ACCS middle angle of object(dimensionless)";
CM_ SG_ 184 VFC_Obj04A_PhiRight "ACCS Viewing Angle of right object edge(dimensionless)";
CM_ SG_ 184 VFC_Obj04A_VisibleView "The visible view of the detectd object";
CM_ SG_ 184 VFC_Obj04A_PhiRightStdDev "Standard deviation of the ACCS angle of right object(dimensionless)";
CM_ SG_ 184 VFC_Obj04A_PhiLeftVel "Velocity of the ACCS viewing angle of the left edge";
CM_ SG_ 184 VFC_Obj04A_PhiRightVel "Velocity of the ACCS viewing angle of the right edge";
CM_ SG_ 184 VFC_Obj04A_ProtOrderIndex "Protocol-Signal: Index to ensure same order in Tx and Rx of the objects";
CM_ SG_ 184 VFC_Obj04A_PhiRightVelStdDev "Standard deviation of ACCS viewing angle velocity of right object edge from ego vehicle related to camera";
CM_ SG_ 184 VFC_Obj04A_PhiLeftVelStdDev "Standard deviation of ACCS viewing angle velocity of left object edge from ego vehicle related to camera";
CM_ SG_ 184 VFC_Obj04A_PhiTop "ACCS Viewing angle of the top of the object(dimensionless)";
CM_ SG_ 184 VFC_Obj04A_PhiBottom "ACCS Viewing angle of the bottom of the object(dimensionless)";
CM_ SG_ 184 VFC_Obj04A_PhiTopStdDev "Standard deviation  of the ACCS top angle of object(dimensionless)";
CM_ SG_ 184 VFC_Obj04A_HeadOrientation "The orientation of the head of cyclists or pedestrians that are detected.";
CM_ SG_ 184 VFC_Obj04A_Type "Classification of the object";
CM_ SG_ 184 VFC_Obj04A_Ax "Object Acceleration in longitudinal direction";
CM_ SG_ 184 VFC_Obj04A_PhiBottomStdDev "Standard deviation of the ACCS bottom angle of object(dimensionless)";
CM_ SG_ 184 VFC_Obj04A_NormVx "Normalised object velocity in longitudinal direction.";
CM_ SG_ 184 VFC_Obj04A_NormAx "Normalised object acceleration in longitudinal direction.";
CM_ SG_ 184 VFC_Obj04A_NormAxStdDev "Standard deviation of Normalized Object Acceleration in longitudinal direction";
CM_ SG_ 184 VFC_Obj04A_ProbMovingLat "Probability of object moving laterally";
CM_ SG_ 184 VFC_Obj04A_ID "Unique Object ID";
CM_ SG_ 184 VFC_Obj04A_NormVxStdDev "Standard deviation of Normalized Object Velocity in longitudinal direction";
CM_ SG_ 184 VFC_Obj04A_ProbMovingLong "Probability of object moving longitudinally";
CM_ SG_ 184 VFC_Obj04A_Vx "Object Velocity in longitudinal direction";
CM_ SG_ 184 VFC_Obj04A_Dx "Object Position in longitudinal direction";
CM_ SG_ 184 VFC_Obj04A_Dy "Object Position in lateral direction";
CM_ SG_ 184 VFC_Obj04A_Vy "Object Velocity in lateral direction";
CM_ SG_ 184 VFC_Obj04A_Ay "Object Acceleration in lateral direction";
CM_ SG_ 185 VFC_Obj04B_CRC "CRC - Autosar E2E Profile 5";
CM_ SG_ 185 VFC_Obj04B_TTIPC "Inverse TTI";
CM_ SG_ 185 VFC_Obj04B_TTIPC_StdDev "Inverse TTI standard deviation";
CM_ SG_ 185 VFC_Obj04B_AliveCtr "Alive counter - Autosar E2E Profile 5";
CM_ SG_ 185 VFC_Obj04B_BlockCtr "Protocol-Signal: Block Counter";
CM_ SG_ 185 VFC_Obj04B_ScaleChange "A scale change of of the detected object";
CM_ SG_ 185 VFC_Obj04B_ScaleChngStdDev "Standard deviation of object scale change";
CM_ SG_ 185 VFC_Obj04B_LineEdgeRightEgo "ObjLineEdgeAngle refers to the line which limits the host vehicle lane on the right side";
CM_ SG_ 185 VFC_Obj04B_LineEdgeLeftEgo "ObjLineEdgeAngle refers to the line which limits the host vehicle lane on the left side";
CM_ SG_ 185 VFC_Obj04B_CompletelyInImg "indicator if the object is completely measrued in the image";
CM_ SG_ 185 VFC_Obj04B_DirIndicator "The detected direction indicator lights";
CM_ SG_ 185 VFC_Obj04B_LineEdgeAngle "Angle between the video object's edge and the lane marking";
CM_ SG_ 185 VFC_Obj04B_BrakeLight "The number of detected lights. More confident if more lights are detected.";
CM_ SG_ 185 VFC_Obj04B_MeasSource "Bitmask for the measurement programs from which this object originates";
CM_ SG_ 185 VFC_Obj04B_AngLongitude "angular velocity with regarding to longitudinal direction";
CM_ SG_ 185 VFC_Obj04B_Reliab "Bitmask that indicates the algorithmic paths that have detected this object
NOT_RELIABLE=0 (Bit5==0)";
CM_ SG_ 186 VFC_Obj05A_CRC "CRC - Autosar E2E Profile 5";
CM_ SG_ 186 VFC_Obj05A_DyStdDev "Standard deviation of Object position in lateral direction";
CM_ SG_ 186 VFC_Obj05A_DxStdDev "Standard deviation of Object position in longitudinal direction";
CM_ SG_ 186 VFC_Obj05A_VxStdDev "Standard deviation of Object velocity in longitudinal direction";
CM_ SG_ 186 VFC_Obj05A_ExistProb "Object existence probability";
CM_ SG_ 186 VFC_Obj05A_VyStdDev "Standard deviation of Object velocity in lateral direction";
CM_ SG_ 186 VFC_Obj05A_TypeProb "Probability of the classified object type";
CM_ SG_ 186 VFC_Obj05A_AxStdDev "Standard deviation of Object acceleration in longitudinal direction";
CM_ SG_ 186 VFC_Obj05A_AyStdDev "Standard deviation of Object acceleration in lateral direction";
CM_ SG_ 186 VFC_Obj05A_AliveCtr "Alive counter - Autosar E2E Profile 5";
CM_ SG_ 186 VFC_Obj05A_PhiLeft "ACCS Viewing Angle of left object edge(dimensionless)";
CM_ SG_ 186 VFC_Obj05A_ClassifiedView "The classified view of object to be used in connection with Heading angle";
CM_ SG_ 186 VFC_Obj05A_Length "Length of the object";
CM_ SG_ 186 VFC_Obj05A_WidthStdDev "Standard deviation of object width";
CM_ SG_ 186 VFC_Obj05A_Height "Height of the object";
CM_ SG_ 186 VFC_Obj05A_HeightStdDev "Standard deviation of object height";
CM_ SG_ 186 VFC_Obj05A_PhiLeftStdDev "Standard deviation of the ACCS angle of left object(dimensionless)";
CM_ SG_ 186 VFC_Obj05A_HeadingStdDev "Standard deviation of object Heading angle";
CM_ SG_ 186 VFC_Obj05A_Measured "Indicator if the object detected is measured or predicted.";
CM_ SG_ 186 VFC_Obj05A_Heading "Heading angle of the object";
CM_ SG_ 186 VFC_Obj05A_LengthStdDev "Standard deviation of object length";
CM_ SG_ 186 VFC_Obj05A_BlockCtr "Protocol-Signal: Block-Counter";
CM_ SG_ 186 VFC_Obj05A_PhiMid "Viewing angle of the ACCS middle of the object(dimensionless)";
CM_ SG_ 186 VFC_Obj05A_Width "Width of the object";
CM_ SG_ 186 VFC_Obj05A_PhiMidStdDev "Standard deviation of the ACCS middle angle of object(dimensionless)";
CM_ SG_ 186 VFC_Obj05A_PhiRight "ACCS Viewing Angle of right object edge(dimensionless)";
CM_ SG_ 186 VFC_Obj05A_VisibleView "The visible view of the detectd object";
CM_ SG_ 186 VFC_Obj05A_PhiRightStdDev "Standard deviation of the ACCS angle of right object(dimensionless)";
CM_ SG_ 186 VFC_Obj05A_PhiLeftVel "Velocity of the ACCS viewing angle of the left edge";
CM_ SG_ 186 VFC_Obj05A_PhiRightVel "Velocity of the ACCS viewing angle of the right edge";
CM_ SG_ 186 VFC_Obj05A_ProtOrderIndex "Protocol-Signal: Index to ensure same order in Tx and Rx of the objects";
CM_ SG_ 186 VFC_Obj05A_PhiRightVelStdDev "Standard deviation of ACCS viewing angle velocity of right object edge from ego vehicle related to camera";
CM_ SG_ 186 VFC_Obj05A_PhiLeftVelStdDev "Standard deviation of ACCS viewing angle velocity of left object edge from ego vehicle related to camera";
CM_ SG_ 186 VFC_Obj05A_PhiTop "ACCS Viewing angle of the top of the object(dimensionless)";
CM_ SG_ 186 VFC_Obj05A_PhiBottom "ACCS Viewing angle of the bottom of the object(dimensionless)";
CM_ SG_ 186 VFC_Obj05A_PhiTopStdDev "Standard deviation  of the ACCS top angle of object(dimensionless)";
CM_ SG_ 186 VFC_Obj05A_HeadOrientation "The orientation of the head of cyclists or pedestrians that are detected.";
CM_ SG_ 186 VFC_Obj05A_Type "Classification of the object";
CM_ SG_ 186 VFC_Obj05A_Ax "Object Acceleration in longitudinal direction";
CM_ SG_ 186 VFC_Obj05A_PhiBottomStdDev "Standard deviation of the ACCS bottom angle of object(dimensionless)";
CM_ SG_ 186 VFC_Obj05A_NormVx "Normalised object velocity in longitudinal direction.";
CM_ SG_ 186 VFC_Obj05A_NormAx "Normalised object acceleration in longitudinal direction.";
CM_ SG_ 186 VFC_Obj05A_NormAxStdDev "Standard deviation of Normalized Object Acceleration in longitudinal direction";
CM_ SG_ 186 VFC_Obj05A_ProbMovingLat "Probability of object moving laterally";
CM_ SG_ 186 VFC_Obj05A_ID "Unique Object ID";
CM_ SG_ 186 VFC_Obj05A_NormVxStdDev "Standard deviation of Normalized Object Velocity in longitudinal direction";
CM_ SG_ 186 VFC_Obj05A_ProbMovingLong "Probability of object moving longitudinally";
CM_ SG_ 186 VFC_Obj05A_Vx "Object Velocity in longitudinal direction";
CM_ SG_ 186 VFC_Obj05A_Dx "Object Position in longitudinal direction";
CM_ SG_ 186 VFC_Obj05A_Dy "Object Position in lateral direction";
CM_ SG_ 186 VFC_Obj05A_Vy "Object Velocity in lateral direction";
CM_ SG_ 186 VFC_Obj05A_Ay "Object Acceleration in lateral direction";
CM_ SG_ 187 VFC_Obj05B_CRC "CRC - Autosar E2E Profile 5";
CM_ SG_ 187 VFC_Obj05B_TTIPC "Inverse TTI";
CM_ SG_ 187 VFC_Obj05B_TTIPC_StdDev "Inverse TTI standard deviation";
CM_ SG_ 187 VFC_Obj05B_AliveCtr "Alive counter - Autosar E2E Profile 5";
CM_ SG_ 187 VFC_Obj05B_BlockCtr "Protocol-Signal: Block Counter";
CM_ SG_ 187 VFC_Obj05B_ScaleChange "A scale change of of the detected object";
CM_ SG_ 187 VFC_Obj05B_ScaleChngStdDev "Standard deviation of object scale change";
CM_ SG_ 187 VFC_Obj05B_LineEdgeRightEgo "ObjLineEdgeAngle refers to the line which limits the host vehicle lane on the right side";
CM_ SG_ 187 VFC_Obj05B_LineEdgeLeftEgo "ObjLineEdgeAngle refers to the line which limits the host vehicle lane on the left side";
CM_ SG_ 187 VFC_Obj05B_CompletelyInImg "indicator if the object is completely measrued in the image";
CM_ SG_ 187 VFC_Obj05B_DirIndicator "The detected direction indicator lights";
CM_ SG_ 187 VFC_Obj05B_LineEdgeAngle "Angle between the video object's edge and the lane marking";
CM_ SG_ 187 VFC_Obj05B_BrakeLight "The number of detected lights. More confident if more lights are detected.";
CM_ SG_ 187 VFC_Obj05B_MeasSource "Bitmask for the measurement programs from which this object originates";
CM_ SG_ 187 VFC_Obj05B_AngLongitude "angular velocity with regarding to longitudinal direction";
CM_ SG_ 187 VFC_Obj05B_Reliab "Bitmask that indicates the algorithmic paths that have detected this object
NOT_RELIABLE=0 (Bit5==0)";
BA_DEF_ BO_  "GenMsgSendType" ENUM  "cyclic","NoMsgSendType","IfActive","Event","CA","CE";
BA_DEF_ BO_  "GenMsgCycleTime" INT 0 0;
BA_DEF_ SG_  "GenSigSendType" ENUM  "cyclic","OnChange","OnWrite","IfActive","OnChangeWithRepetition","OnWriteWithRepetition","IfActiveWithRepetition","CA","CE","Event";
BA_DEF_ SG_  "GenSigStartValue" INT 0 0;
BA_DEF_  "DBName" STRING ;
BA_DEF_ BO_  "CANFD_BRS" ENUM  "0","1";
BA_DEF_ BO_  "VFrameFormat" ENUM  "StandardCAN","ExtendedCAN","reserved","reserved","reserved","reserved","reserved","reserved","reserved","reserved","reserved","reserved","reserved","reserved","StandardCAN_FD","ExtendedCAN_FD";
BA_DEF_  "BusBaudateData" INT 0 10000;
BA_DEF_  "BusBaudateOther" INT 0 10000;
BA_DEF_ BO_  "GenMsgILSupport" ENUM  "No","Yes";
BA_DEF_  "BusType" STRING ;
BA_DEF_DEF_  "GenMsgSendType" "cyclic";
BA_DEF_DEF_  "GenMsgCycleTime" 0;
BA_DEF_DEF_  "GenSigSendType" "cyclic";
BA_DEF_DEF_  "GenSigStartValue" 0;
BA_DEF_DEF_  "DBName" "";
BA_DEF_DEF_  "CANFD_BRS" "1";
BA_DEF_DEF_  "VFrameFormat" "";
BA_DEF_DEF_  "BusBaudateData" 2;
BA_DEF_DEF_  "BusBaudateOther" 500;
BA_DEF_DEF_  "GenMsgILSupport" "Yes";
BA_DEF_DEF_  "BusType" "CAN FD";
BA_ "DBName" "CA_1R1V_privatecan_V14_1130_ni";
BA_ "GenMsgCycleTime" BO_ 149 20;
BA_ "VFrameFormat" BO_ 149 14;
BA_ "GenMsgCycleTime" BO_ 144 40;
BA_ "VFrameFormat" BO_ 144 14;
BA_ "GenMsgCycleTime" BO_ 80 50;
BA_ "VFrameFormat" BO_ 80 14;
BA_ "GenMsgSendType" BO_ 128 3;
BA_ "VFrameFormat" BO_ 128 14;
BA_ "GenMsgSendType" BO_ 129 3;
BA_ "VFrameFormat" BO_ 129 14;
BA_ "GenMsgSendType" BO_ 130 3;
BA_ "VFrameFormat" BO_ 130 14;
BA_ "GenMsgSendType" BO_ 131 3;
BA_ "VFrameFormat" BO_ 131 14;
BA_ "GenMsgSendType" BO_ 132 3;
BA_ "VFrameFormat" BO_ 132 14;
BA_ "GenMsgSendType" BO_ 133 3;
BA_ "VFrameFormat" BO_ 133 14;
BA_ "GenMsgSendType" BO_ 134 3;
BA_ "VFrameFormat" BO_ 134 14;
BA_ "GenMsgSendType" BO_ 135 3;
BA_ "VFrameFormat" BO_ 135 14;
BA_ "GenMsgSendType" BO_ 136 3;
BA_ "VFrameFormat" BO_ 136 14;
BA_ "GenMsgSendType" BO_ 160 3;
BA_ "VFrameFormat" BO_ 160 14;
BA_ "GenMsgSendType" BO_ 176 3;
BA_ "VFrameFormat" BO_ 176 14;
BA_ "GenMsgSendType" BO_ 177 3;
BA_ "VFrameFormat" BO_ 177 14;
BA_ "GenMsgSendType" BO_ 178 3;
BA_ "VFrameFormat" BO_ 178 14;
BA_ "GenMsgSendType" BO_ 179 3;
BA_ "VFrameFormat" BO_ 179 14;
BA_ "GenMsgSendType" BO_ 180 3;
BA_ "VFrameFormat" BO_ 180 14;
BA_ "GenMsgSendType" BO_ 181 3;
BA_ "VFrameFormat" BO_ 181 14;
BA_ "GenMsgSendType" BO_ 182 3;
BA_ "VFrameFormat" BO_ 182 14;
BA_ "GenMsgSendType" BO_ 183 3;
BA_ "VFrameFormat" BO_ 183 14;
BA_ "GenMsgSendType" BO_ 184 3;
BA_ "VFrameFormat" BO_ 184 14;
BA_ "GenMsgSendType" BO_ 185 3;
BA_ "VFrameFormat" BO_ 185 14;
BA_ "GenMsgSendType" BO_ 186 3;
BA_ "VFrameFormat" BO_ 186 14;
BA_ "GenMsgSendType" BO_ 187 3;
BA_ "VFrameFormat" BO_ 187 14;
BA_ "GenSigStartValue" SG_ 3221225472 VFC_MapInfo_RoadCurv 2047;
BA_ "GenSigStartValue" SG_ 80 VFC_SensorState_VisionFault 1;
BA_ "GenSigStartValue" SG_ 80 VFC_SensorState_Status 1;
BA_ "GenSigStartValue" SG_ 80 VFC_SensorState_ProtocolVersion 773;
BA_ "GenSigStartValue" SG_ 129 VFC_Line01_Dy 2048;
BA_ "GenSigStartValue" SG_ 129 VFC_Line01_CurvChange 2048;
BA_ "GenSigStartValue" SG_ 129 VFC_Line01_Curv 4096;
BA_ "GenSigStartValue" SG_ 129 VFC_Line01_HeadingAngle 3277;
BA_ "GenSigStartValue" SG_ 130 VFC_Line02_Dy 2048;
BA_ "GenSigStartValue" SG_ 130 VFC_Line02_CurvChange 2048;
BA_ "GenSigStartValue" SG_ 130 VFC_Line02_Curv 4096;
BA_ "GenSigStartValue" SG_ 130 VFC_Line02_HeadingAngle 3277;
BA_ "GenSigStartValue" SG_ 131 VFC_Line03_Dy 2048;
BA_ "GenSigStartValue" SG_ 131 VFC_Line03_CurvChange 2048;
BA_ "GenSigStartValue" SG_ 131 VFC_Line03_Curv 4096;
BA_ "GenSigStartValue" SG_ 131 VFC_Line03_HeadingAngle 3277;
BA_ "GenSigStartValue" SG_ 132 VFC_Line04_Dy 2048;
BA_ "GenSigStartValue" SG_ 132 VFC_Line04_CurvChange 2048;
BA_ "GenSigStartValue" SG_ 132 VFC_Line04_Curv 4096;
BA_ "GenSigStartValue" SG_ 132 VFC_Line04_HeadingAngle 3277;
BA_ "GenSigStartValue" SG_ 133 VFC_Line05_Dy 2048;
BA_ "GenSigStartValue" SG_ 133 VFC_Line05_CurvChange 2048;
BA_ "GenSigStartValue" SG_ 133 VFC_Line05_Curv 4096;
BA_ "GenSigStartValue" SG_ 133 VFC_Line05_HeadingAngle 3277;
BA_ "GenSigStartValue" SG_ 134 VFC_Line06_Dy 2048;
BA_ "GenSigStartValue" SG_ 134 VFC_Line06_CurvChange 2048;
BA_ "GenSigStartValue" SG_ 134 VFC_Line06_Curv 4096;
BA_ "GenSigStartValue" SG_ 134 VFC_Line06_HeadingAngle 3277;
BA_ "GenSigStartValue" SG_ 135 VFC_Line07_Dy 2048;
BA_ "GenSigStartValue" SG_ 135 VFC_Line07_CurvChange 2048;
BA_ "GenSigStartValue" SG_ 135 VFC_Line07_Curv 4096;
BA_ "GenSigStartValue" SG_ 135 VFC_Line07_HeadingAngle 3277;
BA_ "GenSigStartValue" SG_ 136 VFC_Line08_Dy 2048;
BA_ "GenSigStartValue" SG_ 136 VFC_Line08_CurvChange 2048;
BA_ "GenSigStartValue" SG_ 136 VFC_Line08_Curv 4096;
BA_ "GenSigStartValue" SG_ 136 VFC_Line08_HeadingAngle 3277;
BA_ "GenSigStartValue" SG_ 160 VFC_ObjHdr_CalibYawAngle 400;
BA_ "GenSigStartValue" SG_ 160 VFC_ObjHdr_MountPosX 4000;
BA_ "GenSigStartValue" SG_ 160 VFC_ObjHdr_MountPosY 2000;
BA_ "GenSigStartValue" SG_ 160 VFC_ObjHdr_CalibPitchAngle 400;
BA_ "GenSigStartValue" SG_ 160 VFC_ObjHdr_CalibRollAngle 400;
BA_ "GenSigStartValue" SG_ 176 VFC_Obj00A_PhiLeft 4000;
BA_ "GenSigStartValue" SG_ 176 VFC_Obj00A_Heading 157;
BA_ "GenSigStartValue" SG_ 176 VFC_Obj00A_PhiMid 4000;
BA_ "GenSigStartValue" SG_ 176 VFC_Obj00A_PhiRight 4000;
BA_ "GenSigStartValue" SG_ 176 VFC_Obj00A_PhiLeftVel 4000;
BA_ "GenSigStartValue" SG_ 176 VFC_Obj00A_PhiRightVel 4000;
BA_ "GenSigStartValue" SG_ 176 VFC_Obj00A_PhiTop 1600;
BA_ "GenSigStartValue" SG_ 176 VFC_Obj00A_PhiBottom 1600;
BA_ "GenSigStartValue" SG_ 176 VFC_Obj00A_Ax 160;
BA_ "GenSigStartValue" SG_ 176 VFC_Obj00A_NormVx 40000;
BA_ "GenSigStartValue" SG_ 176 VFC_Obj00A_NormAx 5000;
BA_ "GenSigStartValue" SG_ 176 VFC_Obj00A_Vx 1540;
BA_ "GenSigStartValue" SG_ 176 VFC_Obj00A_Dy 8000;
BA_ "GenSigStartValue" SG_ 176 VFC_Obj00A_Vy 500;
BA_ "GenSigStartValue" SG_ 176 VFC_Obj00A_Ay 120;
BA_ "GenSigStartValue" SG_ 177 VFC_Obj00B_LineEdgeAngle 4000;
BA_ "GenSigStartValue" SG_ 177 VFC_Obj00B_AngLongitude 500;
BA_ "GenSigStartValue" SG_ 178 VFC_Obj01A_PhiLeft 4000;
BA_ "GenSigStartValue" SG_ 178 VFC_Obj01A_Heading 157;
BA_ "GenSigStartValue" SG_ 178 VFC_Obj01A_PhiMid 4000;
BA_ "GenSigStartValue" SG_ 178 VFC_Obj01A_PhiRight 4000;
BA_ "GenSigStartValue" SG_ 178 VFC_Obj01A_PhiLeftVel 4000;
BA_ "GenSigStartValue" SG_ 178 VFC_Obj01A_PhiRightVel 4000;
BA_ "GenSigStartValue" SG_ 178 VFC_Obj01A_PhiTop 1600;
BA_ "GenSigStartValue" SG_ 178 VFC_Obj01A_PhiBottom 1600;
BA_ "GenSigStartValue" SG_ 178 VFC_Obj01A_Ax 160;
BA_ "GenSigStartValue" SG_ 178 VFC_Obj01A_NormVx 40000;
BA_ "GenSigStartValue" SG_ 178 VFC_Obj01A_NormAx 5000;
BA_ "GenSigStartValue" SG_ 178 VFC_Obj01A_Vx 1540;
BA_ "GenSigStartValue" SG_ 178 VFC_Obj01A_Dy 8000;
BA_ "GenSigStartValue" SG_ 178 VFC_Obj01A_Vy 500;
BA_ "GenSigStartValue" SG_ 178 VFC_Obj01A_Ay 120;
BA_ "GenSigStartValue" SG_ 179 VFC_Obj01B_LineEdgeAngle 4000;
BA_ "GenSigStartValue" SG_ 179 VFC_Obj01B_AngLongitude 500;
BA_ "GenSigStartValue" SG_ 180 VFC_Obj02A_PhiLeft 4000;
BA_ "GenSigStartValue" SG_ 180 VFC_Obj02A_Heading 157;
BA_ "GenSigStartValue" SG_ 180 VFC_Obj02A_PhiMid 4000;
BA_ "GenSigStartValue" SG_ 180 VFC_Obj02A_PhiRight 4000;
BA_ "GenSigStartValue" SG_ 180 VFC_Obj02A_PhiLeftVel 4000;
BA_ "GenSigStartValue" SG_ 180 VFC_Obj02A_PhiRightVel 4000;
BA_ "GenSigStartValue" SG_ 180 VFC_Obj02A_PhiTop 1600;
BA_ "GenSigStartValue" SG_ 180 VFC_Obj02A_PhiBottom 1600;
BA_ "GenSigStartValue" SG_ 180 VFC_Obj02A_Ax 160;
BA_ "GenSigStartValue" SG_ 180 VFC_Obj02A_NormVx 40000;
BA_ "GenSigStartValue" SG_ 180 VFC_Obj02A_NormAx 5000;
BA_ "GenSigStartValue" SG_ 180 VFC_Obj02A_Vx 1540;
BA_ "GenSigStartValue" SG_ 180 VFC_Obj02A_Dy 8000;
BA_ "GenSigStartValue" SG_ 180 VFC_Obj02A_Vy 500;
BA_ "GenSigStartValue" SG_ 180 VFC_Obj02A_Ay 120;
BA_ "GenSigStartValue" SG_ 181 VFC_Obj02B_LineEdgeAngle 4000;
BA_ "GenSigStartValue" SG_ 181 VFC_Obj02B_AngLongitude 500;
BA_ "GenSigStartValue" SG_ 182 VFC_Obj03A_PhiLeft 4000;
BA_ "GenSigStartValue" SG_ 182 VFC_Obj03A_Heading 157;
BA_ "GenSigStartValue" SG_ 182 VFC_Obj03A_PhiMid 4000;
BA_ "GenSigStartValue" SG_ 182 VFC_Obj03A_PhiRight 4000;
BA_ "GenSigStartValue" SG_ 182 VFC_Obj03A_PhiLeftVel 4000;
BA_ "GenSigStartValue" SG_ 182 VFC_Obj03A_PhiRightVel 4000;
BA_ "GenSigStartValue" SG_ 182 VFC_Obj03A_PhiTop 1600;
BA_ "GenSigStartValue" SG_ 182 VFC_Obj03A_PhiBottom 1600;
BA_ "GenSigStartValue" SG_ 182 VFC_Obj03A_Ax 160;
BA_ "GenSigStartValue" SG_ 182 VFC_Obj03A_NormVx 40000;
BA_ "GenSigStartValue" SG_ 182 VFC_Obj03A_NormAx 5000;
BA_ "GenSigStartValue" SG_ 182 VFC_Obj03A_Vx 1540;
BA_ "GenSigStartValue" SG_ 182 VFC_Obj03A_Dy 8000;
BA_ "GenSigStartValue" SG_ 182 VFC_Obj03A_Vy 500;
BA_ "GenSigStartValue" SG_ 182 VFC_Obj03A_Ay 120;
BA_ "GenSigStartValue" SG_ 183 VFC_Obj03B_LineEdgeAngle 4000;
BA_ "GenSigStartValue" SG_ 183 VFC_Obj03B_AngLongitude 500;
BA_ "GenSigStartValue" SG_ 184 VFC_Obj04A_PhiLeft 4000;
BA_ "GenSigStartValue" SG_ 184 VFC_Obj04A_Heading 157;
BA_ "GenSigStartValue" SG_ 184 VFC_Obj04A_PhiMid 4000;
BA_ "GenSigStartValue" SG_ 184 VFC_Obj04A_PhiRight 4000;
BA_ "GenSigStartValue" SG_ 184 VFC_Obj04A_PhiLeftVel 4000;
BA_ "GenSigStartValue" SG_ 184 VFC_Obj04A_PhiRightVel 4000;
BA_ "GenSigStartValue" SG_ 184 VFC_Obj04A_PhiTop 1600;
BA_ "GenSigStartValue" SG_ 184 VFC_Obj04A_PhiBottom 1600;
BA_ "GenSigStartValue" SG_ 184 VFC_Obj04A_Ax 160;
BA_ "GenSigStartValue" SG_ 184 VFC_Obj04A_NormVx 40000;
BA_ "GenSigStartValue" SG_ 184 VFC_Obj04A_NormAx 5000;
BA_ "GenSigStartValue" SG_ 184 VFC_Obj04A_Vx 1540;
BA_ "GenSigStartValue" SG_ 184 VFC_Obj04A_Dy 8000;
BA_ "GenSigStartValue" SG_ 184 VFC_Obj04A_Vy 500;
BA_ "GenSigStartValue" SG_ 184 VFC_Obj04A_Ay 120;
BA_ "GenSigStartValue" SG_ 185 VFC_Obj04B_LineEdgeAngle 4000;
BA_ "GenSigStartValue" SG_ 185 VFC_Obj04B_AngLongitude 500;
BA_ "GenSigStartValue" SG_ 186 VFC_Obj05A_PhiLeft 4000;
BA_ "GenSigStartValue" SG_ 186 VFC_Obj05A_Heading 157;
BA_ "GenSigStartValue" SG_ 186 VFC_Obj05A_PhiMid 4000;
BA_ "GenSigStartValue" SG_ 186 VFC_Obj05A_PhiRight 4000;
BA_ "GenSigStartValue" SG_ 186 VFC_Obj05A_PhiLeftVel 4000;
BA_ "GenSigStartValue" SG_ 186 VFC_Obj05A_PhiRightVel 4000;
BA_ "GenSigStartValue" SG_ 186 VFC_Obj05A_PhiTop 1600;
BA_ "GenSigStartValue" SG_ 186 VFC_Obj05A_PhiBottom 1600;
BA_ "GenSigStartValue" SG_ 186 VFC_Obj05A_Ax 160;
BA_ "GenSigStartValue" SG_ 186 VFC_Obj05A_NormVx 40000;
BA_ "GenSigStartValue" SG_ 186 VFC_Obj05A_NormAx 5000;
BA_ "GenSigStartValue" SG_ 186 VFC_Obj05A_Vx 1540;
BA_ "GenSigStartValue" SG_ 186 VFC_Obj05A_Dy 8000;
BA_ "GenSigStartValue" SG_ 186 VFC_Obj05A_Vy 500;
BA_ "GenSigStartValue" SG_ 186 VFC_Obj05A_Ay 120;
BA_ "GenSigStartValue" SG_ 187 VFC_Obj05B_LineEdgeAngle 4000;
BA_ "GenSigStartValue" SG_ 187 VFC_Obj05B_AngLongitude 500;
VAL_ 3221225472 VFC_MapInfo_CountryCode 0 "Unknown" 156 "CN=156" ;
VAL_ 3221225472 VFC_MapInfo_RoadClass_Offset0 0 "Unknown" 1 "Class 1" 2 "Class 2" 3 "Class 3" 4 "Class 4" 5 "Class 5" 6 "Class 6" 7 "SNA" ;
VAL_ 3221225472 VFC_MapInfo_RoadClass_Offset200 0 "Unknown" 1 "Class 1" 2 "Class 2" 3 "Class 3" 4 "Class 4" 5 "Class 5" 6 "Class 6" 7 "SNA" ;
VAL_ 3221225472 VFC_MapInfo_DiRoad_Offset0 0 "False" 1 "True" 2 "Unknown" 3 "Invalid" ;
VAL_ 3221225472 VFC_MapInfo_LaneNum_Offset0 0 "Wrong direction" 1 "1 lane" 2 "2 lanes" 3 "3 lanes" 4 "4 lanes" 5 "5 lanes" 6 "6 or more lanes" 7 "Unknown" ;
VAL_ 3221225472 VFC_MapInfo_LaneNum_Offset200 0 "Wrong direction" 1 "1 lane" 2 "2 lanes" 3 "3 lanes" 4 "4 lanes" 5 "5 lanes" 6 "6 or more lanes" 7 "Unknown" ;
VAL_ 3221225472 VFC_MapInfo_DiRoad_Offset200 0 "False" 1 "True" 2 "Unknown" 3 "Invalid" ;
VAL_ 3221225472 VFC_MapInfo_TollGate 0 "not in the segment" 1 "in the segment" 2 "unknown" 3 "reserved" ;
VAL_ 3221225472 VFC_MapInfo_CurrentLane 0 "Unknown" 1 "Emergency lane" 2 "Signal lane road" 3 "left most lane" 4 "right most lane" 5 "mid-lane within 3 or mare lanes" 6 "reserved" 7 "N/A" ;
VAL_ 3221225472 VFC_MapInfo_Tunnel 0 "not in the segment" 1 "in the segment" 2 "unknown" 3 "reserved" ;
VAL_ 3221225472 VFC_MapInfo_Bridge 0 "not in the segment" 1 "in the segment" 2 "unknown" 3 "reserved" ;
VAL_ 3221225472 VFC_MapInfo_BuildUp 0 "not in the segment" 1 "in the segment" 2 "unknown" 3 "reserved" ;
VAL_ 149 ACC_AEBActive 1 "Active" 0 "not Active" ;
VAL_ 144 RDR_Stat_ACCSwitchButton 0 "Not_Pressed" 1 "Pressed" 2 "Dummy" 3 "Error" ;
VAL_ 144 RDR_Stat_Avail 15 "All function not available" 14 "TIPL&Traj&ongoing not available" 13 "TIPL&Traj&oncom not available" 12 "TIPL&Traj not available" 11 "TIPL&oncoming&ongo not available" 10 "Tipl&ongoing not available" 9 "Tipl&oncoming not available" 8 "TiPl not available" 7 "Traj&oncom&ongoing not available" 6 "Traj&Ongoing not available" 5 "Traj&Oncoming not available" 4 "TrajPoint not available" 3 "OnCom&Ongo obj not available" 2 "Ongoing obj not available" 1 "OnComing obj not available" 0 "Available" ;
VAL_ 80 VFC_SensorState_SWVersion 3 "reserved" 2 "unknown" 1 "above 150" 0 "FV150" ;
VAL_ 80 VFC_SensorState_VisionFault 0 "Camera Operational" 1 "Camera Initialization" 2 "Camera Limited (reduced Mode)" 3 "Reserved" 4 "Camera Blocked" 5 "Camera Error" 6 "Camera Calibration/Dalibration" 7 "Reserved" ;
VAL_ 80 VFC_SensorState_Status 0 "off" 1 "on" 2 "Reduced" 3 "HW_Error" 4 "SW_Error" 5 "FID_Active" 6 "Reserved6" 7 "Reserved7" ;
VAL_ 128 VFC_LineHdr_Report 1 "INVALID_BET_INPUT" 2 "INVALID_MOPED_INPUT" 4 "INVALID_MOFU_INPUT" 8 "NO_LBSEGS" 16 "INVALID_YAW_RATE" 32 "INVALID_YAW_ANGLE" 64 "INVALID_VELOCITY" 128 "INVALID_TIMESTAMP" ;
VAL_ 128 VFC_LineHdr_State 0 "off" 1 "on" 2 "Reduced" 3 "HW_Error" 4 "SW_Error" 5 "FID_Active" 6 "Reserved6" 7 "Reserved7" ;
VAL_ 129 VFC_Line01_MeasureType 0 "MTYPE_MEASURED" 1 "MTYPE_VIRTUAL" 2 "MTYPE_INTERPOLATED" 3 "MTYPE_UNKNOWN" ;
VAL_ 129 VFC_Line01_Type 0 "TYPE_SOLID_LINE" 1 "TYPE_DASHED_LINE" 2 "TYPE_DOUBLE_DASHED_DASHED" 3 "TYPE_DOUBLE_DASHED_SOLID" 4 "TYPE_DOUBLE_SOLID_DASHED" 5 "TYPE_DOUBLE_SOLID_SOLID" 6 "TYPE_MULTIPLE" 7 "TYPE_MULTIPLE_WARNING" 8 "TYPE_CAR_POOL" 9 "TYPE_ASPHALT_JOINT" 10 "TYPE_BOTTS_DOTS" 11 "TYPE_ROAD_EDGE" 12 "TYPE_GUARDRAIL" 13 "TYPE_CURBSTONE" 14 "TYPE_WALL" 15 "TYPE_TRAFFIC_CONE" 16 "TYPE_DELINEATOR_POST" 17 "TYPE_PARKING_CAR" 18 "TYPE_UNKNOWN_RAISED" 19 "TYPE_UNKNOWN" ;
VAL_ 129 VFC_Line01_LaneRelation 0 "LEFT_EGO_LINE" 1 "RIGHT_EGO_LINE" 2 "LEFT_LEFT_LINE" 3 "RIGHT_RIGHT_LINE" 4 "ROAD_EDGE_LEFT" 5 "ROAD_EDGE_RIGHT" 6 "RAISED_LEFT" 7 "RAISED_RIGHT" ;
VAL_ 129 VFC_Line01_ColorClass 0 "COLOR_WHITE" 1 "COLOR_YELLOW" 2 "COLOR_RED" 3 "COLOR_BLUE" 7 "COLOR_UNKNOWN" ;
VAL_ 130 VFC_Line02_MeasureType 0 "MTYPE_MEASURED" 1 "MTYPE_VIRTUAL" 2 "MTYPE_INTERPOLATED" 3 "MTYPE_UNKNOWN" ;
VAL_ 130 VFC_Line02_Type 0 "TYPE_SOLID_LINE" 1 "TYPE_DASHED_LINE" 2 "TYPE_DOUBLE_DASHED_DASHED" 3 "TYPE_DOUBLE_DASHED_SOLID" 4 "TYPE_DOUBLE_SOLID_DASHED" 5 "TYPE_DOUBLE_SOLID_SOLID" 6 "TYPE_MULTIPLE" 7 "TYPE_MULTIPLE_WARNING" 8 "TYPE_CAR_POOL" 9 "TYPE_ASPHALT_JOINT" 10 "TYPE_BOTTS_DOTS" 11 "TYPE_ROAD_EDGE" 12 "TYPE_GUARDRAIL" 13 "TYPE_CURBSTONE" 14 "TYPE_WALL" 15 "TYPE_TRAFFIC_CONE" 16 "TYPE_DELINEATOR_POST" 17 "TYPE_PARKING_CAR" 18 "TYPE_UNKNOWN_RAISED" 19 "TYPE_UNKNOWN" ;
VAL_ 130 VFC_Line02_LaneRelation 0 "LEFT_EGO_LINE" 1 "RIGHT_EGO_LINE" 2 "LEFT_LEFT_LINE" 3 "RIGHT_RIGHT_LINE" 4 "ROAD_EDGE_LEFT" 5 "ROAD_EDGE_RIGHT" 6 "RAISED_LEFT" 7 "RAISED_RIGHT" ;
VAL_ 130 VFC_Line02_ColorClass 0 "COLOR_WHITE" 1 "COLOR_YELLOW" 2 "COLOR_RED" 3 "COLOR_BLUE" 7 "COLOR_UNKNOWN" ;
VAL_ 131 VFC_Line03_MeasureType 0 "MTYPE_MEASURED" 1 "MTYPE_VIRTUAL" 2 "MTYPE_INTERPOLATED" 3 "MTYPE_UNKNOWN" ;
VAL_ 131 VFC_Line03_Type 0 "TYPE_SOLID_LINE" 1 "TYPE_DASHED_LINE" 2 "TYPE_DOUBLE_DASHED_DASHED" 3 "TYPE_DOUBLE_DASHED_SOLID" 4 "TYPE_DOUBLE_SOLID_DASHED" 5 "TYPE_DOUBLE_SOLID_SOLID" 6 "TYPE_MULTIPLE" 7 "TYPE_MULTIPLE_WARNING" 8 "TYPE_CAR_POOL" 9 "TYPE_ASPHALT_JOINT" 10 "TYPE_BOTTS_DOTS" 11 "TYPE_ROAD_EDGE" 12 "TYPE_GUARDRAIL" 13 "TYPE_CURBSTONE" 14 "TYPE_WALL" 15 "TYPE_TRAFFIC_CONE" 16 "TYPE_DELINEATOR_POST" 17 "TYPE_PARKING_CAR" 18 "TYPE_UNKNOWN_RAISED" 19 "TYPE_UNKNOWN" ;
VAL_ 131 VFC_Line03_LaneRelation 0 "LEFT_EGO_LINE" 1 "RIGHT_EGO_LINE" 2 "LEFT_LEFT_LINE" 3 "RIGHT_RIGHT_LINE" 4 "ROAD_EDGE_LEFT" 5 "ROAD_EDGE_RIGHT" 6 "RAISED_LEFT" 7 "RAISED_RIGHT" ;
VAL_ 131 VFC_Line03_ColorClass 0 "COLOR_WHITE" 1 "COLOR_YELLOW" 2 "COLOR_RED" 3 "COLOR_BLUE" 7 "COLOR_UNKNOWN" ;
VAL_ 132 VFC_Line04_MeasureType 0 "MTYPE_MEASURED" 1 "MTYPE_VIRTUAL" 2 "MTYPE_INTERPOLATED" 3 "MTYPE_UNKNOWN" ;
VAL_ 132 VFC_Line04_Type 0 "TYPE_SOLID_LINE" 1 "TYPE_DASHED_LINE" 2 "TYPE_DOUBLE_DASHED_DASHED" 3 "TYPE_DOUBLE_DASHED_SOLID" 4 "TYPE_DOUBLE_SOLID_DASHED" 5 "TYPE_DOUBLE_SOLID_SOLID" 6 "TYPE_MULTIPLE" 7 "TYPE_MULTIPLE_WARNING" 8 "TYPE_CAR_POOL" 9 "TYPE_ASPHALT_JOINT" 10 "TYPE_BOTTS_DOTS" 11 "TYPE_ROAD_EDGE" 12 "TYPE_GUARDRAIL" 13 "TYPE_CURBSTONE" 14 "TYPE_WALL" 15 "TYPE_TRAFFIC_CONE" 16 "TYPE_DELINEATOR_POST" 17 "TYPE_PARKING_CAR" 18 "TYPE_UNKNOWN_RAISED" 19 "TYPE_UNKNOWN" ;
VAL_ 132 VFC_Line04_LaneRelation 0 "LEFT_EGO_LINE" 1 "RIGHT_EGO_LINE" 2 "LEFT_LEFT_LINE" 3 "RIGHT_RIGHT_LINE" 4 "ROAD_EDGE_LEFT" 5 "ROAD_EDGE_RIGHT" 6 "RAISED_LEFT" 7 "RAISED_RIGHT" ;
VAL_ 132 VFC_Line04_ColorClass 0 "COLOR_WHITE" 1 "COLOR_YELLOW" 2 "COLOR_RED" 3 "COLOR_BLUE" 7 "COLOR_UNKNOWN" ;
VAL_ 133 VFC_Line05_MeasureType 0 "MTYPE_MEASURED" 1 "MTYPE_VIRTUAL" 2 "MTYPE_INTERPOLATED" 3 "MTYPE_UNKNOWN" ;
VAL_ 133 VFC_Line05_Type 0 "TYPE_SOLID_LINE" 1 "TYPE_DASHED_LINE" 2 "TYPE_DOUBLE_DASHED_DASHED" 3 "TYPE_DOUBLE_DASHED_SOLID" 4 "TYPE_DOUBLE_SOLID_DASHED" 5 "TYPE_DOUBLE_SOLID_SOLID" 6 "TYPE_MULTIPLE" 7 "TYPE_MULTIPLE_WARNING" 8 "TYPE_CAR_POOL" 9 "TYPE_ASPHALT_JOINT" 10 "TYPE_BOTTS_DOTS" 11 "TYPE_ROAD_EDGE" 12 "TYPE_GUARDRAIL" 13 "TYPE_CURBSTONE" 14 "TYPE_WALL" 15 "TYPE_TRAFFIC_CONE" 16 "TYPE_DELINEATOR_POST" 17 "TYPE_PARKING_CAR" 18 "TYPE_UNKNOWN_RAISED" 19 "TYPE_UNKNOWN" ;
VAL_ 133 VFC_Line05_LaneRelation 0 "LEFT_EGO_LINE" 1 "RIGHT_EGO_LINE" 2 "LEFT_LEFT_LINE" 3 "RIGHT_RIGHT_LINE" 4 "ROAD_EDGE_LEFT" 5 "ROAD_EDGE_RIGHT" 6 "RAISED_LEFT" 7 "RAISED_RIGHT" ;
VAL_ 133 VFC_Line05_ColorClass 0 "COLOR_WHITE" 1 "COLOR_YELLOW" 2 "COLOR_RED" 3 "COLOR_BLUE" 7 "COLOR_UNKNOWN" ;
VAL_ 134 VFC_Line06_MeasureType 0 "MTYPE_MEASURED" 1 "MTYPE_VIRTUAL" 2 "MTYPE_INTERPOLATED" 3 "MTYPE_UNKNOWN" ;
VAL_ 134 VFC_Line06_Type 0 "TYPE_SOLID_LINE" 1 "TYPE_DASHED_LINE" 2 "TYPE_DOUBLE_DASHED_DASHED" 3 "TYPE_DOUBLE_DASHED_SOLID" 4 "TYPE_DOUBLE_SOLID_DASHED" 5 "TYPE_DOUBLE_SOLID_SOLID" 6 "TYPE_MULTIPLE" 7 "TYPE_MULTIPLE_WARNING" 8 "TYPE_CAR_POOL" 9 "TYPE_ASPHALT_JOINT" 10 "TYPE_BOTTS_DOTS" 11 "TYPE_ROAD_EDGE" 12 "TYPE_GUARDRAIL" 13 "TYPE_CURBSTONE" 14 "TYPE_WALL" 15 "TYPE_TRAFFIC_CONE" 16 "TYPE_DELINEATOR_POST" 17 "TYPE_PARKING_CAR" 18 "TYPE_UNKNOWN_RAISED" 19 "TYPE_UNKNOWN" ;
VAL_ 134 VFC_Line06_LaneRelation 0 "LEFT_EGO_LINE" 1 "RIGHT_EGO_LINE" 2 "LEFT_LEFT_LINE" 3 "RIGHT_RIGHT_LINE" 4 "ROAD_EDGE_LEFT" 5 "ROAD_EDGE_RIGHT" 6 "RAISED_LEFT" 7 "RAISED_RIGHT" ;
VAL_ 134 VFC_Line06_ColorClass 0 "COLOR_WHITE" 1 "COLOR_YELLOW" 2 "COLOR_RED" 3 "COLOR_BLUE" 7 "COLOR_UNKNOWN" ;
VAL_ 135 VFC_Line07_MeasureType 0 "MTYPE_MEASURED" 1 "MTYPE_VIRTUAL" 2 "MTYPE_INTERPOLATED" 3 "MTYPE_UNKNOWN" ;
VAL_ 135 VFC_Line07_Type 0 "TYPE_SOLID_LINE" 1 "TYPE_DASHED_LINE" 2 "TYPE_DOUBLE_DASHED_DASHED" 3 "TYPE_DOUBLE_DASHED_SOLID" 4 "TYPE_DOUBLE_SOLID_DASHED" 5 "TYPE_DOUBLE_SOLID_SOLID" 6 "TYPE_MULTIPLE" 7 "TYPE_MULTIPLE_WARNING" 8 "TYPE_CAR_POOL" 9 "TYPE_ASPHALT_JOINT" 10 "TYPE_BOTTS_DOTS" 11 "TYPE_ROAD_EDGE" 12 "TYPE_GUARDRAIL" 13 "TYPE_CURBSTONE" 14 "TYPE_WALL" 15 "TYPE_TRAFFIC_CONE" 16 "TYPE_DELINEATOR_POST" 17 "TYPE_PARKING_CAR" 18 "TYPE_UNKNOWN_RAISED" 19 "TYPE_UNKNOWN" ;
VAL_ 135 VFC_Line07_LaneRelation 0 "LEFT_EGO_LINE" 1 "RIGHT_EGO_LINE" 2 "LEFT_LEFT_LINE" 3 "RIGHT_RIGHT_LINE" 4 "ROAD_EDGE_LEFT" 5 "ROAD_EDGE_RIGHT" 6 "RAISED_LEFT" 7 "RAISED_RIGHT" ;
VAL_ 135 VFC_Line07_ColorClass 0 "COLOR_WHITE" 1 "COLOR_YELLOW" 2 "COLOR_RED" 3 "COLOR_BLUE" 7 "COLOR_UNKNOWN" ;
VAL_ 136 VFC_Line08_MeasureType 0 "MTYPE_MEASURED" 1 "MTYPE_VIRTUAL" 2 "MTYPE_INTERPOLATED" 3 "MTYPE_UNKNOWN" ;
VAL_ 136 VFC_Line08_Type 0 "TYPE_SOLID_LINE" 1 "TYPE_DASHED_LINE" 2 "TYPE_DOUBLE_DASHED_DASHED" 3 "TYPE_DOUBLE_DASHED_SOLID" 4 "TYPE_DOUBLE_SOLID_DASHED" 5 "TYPE_DOUBLE_SOLID_SOLID" 6 "TYPE_MULTIPLE" 7 "TYPE_MULTIPLE_WARNING" 8 "TYPE_CAR_POOL" 9 "TYPE_ASPHALT_JOINT" 10 "TYPE_BOTTS_DOTS" 11 "TYPE_ROAD_EDGE" 12 "TYPE_GUARDRAIL" 13 "TYPE_CURBSTONE" 14 "TYPE_WALL" 15 "TYPE_TRAFFIC_CONE" 16 "TYPE_DELINEATOR_POST" 17 "TYPE_PARKING_CAR" 18 "TYPE_UNKNOWN_RAISED" 19 "TYPE_UNKNOWN" ;
VAL_ 136 VFC_Line08_LaneRelation 0 "LEFT_EGO_LINE" 1 "RIGHT_EGO_LINE" 2 "LEFT_LEFT_LINE" 3 "RIGHT_RIGHT_LINE" 4 "ROAD_EDGE_LEFT" 5 "ROAD_EDGE_RIGHT" 6 "RAISED_LEFT" 7 "RAISED_RIGHT" ;
VAL_ 136 VFC_Line08_ColorClass 0 "COLOR_WHITE" 1 "COLOR_YELLOW" 2 "COLOR_RED" 3 "COLOR_BLUE" 7 "COLOR_UNKNOWN" ;
VAL_ 160 VFC_ObjHdr_Scenario 7 "reserved" 6 "reserved" 5 "Unknown" 4 "Twilghr" 3 "Tunnel_Entry" 2 "Tunnel" 1 "Night" 0 "Day light" ;
VAL_ 160 VFC_ObjHdr_CalibState 0 "Fully Calibrated" 1 "Not Calibrated" 2 "Yaw Not Calibrated" 3 "Pitch Not Calibrated" 4 "Roll Not Calibrated" 5 "Reserved5" 6 "Reserved6" 7 "Reserved7" ;
VAL_ 176 VFC_Obj00A_ClassifiedView 0 "Unknown" 1 "Front" 2 "Rear" 3 "Left" 4 "Right" ;
VAL_ 176 VFC_Obj00A_Measured 0 "Invalid" 1 "Predicted" 2 "Measured" 3 "Reserved" ;
VAL_ 176 VFC_Obj00A_VisibleView 0 "UNKNOWN" 1 "CLASSIC" 2 "SIDE" 3 "CLASSIC_SIDE" 4 "SIDE_CLASSIC" ;
VAL_ 176 VFC_Obj00A_HeadOrientation 14 "Reserved 2" 13 "Reserved 1" 12 "Head oppo left back right front" 11 "Head oppo left right" 10 "Head oppo let front right back" 9 "Head oppo front back " 0 "N/A" 1 "Head front" 2 "Head left front" 3 "Head left" 4 "Head left back" 5 "Head back" 6 "Head right back" 7 "Head right" 8 "Head right front" 15 "Unknown" ;
VAL_ 176 VFC_Obj00A_Type 0 "No type" 1 "Car" 2 "Truck" 3 "Motorcycle" 4 "Pedestrian" 5 "Cyclist" 6 "Animal" ;
VAL_ 177 VFC_Obj00B_LineEdgeRightEgo 0 "Right" 1 "Not Right" ;
VAL_ 177 VFC_Obj00B_LineEdgeLeftEgo 0 "Left" 1 "Not Left" ;
VAL_ 177 VFC_Obj00B_CompletelyInImg 0 "completely measured" 1 "not completely measured" ;
VAL_ 177 VFC_Obj00B_DirIndicator 0 "No direction indicator" 1 "Left indicator" 2 "Right indicator" 3 "Warning Lights" 4 "Unknown" ;
VAL_ 177 VFC_Obj00B_BrakeLight 0 "No light detected" 1 "One light detected" 2 "Two lights detected" 3 "Three lights detected" 4 "Unknown" ;
VAL_ 177 VFC_Obj00B_MeasSource 15 "Source_INVALID" 11 "Source_OLS" 10 "Source_FUSED" 0 "Source_GOD_Stereo" 1 "Source_MOD" 2 "Source_PDET" 4 "Source_GOD_MONO" ;
VAL_ 178 VFC_Obj01A_ClassifiedView 0 "Unknown" 1 "Front" 2 "Rear" 3 "Left" 4 "Right" ;
VAL_ 178 VFC_Obj01A_Measured 0 "Invalid" 1 "Predicted" 2 "Measured" 3 "Reserved" ;
VAL_ 178 VFC_Obj01A_VisibleView 0 "UNKNOWN" 1 "CLASSIC" 2 "SIDE" 3 "CLASSIC_SIDE" 4 "SIDE_CLASSIC" ;
VAL_ 178 VFC_Obj01A_HeadOrientation 14 "Reserved 2" 13 "Reserved 1" 12 "Head oppo left back right front" 11 "Head oppo left right" 10 "Head oppo let front right back" 9 "Head oppo front back " 0 "N/A" 1 "Head front" 2 "Head left front" 3 "Head left" 4 "Head left back" 5 "Head back" 6 "Head right back" 7 "Head right" 8 "Head right front" 15 "Unknown" ;
VAL_ 178 VFC_Obj01A_Type 0 "No type" 1 "Car" 2 "Truck" 3 "Motorcycle" 4 "Pedestrian" 5 "Cyclist" 6 "Animal" ;
VAL_ 179 VFC_Obj01B_LineEdgeRightEgo 0 "Right" 1 "Not Right" ;
VAL_ 179 VFC_Obj01B_LineEdgeLeftEgo 0 "Left" 1 "Not Left" ;
VAL_ 179 VFC_Obj01B_CompletelyInImg 0 "completely measured" 1 "not completely measured" ;
VAL_ 179 VFC_Obj01B_DirIndicator 0 "No direction indicator" 1 "Left indicator" 2 "Right indicator" 3 "Warning Lights" 4 "Unknown" ;
VAL_ 179 VFC_Obj01B_BrakeLight 0 "No light detected" 1 "One light detected" 2 "Two lights detected" 3 "Three lights detected" 4 "Unknown" ;
VAL_ 179 VFC_Obj01B_MeasSource 15 "Source_INVALID" 11 "Source_OLS" 10 "Source_FUSED" 0 "Source_GOD_Stereo" 1 "Source_MOD" 2 "Source_PDET" 4 "Source_GOD_MONO" ;
VAL_ 180 VFC_Obj02A_ClassifiedView 0 "Unknown" 1 "Front" 2 "Rear" 3 "Left" 4 "Right" ;
VAL_ 180 VFC_Obj02A_Measured 0 "Invalid" 1 "Predicted" 2 "Measured" 3 "Reserved" ;
VAL_ 180 VFC_Obj02A_VisibleView 0 "UNKNOWN" 1 "CLASSIC" 2 "SIDE" 3 "CLASSIC_SIDE" 4 "SIDE_CLASSIC" ;
VAL_ 180 VFC_Obj02A_HeadOrientation 14 "Reserved 2" 13 "Reserved 1" 12 "Head oppo left back right front" 11 "Head oppo left right" 10 "Head oppo let front right back" 9 "Head oppo front back " 0 "N/A" 1 "Head front" 2 "Head left front" 3 "Head left" 4 "Head left back" 5 "Head back" 6 "Head right back" 7 "Head right" 8 "Head right front" 15 "Unknown" ;
VAL_ 180 VFC_Obj02A_Type 0 "No type" 1 "Car" 2 "Truck" 3 "Motorcycle" 4 "Pedestrian" 5 "Cyclist" 6 "Animal" ;
VAL_ 181 VFC_Obj02B_LineEdgeRightEgo 0 "Right" 1 "Not Right" ;
VAL_ 181 VFC_Obj02B_LineEdgeLeftEgo 0 "Left" 1 "Not Left" ;
VAL_ 181 VFC_Obj02B_CompletelyInImg 0 "completely measured" 1 "not completely measured" ;
VAL_ 181 VFC_Obj02B_DirIndicator 0 "No direction indicator" 1 "Left indicator" 2 "Right indicator" 3 "Warning Lights" 4 "Unknown" ;
VAL_ 181 VFC_Obj02B_BrakeLight 0 "No light detected" 1 "One light detected" 2 "Two lights detected" 3 "Three lights detected" 4 "Unknown" ;
VAL_ 181 VFC_Obj02B_MeasSource 15 "Source_INVALID" 11 "Source_OLS" 10 "Source_FUSED" 0 "Source_GOD_Stereo" 1 "Source_MOD" 2 "Source_PDET" 4 "Source_GOD_MONO" ;
VAL_ 182 VFC_Obj03A_ClassifiedView 0 "Unknown" 1 "Front" 2 "Rear" 3 "Left" 4 "Right" ;
VAL_ 182 VFC_Obj03A_Measured 0 "Invalid" 1 "Predicted" 2 "Measured" 3 "Reserved" ;
VAL_ 182 VFC_Obj03A_VisibleView 0 "UNKNOWN" 1 "CLASSIC" 2 "SIDE" 3 "CLASSIC_SIDE" 4 "SIDE_CLASSIC" ;
VAL_ 182 VFC_Obj03A_HeadOrientation 14 "Reserved 2" 13 "Reserved 1" 12 "Head oppo left back right front" 11 "Head oppo left right" 10 "Head oppo let front right back" 9 "Head oppo front back " 0 "N/A" 1 "Head front" 2 "Head left front" 3 "Head left" 4 "Head left back" 5 "Head back" 6 "Head right back" 7 "Head right" 8 "Head right front" 15 "Unknown" ;
VAL_ 182 VFC_Obj03A_Type 0 "No type" 1 "Car" 2 "Truck" 3 "Motorcycle" 4 "Pedestrian" 5 "Cyclist" 6 "Animal" ;
VAL_ 183 VFC_Obj03B_LineEdgeRightEgo 0 "Right" 1 "Not Right" ;
VAL_ 183 VFC_Obj03B_LineEdgeLeftEgo 0 "Left" 1 "Not Left" ;
VAL_ 183 VFC_Obj03B_CompletelyInImg 0 "completely measured" 1 "not completely measured" ;
VAL_ 183 VFC_Obj03B_DirIndicator 0 "No direction indicator" 1 "Left indicator" 2 "Right indicator" 3 "Warning Lights" 4 "Unknown" ;
VAL_ 183 VFC_Obj03B_BrakeLight 0 "No light detected" 1 "One light detected" 2 "Two lights detected" 3 "Three lights detected" 4 "Unknown" ;
VAL_ 183 VFC_Obj03B_MeasSource 15 "Source_INVALID" 11 "Source_OLS" 10 "Source_FUSED" 0 "Source_GOD_Stereo" 1 "Source_MOD" 2 "Source_PDET" 4 "Source_GOD_MONO" ;
VAL_ 184 VFC_Obj04A_ClassifiedView 0 "Unknown" 1 "Front" 2 "Rear" 3 "Left" 4 "Right" ;
VAL_ 184 VFC_Obj04A_Measured 0 "Invalid" 1 "Predicted" 2 "Measured" 3 "Reserved" ;
VAL_ 184 VFC_Obj04A_VisibleView 0 "UNKNOWN" 1 "CLASSIC" 2 "SIDE" 3 "CLASSIC_SIDE" 4 "SIDE_CLASSIC" ;
VAL_ 184 VFC_Obj04A_HeadOrientation 14 "Reserved 2" 13 "Reserved 1" 12 "Head oppo left back right front" 11 "Head oppo left right" 10 "Head oppo let front right back" 9 "Head oppo front back " 0 "N/A" 1 "Head front" 2 "Head left front" 3 "Head left" 4 "Head left back" 5 "Head back" 6 "Head right back" 7 "Head right" 8 "Head right front" 15 "Unknown" ;
VAL_ 184 VFC_Obj04A_Type 0 "No type" 1 "Car" 2 "Truck" 3 "Motorcycle" 4 "Pedestrian" 5 "Cyclist" 6 "Animal" ;
VAL_ 185 VFC_Obj04B_LineEdgeRightEgo 0 "Right" 1 "Not Right" ;
VAL_ 185 VFC_Obj04B_LineEdgeLeftEgo 0 "Left" 1 "Not Left" ;
VAL_ 185 VFC_Obj04B_CompletelyInImg 0 "completely measured" 1 "not completely measured" ;
VAL_ 185 VFC_Obj04B_DirIndicator 0 "No direction indicator" 1 "Left indicator" 2 "Right indicator" 3 "Warning Lights" 4 "Unknown" ;
VAL_ 185 VFC_Obj04B_BrakeLight 0 "No light detected" 1 "One light detected" 2 "Two lights detected" 3 "Three lights detected" 4 "Unknown" ;
VAL_ 185 VFC_Obj04B_MeasSource 15 "Source_INVALID" 11 "Source_OLS" 10 "Source_FUSED" 0 "Source_GOD_Stereo" 1 "Source_MOD" 2 "Source_PDET" 4 "Source_GOD_MONO" ;
VAL_ 186 VFC_Obj05A_ClassifiedView 0 "Unknown" 1 "Front" 2 "Rear" 3 "Left" 4 "Right" ;
VAL_ 186 VFC_Obj05A_Measured 0 "Invalid" 1 "Predicted" 2 "Measured" 3 "Reserved" ;
VAL_ 186 VFC_Obj05A_VisibleView 0 "UNKNOWN" 1 "CLASSIC" 2 "SIDE" 3 "CLASSIC_SIDE" 4 "SIDE_CLASSIC" ;
VAL_ 186 VFC_Obj05A_HeadOrientation 14 "Reserved 2" 13 "Reserved 1" 12 "Head oppo left back right front" 11 "Head oppo left right" 10 "Head oppo let front right back" 9 "Head oppo front back " 0 "N/A" 1 "Head front" 2 "Head left front" 3 "Head left" 4 "Head left back" 5 "Head back" 6 "Head right back" 7 "Head right" 8 "Head right front" 15 "Unknown" ;
VAL_ 186 VFC_Obj05A_Type 0 "No type" 1 "Car" 2 "Truck" 3 "Motorcycle" 4 "Pedestrian" 5 "Cyclist" 6 "Animal" ;
VAL_ 187 VFC_Obj05B_LineEdgeRightEgo 0 "Right" 1 "Not Right" ;
VAL_ 187 VFC_Obj05B_LineEdgeLeftEgo 0 "Left" 1 "Not Left" ;
VAL_ 187 VFC_Obj05B_CompletelyInImg 0 "completely measured" 1 "not completely measured" ;
VAL_ 187 VFC_Obj05B_DirIndicator 0 "No direction indicator" 1 "Left indicator" 2 "Right indicator" 3 "Warning Lights" 4 "Unknown" ;
VAL_ 187 VFC_Obj05B_BrakeLight 0 "No light detected" 1 "One light detected" 2 "Two lights detected" 3 "Three lights detected" 4 "Unknown" ;
VAL_ 187 VFC_Obj05B_MeasSource 115 "Source_INVALID" 11 "Source_OLS" 10 "Source_FUSED" 0 "Source_GOD_Stereo" 1 "Source_MOD" 2 "Source_PDET" 4 "Source_GOD_MONO" ;
